VERSION ""

NS_ :

BS_:

BU_:

BO_ 2566834833 DM01_for_Multi_SA91: 42 Vector__XXX
 SG_ FECA_10_SPNConversionMethod : 335|1@1+ (1,0) [0|1] "" Vector__XXX
 SG_ FECA_10_SPN3 : 325|3@1+ (1,0) [0|7] "" Vector__XXX
 SG_ FECA_10_SPN1_2 : 304|16@1+ (1,0) [0|65535] "" Vector__XXX
 SG_ FECA_10_OccurenceCount : 328|7@1+ (1,0) [0|127] "" Vector__XXX
 SG_ FECA_10_FMI : 320|5@1+ (1,0) [0|31] "" Vector__XXX
 SG_ FECA_09_SPNConversionMethod : 303|1@1+ (1,0) [0|1] "" Vector__XXX
 SG_ FECA_09_SPN3 : 293|3@1+ (1,0) [0|7] "" Vector__XXX
 SG_ FECA_09_SPN1_2 : 272|16@1+ (1,0) [0|65535] "" Vector__XXX
 SG_ FECA_09_OccurenceCount : 296|7@1+ (1,0) [0|127] "" Vector__XXX
 SG_ FECA_09_FMI : 288|5@1+ (1,0) [0|31] "" Vector__XXX
 SG_ FECA_08_SPNConversionMethod : 271|1@1+ (1,0) [0|1] "" Vector__XXX
 SG_ FECA_08_SPN3 : 261|3@1+ (1,0) [0|7] "" Vector__XXX
 SG_ FECA_08_SPN1_2 : 240|16@1+ (1,0) [0|65535] "" Vector__XXX
 SG_ FECA_08_OccurenceCount : 264|7@1+ (1,0) [0|127] "" Vector__XXX
 SG_ FECA_08_FMI : 256|5@1+ (1,0) [0|31] "" Vector__XXX
 SG_ FECA_07_SPNConversionMethod : 239|1@1+ (1,0) [0|1] "" Vector__XXX
 SG_ FECA_07_SPN3 : 229|3@1+ (1,0) [0|7] "" Vector__XXX
 SG_ FECA_07_SPN1_2 : 208|16@1+ (1,0) [0|65535] "" Vector__XXX
 SG_ FECA_07_OccurenceCount : 232|7@1+ (1,0) [0|127] "" Vector__XXX
 SG_ FECA_07_FMI : 224|5@1+ (1,0) [0|31] "" Vector__XXX
 SG_ FECA_06_SPNConversionMethod : 207|1@1+ (1,0) [0|1] "" Vector__XXX
 SG_ FECA_06_SPN3 : 197|3@1+ (1,0) [0|7] "" Vector__XXX
 SG_ FECA_06_SPN1_2 : 176|16@1+ (1,0) [0|65535] "" Vector__XXX
 SG_ FECA_06_OccurenceCount : 200|7@1+ (1,0) [0|127] "" Vector__XXX
 SG_ FECA_06_FMI : 192|5@1+ (1,0) [0|31] "" Vector__XXX
 SG_ FECA_05_SPNConversionMethod : 175|1@1+ (1,0) [0|1] "" Vector__XXX
 SG_ FECA_05_SPN3 : 165|3@1+ (1,0) [0|7] "" Vector__XXX
 SG_ FECA_05_SPN1_2 : 144|16@1+ (1,0) [0|65535] "" Vector__XXX
 SG_ FECA_05_OccurenceCount : 168|7@1+ (1,0) [0|127] "" Vector__XXX
 SG_ FECA_05_FMI : 160|5@1+ (1,0) [0|31] "" Vector__XXX
 SG_ FECA_04_SPNConversionMethod : 143|1@1+ (1,0) [0|1] "" Vector__XXX
 SG_ FECA_04_SPN3 : 133|3@1+ (1,0) [0|7] "" Vector__XXX
 SG_ FECA_04_SPN1_2 : 112|16@1+ (1,0) [0|65535] "" Vector__XXX
 SG_ FECA_04_OccurenceCount : 136|7@1+ (1,0) [0|127] "" Vector__XXX
 SG_ FECA_04_FMI : 128|5@1+ (1,0) [0|31] "" Vector__XXX
 SG_ FECA_03_SPNConversionMethod : 111|1@1+ (1,0) [0|1] "" Vector__XXX
 SG_ FECA_03_SPN3 : 101|3@1+ (1,0) [0|7] "" Vector__XXX
 SG_ FECA_03_SPN1_2 : 80|16@1+ (1,0) [0|65535] "" Vector__XXX
 SG_ FECA_03_OccurenceCount : 104|7@1+ (1,0) [0|127] "" Vector__XXX
 SG_ FECA_03_FMI : 96|5@1+ (1,0) [0|31] "" Vector__XXX
 SG_ FECA_02_SPNConversionMethod : 79|1@1+ (1,0) [0|1] "" Vector__XXX
 SG_ FECA_02_SPN3 : 69|3@1+ (1,0) [0|7] "" Vector__XXX
 SG_ FECA_02_SPN1_2 : 48|16@1+ (1,0) [0|65535] "" Vector__XXX
 SG_ FECA_02_OccurenceCount : 72|7@1+ (1,0) [0|127] "" Vector__XXX
 SG_ FECA_02_FMI : 64|5@1+ (1,0) [0|31] "" Vector__XXX
 SG_ FECA_01_SPNConversionMethod : 47|1@1+ (1,0) [0|1] "" Vector__XXX
 SG_ FECA_01_SPN3 : 37|3@1+ (1,0) [0|7] "" Vector__XXX
 SG_ FECA_01_SPN1_2 : 16|16@1+ (1,0) [0|65535] "" Vector__XXX
 SG_ FECA_01_RedStopLampStatus : 4|2@1+ (1,0) [0|3] "" Vector__XXX
 SG_ FECA_01_ProtectLampStatus : 0|2@1+ (1,0) [0|3] "" Vector__XXX
 SG_ FECA_01_OccurenceCount : 40|7@1+ (1,0) [0|127] "" Vector__XXX
 SG_ FECA_01_MalFucIndicatorStatus : 6|2@1+ (1,0) [0|3] "" Vector__XXX
 SG_ FECA_01_FMI : 32|5@1+ (1,0) [0|31] "" Vector__XXX
 SG_ FECA_01_FlashRedStopLamp : 12|2@1+ (1,0) [0|3] "" Vector__XXX
 SG_ FECA_01_FlashProtectLamp : 8|2@1+ (1,0) [0|3] "" Vector__XXX
 SG_ FECA_01_FlashAmberLamp : 10|2@1+ (1,0) [0|3] "" Vector__XXX
 SG_ FECA_01_Flash_MalFuncIndiLamp : 14|2@1+ (1,0) [0|3] "" Vector__XXX
 SG_ FECA_01_AmberWarmingLampStatus : 2|2@1+ (1,0) [0|3] "" Vector__XXX

BO_ 2564816896 ECU_CM1: 8 Vector__XXX
 SG_ E000_AtRegenForceSW : 42|2@1+ (1,0) [0|3] "" Vector__XXX
 SG_ E000_AtRegenInhibitSW : 40|2@1+ (1,0) [0|3] "" Vector__XXX

BO_ 2633939200 ECU_TFI: 48 Vector__XXX
 SG_ FEB9_TripVehiIdleFuelUsed : 96|32@1+ (0.5,0) [0|2105540607.5] "L" Vector__XXX

BO_ 2633936896 ECU_TTI2: 16 Vector__XXX
 SG_ FEB0_TripidleTime : 96|32@1+ (0.05,0) [0|210554060.75] "hr" Vector__XXX
 SG_ FEB0_TripEngRunningTime : 64|32@1+ (0.05,0) [0|210554060.75] "hr" Vector__XXX

BO_ 2633927680 ECU_AAI: 8 Vector__XXX
 SG_ FE8C_AuxPress1 : 16|8@1+ (16,0) [0|4000] "kPa" Vector__XXX
 SG_ FE8C_AuxTemp2 : 8|8@1+ (1,-40) [-40|210] "C" Vector__XXX
 SG_ FE8C_AuxTemp1 : 0|8@1+ (1,-40) [-40|210] "%" Vector__XXX

BO_ 2566754816 ECU_EOI: 8 Vector__XXX
 SG_ FD92_EngOperState : 0|4@1+ (1,0) [0|15] "" Vector__XXX

BO_ 2565874577 ECU_ATS1SCRDSI1_SA91: 8 Vector__XXX
 SG_ F023_AT1SCRSysState : 16|4@1+ (1,0) [0|15] "" Vector__XXX

BO_ 2566699921 ECU_A1ECU_SA91: 8 Vector__XXX
 SG_ FCBB_AT1DEFCM1PowerSupply1 : 2|2@1+ (1,0) [0|3] "" Vector__XXX
 SG_ FCBB_AT1DEFCM1RelayCTRL : 0|2@1+ (1,0) [0|3] "" Vector__XXX

BO_ 2566708881 ECU_AT1AC3_SA91: 8 Vector__XXX
 SG_ FCDE_AT1SeAirAbPress : 0|16@1+ (0.1,0) [0|6553.5] "kPa" Vector__XXX

BO_ 2566810112 ECU_EFS: 7 Vector__XXX
 SG_ FE6A_EGFuelFilter_Diff_Pressure : 16|8@1+ (1,0) [0|255] "" Vector__XXX
 SG_ FE6A_FuelPumpPriStatus : 51|2@1+ (1,0) [0|3] "" Vector__XXX

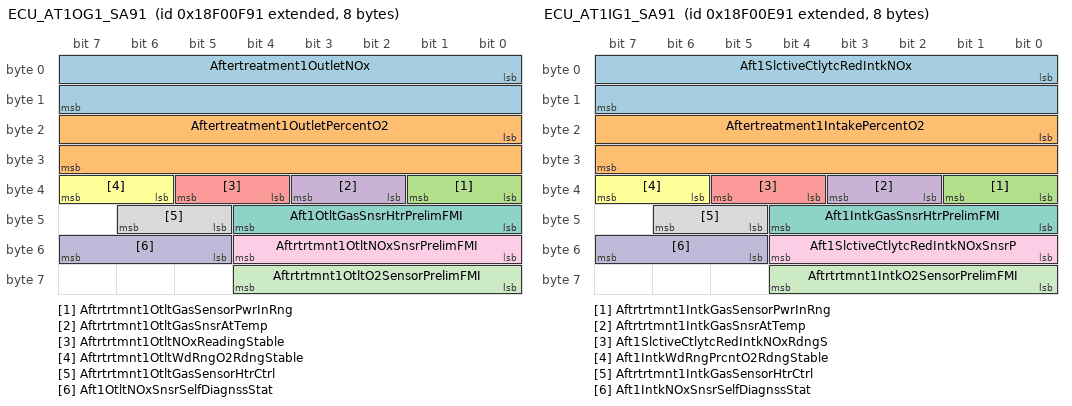
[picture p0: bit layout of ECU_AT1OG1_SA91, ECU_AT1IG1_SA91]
BO_ 2565869457 ECU_AT1OG1_SA91: 8 Vector__XXX
 SG_ Aftertreatment1OutletNOx : 0|16@1+ (0.05,-200) [-200|3012.75] "ppm" Vector__XXX
 SG_ Aftertreatment1OutletPercentO2 : 16|16@1+ (0.000514,-12) [-12|21.02707] "%" Vector__XXX
 SG_ Aftrtrtmnt1OtltGasSensorPwrInRng : 32|2@1+ (1,0) [0|3] "" Vector__XXX
 SG_ Aftrtrtmnt1OtltGasSnsrAtTemp : 34|2@1+ (1,0) [0|3] "" Vector__XXX
 SG_ Aftrtrtmnt1OtltNOxReadingStable : 36|2@1+ (1,0) [0|3] "" Vector__XXX
 SG_ Aftrtrtmnt1OtltWdRngO2RdngStable : 38|2@1+ (1,0) [0|3] "" Vector__XXX
 SG_ Aft1OtltGasSnsrHtrPrelimFMI : 40|5@1+ (1,0) [0|31] "" Vector__XXX
 SG_ Aftrtrtmnt1OtltGasSensorHtrCtrl : 45|2@1+ (1,0) [0|3] "" Vector__XXX
 SG_ Aftrtrtmnt1OtltNOxSnsrPrelimFMI : 48|5@1+ (1,0) [0|31] "" Vector__XXX
 SG_ Aft1OtltNOxSnsrSelfDiagnssStat : 53|3@1+ (1,0) [0|7] "" Vector__XXX
 SG_ Aftrtrtmnt1OtltO2SensorPrelimFMI : 56|5@1+ (1,0) [0|31] "" Vector__XXX

BO_ 2565869201 ECU_AT1IG1_SA91: 8 Vector__XXX
 SG_ Aft1SlctiveCtlytcRedIntkNOx : 0|16@1+ (0.05,-200) [-200|3012.75] "ppm" Vector__XXX
 SG_ Aftertreatment1IntakePercentO2 : 16|16@1+ (0.000514,-12) [-12|21.02707] "%" Vector__XXX
 SG_ Aftrtrtmnt1IntkGasSensorPwrInRng : 32|2@1+ (1,0) [0|3] "" Vector__XXX
 SG_ Aftrtrtmnt1IntkGasSnsrAtTemp : 34|2@1+ (1,0) [0|3] "" Vector__XXX
 SG_ Aft1SlctiveCtlytcRedIntkNOxRdngS : 36|2@1+ (1,0) [0|3] "" Vector__XXX
 SG_ Aft1IntkWdRngPrcntO2RdngStable : 38|2@1+ (1,0) [0|3] "" Vector__XXX
 SG_ Aft1IntkGasSnsrHtrPrelimFMI : 40|5@1+ (1,0) [0|31] "" Vector__XXX
 SG_ Aftrtrtmnt1IntkGasSensorHtrCtrl : 45|2@1+ (1,0) [0|3] "" Vector__XXX
 SG_ Aft1SlctiveCtlytcRedIntkNOxSnsrP : 48|5@1+ (1,0) [0|31] "" Vector__XXX
 SG_ Aft1IntkNOxSnsrSelfDiagnssStat : 53|3@1+ (1,0) [0|7] "" Vector__XXX
 SG_ Aftrtrtmnt1IntkO2SensorPrelimFMI : 56|5@1+ (1,0) [0|31] "" Vector__XXX

BO_ 2566766848 ECU_EFL_P3: 8 Vector__XXX
 SG_ FDC1_EngExGasRecir1IntakePress : 16|8@1+ (1,0) [0|255] "kPa" Vector__XXX

BO_ 2566713088 ECU_EFLP11: 8 Vector__XXX
 SG_ FCEF_EngEXGasReCir1IntakeAbPress : 0|16@1+ (0.1,0) [0|6425.5] "" Vector__XXX

BO_ 2566757632 ECU_SensorElecPower1: 8 Vector__XXX
 SG_ FD9D_SensorSupplyVol2 : 16|16@1+ (0.05,0) [0|3212.75] "V" Vector__XXX
 SG_ FD9D_SensorSupplyVol1 : 0|16@1+ (0.05,0) [0|3212.75] "V" Vector__XXX

BO_ 2566757777 ECU_SensorElecPower1_SA91: 8 Vector__XXX
 SG_ FD9D_SensorSupplyVol2 : 16|16@1+ (0.05,0) [0|3212.75] "V" Vector__XXX
 SG_ FD9D_SensorSupplyVol1 : 0|16@1+ (0.05,0) [0|3212.75] "V" Vector__XXX

BO_ 2566743441 ECU_ATS1FC2_SA91: 8 Vector__XXX
 SG_ FD65_AT1FuelFlowPress2ActCTRL : 24|16@1+ (0.0025,0) [0|160.6375] "%" Vector__XXX
 SG_ FD65_AT1FuelFlowDiverValveCTRL : 18|2@1+ (1,0) [0|3] "" Vector__XXX
 SG_ FD65_AT1FuelPumpRelayCTRL : 16|2@1+ (1,0) [0|3] "" Vector__XXX
 SG_ FD65_AT1FuelPress2 : 0|16@1+ (0.1,0) [0|6425.5] "kPa" Vector__XXX

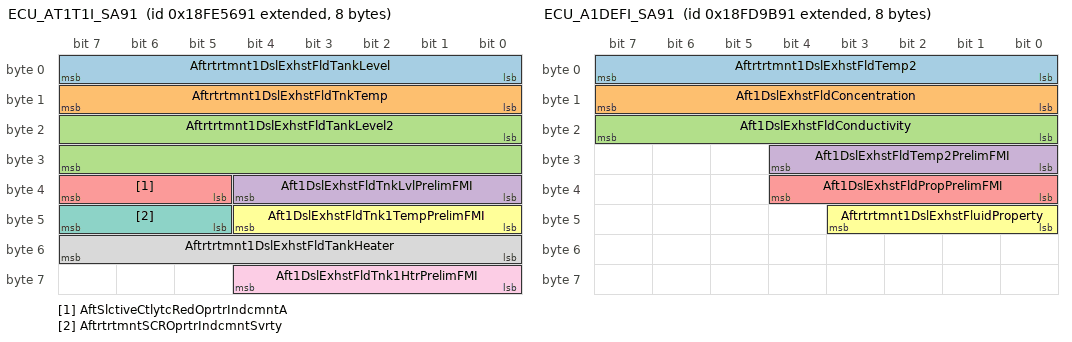
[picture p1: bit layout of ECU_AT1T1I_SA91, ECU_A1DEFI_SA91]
BO_ 2566805137 ECU_AT1T1I_SA91: 8 Vector__XXX
 SG_ Aftrtrtmnt1DslExhstFldTankLevel : 0|8@1+ (0.4,0) [0|100] "%" Vector__XXX
 SG_ Aftrtrtmnt1DslExhstFldTnkTemp : 8|8@1+ (1,-40) [-40|210] "deg C" Vector__XXX
 SG_ Aftrtrtmnt1DslExhstFldTankLevel2 : 16|16@1+ (0.1,0) [0|6425.5] "mm" Vector__XXX
 SG_ Aft1DslExhstFldTnkLvlPrelimFMI : 32|5@1+ (1,0) [0|31] "" Vector__XXX
 SG_ AftSlctiveCtlytcRedOprtrIndcmntA : 37|3@1+ (1,0) [0|7] "" Vector__XXX
 SG_ Aft1DslExhstFldTnk1TempPrelimFMI : 40|5@1+ (1,0) [0|31] "" Vector__XXX
 SG_ AftrtrtmntSCROprtrIndcmntSvrty : 45|3@1+ (1,0) [0|7] "" Vector__XXX
 SG_ Aftrtrtmnt1DslExhstFldTankHeater : 48|8@1+ (0.4,0) [0|100] "%" Vector__XXX
 SG_ Aft1DslExhstFldTnk1HtrPrelimFMI : 56|5@1+ (1,0) [0|31] "" Vector__XXX

BO_ 2566757265 ECU_A1DEFI_SA91: 8 Vector__XXX
 SG_ Aftrtrtmnt1DslExhstFldTemp2 : 0|8@1+ (1,-40) [-40|210] "deg C" Vector__XXX
 SG_ Aft1DslExhstFldConcentration : 8|8@1+ (0.25,0) [0|62.5] "%" Vector__XXX
 SG_ Aft1DslExhstFldConductivity : 16|8@1+ (5,0) [0|1250] "uS/mm" Vector__XXX
 SG_ Aft1DslExhstFldTemp2PrelimFMI : 24|5@1+ (1,0) [0|31] "" Vector__XXX
 SG_ Aft1DslExhstFldPropPrelimFMI : 32|5@1+ (1,0) [0|31] "" Vector__XXX
 SG_ Aftrtrtmnt1DslExhstFluidProperty : 40|4@1+ (1,0) [0|15] "" Vector__XXX

BO_ 2566733457 ECU_ATS1SCRExGasTemp_SA91: 8 Vector__XXX
 SG_ FD3E_ATS1SCRcataOurtakeGasTemp : 24|16@1+ (0.03125,-273) [-273|1734.96875] "C" Vector__XXX
 SG_ FD3E_ATS1SCRcataIntakeGasTemp : 0|16@1+ (0.03125,-273) [-273|1734.96875] "C" Vector__XXX

BO_ 2566770688 ECU_InExhaustCond2: 8 Vector__XXX
 SG_ FDD0_EngIntakeMani1AbPress : 40|8@1+ (2,0) [0|500] "kPa" Vector__XXX

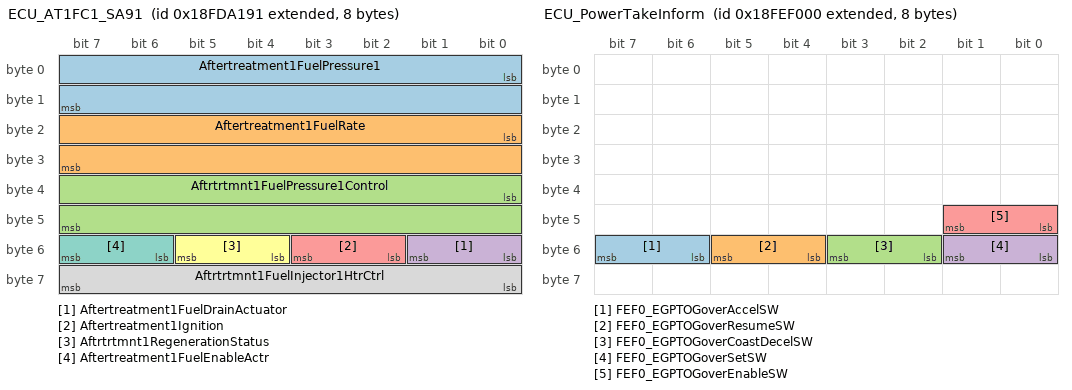
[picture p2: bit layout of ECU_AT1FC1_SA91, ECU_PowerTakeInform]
BO_ 2566758801 ECU_AT1FC1_SA91: 8 Vector__XXX
 SG_ Aftertreatment1FuelPressure1 : 0|16@1+ (0.1,0) [0|6425.5] "kPa" Vector__XXX
 SG_ Aftertreatment1FuelRate : 16|16@1+ (0.05,0) [0|3212.75] "l/h" Vector__XXX
 SG_ Aftrtrtmnt1FuelPressure1Control : 32|16@1+ (0.0025,0) [0|160.6375] "%" Vector__XXX
 SG_ Aftertreatment1FuelDrainActuator : 48|2@1+ (1,0) [0|3] "" Vector__XXX
 SG_ Aftertreatment1Ignition : 50|2@1+ (1,0) [0|3] "" Vector__XXX
 SG_ Aftrtrtmnt1RegenerationStatus : 52|2@1+ (1,0) [0|3] "" Vector__XXX
 SG_ Aftertreatment1FuelEnableActr : 54|2@1+ (1,0) [0|3] "" Vector__XXX
 SG_ Aftrtrtmnt1FuelInjector1HtrCtrl : 56|8@1+ (0.4,0) [0|100] "%" Vector__XXX

BO_ 2566763409 ECU_AT1OG2_SA91: 8 Vector__XXX
 SG_ Aftrtrtmnt1ExhaustTemperature3 : 0|16@1+ (0.03125,-273) [-273|1734.96875] "deg C" Vector__XXX
 SG_ Aftrtrtmnt1DslPFOtltTemperature : 16|16@1+ (0.03125,-273) [-273|1734.96875] "deg C" Vector__XXX
 SG_ Aftrtrtmnt1ExhstTemp3PrelimFMI : 32|5@1+ (1,0) [0|31] "" Vector__XXX
 SG_ Aft1DslPFOtltExhstTempPrelimFMI : 40|5@1+ (1,0) [0|31] "" Vector__XXX

BO_ 2566825472 ECU_IntakeManiInform1: 8 Vector__XXX
 SG_ FEA6_EGturbo1BoostPress : 0|16@1+ (0.125,0) [0|8031.875] "kPa" Vector__XXX

BO_ 2566844416 ECU_PowerTakeInform: 8 Vector__XXX
 SG_ FEF0_EGPTOGoverAccelSW : 54|2@1+ (1,0) [0|3] "" Vector__XXX
 SG_ FEF0_EGPTOGoverResumeSW : 52|2@1+ (1,0) [0|3] "" Vector__XXX
 SG_ FEF0_EGPTOGoverCoastDecelSW : 50|2@1+ (1,0) [0|3] "" Vector__XXX
 SG_ FEF0_EGPTOGoverSetSW : 48|2@1+ (1,0) [0|3] "" Vector__XXX
 SG_ FEF0_EGPTOGoverEnableSW : 40|2@1+ (1,0) [0|3] "" Vector__XXX

BO_ 2566768640 ECU_OperPriInterApeedCTRLState: 8 Vector__XXX
 SG_ FDC8_BaroPress : 0|4@1+ (1,0) [0|15] "state" Vector__XXX

BO_ 2566809856 ECU_ET3: 8 Vector__XXX
 SG_ FE69_EngCAC1OutTemp : 48|16@1+ (0.03125,-273) [-273|1734.96875] "C" Vector__XXX

BO_ 2566708992 ECU_EFLP12EFL_P12: 8 Vector__XXX
 SG_ FCDF_EGFilFuelDeliAbPress : 16|8@1+ (4,0) [0|1000] "kPa" Vector__XXX
 SG_ FCDF_EGFilFuelDeliPress : 8|8@1+ (4,0) [0|1000] "kPa" Vector__XXX

BO_ 2566824960 ECU_ET2: 8 Vector__XXX
 SG_ FEA4_EGexhaust1Temp : 48|16@1+ (0.03125,-273) [-273|1734.96875] "C" Vector__XXX
 SG_ FEA4_EGexhaustGR1DP : 32|16@1+ (0.0078125,-250) [-250|251.99] "kPa" Vector__XXX

BO_ 2566763665 ECU_AT1IG2_SA91: 8 Vector__XXX
 SG_ Aftrtrtmnt1ExhaustTemperature1 : 0|16@1+ (0.03125,-273) [-273|1734.96875] "deg C" Vector__XXX
 SG_ Aftrtrtmnt1DslPFIntkTemperature : 16|16@1+ (0.03125,-273) [-273|1734.96875] "deg C" Vector__XXX
 SG_ Aftrtrtmnt1ExhstTemp1PrelimFMI : 32|5@1+ (1,0) [0|31] "" Vector__XXX
 SG_ Aft1DslPFIntkTempPrelimFMI : 40|5@1+ (1,0) [0|31] "" Vector__XXX

BO_ 2566758289 ECU_ATS1AC1_SA91: 8 Vector__XXX
 SG_ FD9F_ATS1AirPressAP : 48|8@1+ (0.4,0) [0|100] "%" Vector__XXX
 SG_ FD9F_ATS1AirPressCTRL : 32|16@1+ (0.0025,0) [0|160.6375] "%" Vector__XXX

BO_ 2566753425 ECU_ATS1GasPara_SA91: 8 Vector__XXX
 SG_ FD8C_DPFIntakePress1 : 0|16@1+ (0.1,0) [0|6425.5] "kpa" Vector__XXX

BO_ 2566745489 ECU_ATS1AC2_SA91: 8 Vector__XXX
 SG_ FD6D_ATS12edAirPress : 48|16@1+ (0.1,0) [0|6425.5] "kPa" Vector__XXX
 SG_ FD6D_ATS12edAirMassFlow : 32|16@1+ (0.2,0) [0|12851] "kg" Vector__XXX

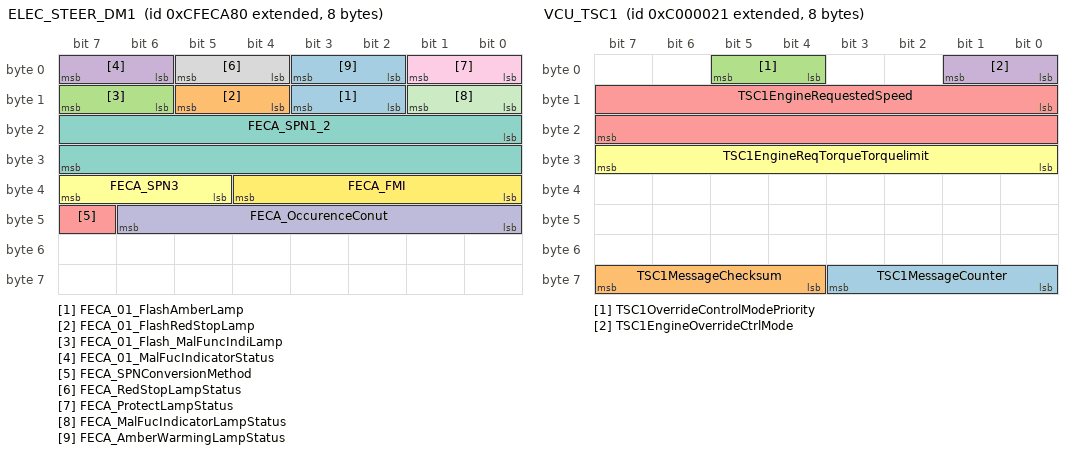
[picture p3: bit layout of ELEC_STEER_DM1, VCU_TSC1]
BO_ 2365508224 ELEC_STEER_DM1: 8 Vector__XXX
 SG_ FECA_01_FlashAmberLamp : 10|2@1+ (1,0) [0|3] "" Vector__XXX
 SG_ FECA_01_FlashRedStopLamp : 12|2@1+ (1,0) [0|3] "" Vector__XXX
 SG_ FECA_01_Flash_MalFuncIndiLamp : 14|2@1+ (1,0) [0|3] "" Vector__XXX
 SG_ FECA_01_MalFucIndicatorStatus : 6|2@1+ (1,0) [0|3] "" Vector__XXX
 SG_ FECA_SPNConversionMethod : 47|1@1+ (1,0) [0|1] "" Vector__XXX
 SG_ FECA_SPN3 : 37|3@1+ (1,0) [0|7] "" Vector__XXX
 SG_ FECA_SPN1_2 : 16|16@1+ (1,0) [0|65535] "" Vector__XXX
 SG_ FECA_RedStopLampStatus : 4|2@1+ (1,0) [0|3] "" Vector__XXX
 SG_ FECA_ProtectLampStatus : 0|2@1+ (1,0) [0|3] "" Vector__XXX
 SG_ FECA_OccurenceConut : 40|7@1+ (1,0) [0|127] "" Vector__XXX
 SG_ FECA_MalFucIndicatorLampStatus : 8|2@1+ (1,0) [0|3] "" Vector__XXX
 SG_ FECA_FMI : 32|5@1+ (1,0) [0|31] "" Vector__XXX
 SG_ FECA_AmberWarmingLampStatus : 2|2@1+ (1,0) [0|3] "" Vector__XXX

BO_ 2348810273 VCU_TSC1: 8 Vector__XXX
 SG_ TSC1MessageCounter : 56|4@1+ (1,0) [0|15] "" Vector__XXX
 SG_ TSC1MessageChecksum : 60|4@1+ (1,0) [0|15] "" Vector__XXX
 SG_ TSC1OverrideControlModePriority : 4|2@1+ (1,0) [0|3] "" Vector__XXX
 SG_ TSC1EngineOverrideCtrlMode : 0|2@1+ (1,0) [0|3] "" Vector__XXX
 SG_ TSC1EngineRequestedSpeed : 8|16@1+ (0.125,0) [0|8031.875] "rpm" Vector__XXX
 SG_ TSC1EngineReqTorqueTorquelimit : 24|8@1+ (1,-125) [-125|125] "%" Vector__XXX

BO_ 2365543464 GP_KeypadA_OperateSignal: 8 Vector__XXX
 SG_ FF54_ThrottleLockUp : 37|1@1+ (1,0) [0|1] "" Vector__XXX
 SG_ FF54_TractionControlMode : 36|1@1+ (1,0) [0|1] "" Vector__XXX
 SG_ FF54_VariableSpeedDown : 35|1@1+ (1,0) [0|1] "" Vector__XXX
 SG_ FF54_VariableSpeedUp : 34|1@1+ (1,0) [0|1] "" Vector__XXX
 SG_ FF54_TrsmModeSelect : 29|1@1+ (1,0) [0|1] "" Vector__XXX
 SG_ FF54_TorqueConverterLockUp : 31|1@1+ (1,0) [0|1] "" Vector__XXX
 SG_ FF54_ClutchCutOff : 30|1@1+ (1,0) [0|1] "" Vector__XXX
 SG_ FF54_RearWorkingLamp : 2|1@1+ (1,0) [0|1] "" Vector__XXX
 SG_ FF54_RearWiperAndWasher : 6|1@1+ (1,0) [0|1] "" Vector__XXX
 SG_ FF54_ModeSelect : 17|1@1+ (1,0) [0|1] "" Vector__XXX
 SG_ FF54_MirrorHeat : 7|1@1+ (1,0) [0|1] "" Vector__XXX
 SG_ FF54_MenuHelp : 16|1@1+ (1,0) [0|1] "" Vector__XXX
 SG_ FF54_MaxSpeedUp : 33|1@1+ (1,0) [0|1] "" Vector__XXX
 SG_ FF54_MaxSpeedDown : 32|1@1+ (1,0) [0|1] "" Vector__XXX
 SG_ FF54_LoadIsolation : 18|1@1+ (1,0) [0|1] "" Vector__XXX
 SG_ FF54_HeadLamp : 0|1@1+ (1,0) [0|1] "" Vector__XXX
 SG_ FF54_FrontWorkingLamp : 1|1@1+ (1,0) [0|1] "" Vector__XXX
 SG_ FF54_EmergencySteering : 21|1@1+ (1,0) [0|1] "" Vector__XXX
 SG_ FF54_DifferentialLockEngaged : 22|1@1+ (1,0) [0|1] "" Vector__XXX
 SG_ FF54_BucketDetent : 20|1@1+ (1,0) [0|1] "" Vector__XXX
 SG_ FF54_BoomDetent : 19|1@1+ (1,0) [0|1] "" Vector__XXX
 SG_ FF54_BeaconLamp : 3|1@1+ (1,0) [0|1] "" Vector__XXX

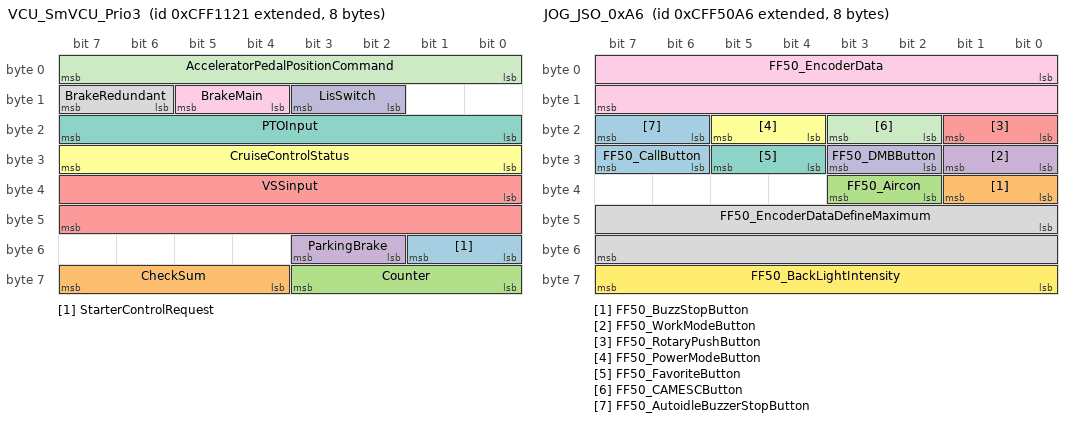
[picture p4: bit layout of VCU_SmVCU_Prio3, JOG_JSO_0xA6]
BO_ 2365526305 VCU_SmVCU_Prio3: 8 Vector__XXX
 SG_ StarterControlRequest : 48|2@1+ (1,0) [0|3] "State" Vector__XXX
 SG_ CheckSum : 60|4@1+ (1,0) [0|15] "State" Vector__XXX
 SG_ Counter : 56|4@1+ (1,0) [0|15] "State" Vector__XXX
 SG_ ParkingBrake : 50|2@1+ (1,0) [0|3] "State" Vector__XXX
 SG_ VSSinput : 32|16@1+ (1,0) [0|65535] "State" Vector__XXX
 SG_ CruiseControlStatus : 24|8@1+ (1,0) [0|255] "State" Vector__XXX
 SG_ PTOInput : 16|8@1+ (1,0) [0|255] "State" Vector__XXX
 SG_ BrakeRedundant : 14|2@1+ (1,0) [0|3] "State" Vector__XXX
 SG_ BrakeMain : 12|2@1+ (1,0) [0|3] "State" Vector__XXX
 SG_ LisSwitch : 10|2@1+ (1,0) [0|3] "State" Vector__XXX
 SG_ AcceleratorPedalPositionCommand : 0|8@1+ (0.4,0) [0|102] "%" Vector__XXX

BO_ 2365542566 JOG_JSO_0xA6: 8 Vector__XXX
 SG_ FF50_CallButton : 30|2@1+ (1,0) [0|3] "" Vector__XXX
 SG_ FF50_BuzzStopButton : 32|2@1+ (1,0) [0|3] "" Vector__XXX
 SG_ FF50_Aircon : 34|2@1+ (1,0) [0|3] "" Vector__XXX
 SG_ FF50_WorkModeButton : 24|2@1+ (1,0) [0|3] "" Vector__XXX
 SG_ FF50_RotaryPushButton : 16|2@1+ (1,0) [0|3] "" Vector__XXX
 SG_ FF50_PowerModeButton : 20|2@1+ (1,0) [0|3] "" Vector__XXX
 SG_ FF50_FavoriteButton : 28|2@1+ (1,0) [0|3] "" Vector__XXX
 SG_ FF50_EncoderDataDefineMaximum : 40|16@1+ (1,0) [0|65535] "" Vector__XXX
 SG_ FF50_EncoderData : 0|16@1+ (1,0) [0|65535] "" Vector__XXX
 SG_ FF50_DMBButton : 26|2@1+ (1,0) [0|3] "" Vector__XXX
 SG_ FF50_CAMESCButton : 18|2@1+ (1,0) [0|3] "" Vector__XXX
 SG_ FF50_BackLightIntensity : 56|8@1+ (1,0) [0|255] "" Vector__XXX
 SG_ FF50_AutoidleBuzzerStopButton : 22|2@1+ (1,0) [0|3] "" Vector__XXX

BO_ 2566895393 VCU_ADC: 8 Vector__XXX
 SG_ FFB7_DesorptionGrantedStatus : 0|2@1+ (1,0) [0|3] "" Vector__XXX

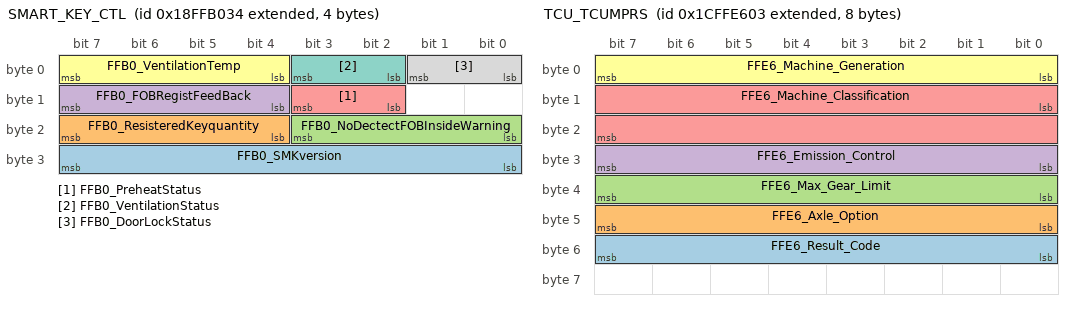
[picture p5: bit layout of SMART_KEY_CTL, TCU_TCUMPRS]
BO_ 2566893620 SMART_KEY_CTL: 4 Vector__XXX
 SG_ FFB0_SMKversion : 24|8@1+ (1,0) [0|255] "" Vector__XXX
 SG_ FFB0_ResisteredKeyquantity : 20|4@1+ (1,0) [0|15] "" Vector__XXX
 SG_ FFB0_NoDectectFOBInsideWarning : 16|4@1+ (1,0) [0|15] "" Vector__XXX
 SG_ FFB0_FOBRegistFeedBack : 12|4@1+ (1,0) [0|15] "" Vector__XXX
 SG_ FFB0_PreheatStatus : 10|2@1+ (1,0) [0|3] "" Vector__XXX
 SG_ FFB0_VentilationTemp : 4|4@1+ (1,0) [0|15] "" Vector__XXX
 SG_ FFB0_VentilationStatus : 2|2@1+ (1,0) [0|3] "" Vector__XXX
 SG_ FFB0_DoorLockStatus : 0|2@1+ (1,0) [0|3] "" Vector__XXX

BO_ 2565472296 GP_RQST_SA28_DA00: 3 Vector__XXX
 SG_ ParameterGroupNumber : 0|24@1+ (1,0) [0|16777215] "" Vector__XXX

BO_ 2634016259 TCU_TCUMPRS: 8 Vector__XXX
 SG_ FFE6_Result_Code : 48|8@1+ (1,0) [0|255] "" Vector__XXX
 SG_ FFE6_Axle_Option : 40|8@1+ (1,0) [0|255] "" Vector__XXX
 SG_ FFE6_Max_Gear_Limit : 32|8@1+ (1,0) [0|255] "" Vector__XXX
 SG_ FFE6_Emission_Control : 24|8@1+ (1,0) [0|255] "" Vector__XXX
 SG_ FFE6_Machine_Classification : 8|16@1+ (0.1,0) [0|6502.3] "" Vector__XXX
 SG_ FFE6_Machine_Generation : 0|8@1+ (1,0) [0|255] "" Vector__XXX

BO_ 2566907169 VCU_SWVER: 8 Vector__XXX
 SG_ FFE5_VCU_SW_Version_Year : 48|8@1+ (1,0) [0|255] "" Vector__XXX
 SG_ FFE5_VCU_SW_Version_Day : 40|8@1+ (1,0) [0|255] "" Vector__XXX
 SG_ FFE5_VCU_SW_Version_Month : 32|8@1+ (1,0) [0|255] "" Vector__XXX
 SG_ FFE5_VCU_SW_Version : 0|32@1+ (1,0) [0|4294967295] "" Vector__XXX

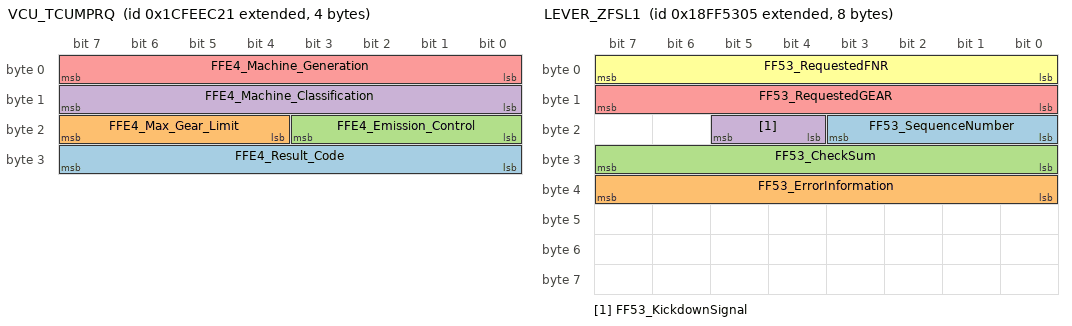
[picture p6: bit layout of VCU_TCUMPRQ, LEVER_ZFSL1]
BO_ 2633952289 VCU_TCUMPRQ: 4 Vector__XXX
 SG_ FFE4_Result_Code : 24|8@1+ (1,0) [0|255] "" Vector__XXX
 SG_ FFE4_Max_Gear_Limit : 20|4@1+ (1,0) [0|15] "" Vector__XXX
 SG_ FFE4_Emission_Control : 16|4@1+ (1,0) [0|15] "" Vector__XXX
 SG_ FFE4_Machine_Classification : 8|8@1+ (10,0) [0|2550] "" Vector__XXX
 SG_ FFE4_Machine_Generation : 0|8@1+ (1,0) [0|255] "" Vector__XXX

BO_ 2566869765 LEVER_ZFSL1: 8 Vector__XXX
 SG_ FF53_SequenceNumber : 16|4@1+ (1,0) [0|15] "" Vector__XXX
 SG_ FF53_ErrorInformation : 32|8@1+ (1,0) [0|255] "" Vector__XXX
 SG_ FF53_CheckSum : 24|8@1+ (1,0) [0|255] "" Vector__XXX
 SG_ FF53_KickdownSignal : 20|2@1+ (1,0) [0|3] "" Vector__XXX
 SG_ FF53_RequestedGEAR : 8|8@1+ (1,0) [0|255] "" Vector__XXX
 SG_ FF53_RequestedFNR : 0|8@1+ (1,0) [0|255] "" Vector__XXX

BO_ 2365542696 GP_KeypadA_BrightnessAndOpMode: 8 Vector__XXX
 SG_ FF51_IIlluminationBrightness : 0|8@1+ (1,0) [0|255] "" Vector__XXX

BO_ 2365543201 VCU_KeypadA_Indicate1: 8 Vector__XXX
 SG_ FF53_ReverseFanRight : 60|2@1+ (1,0) [0|3] "" Vector__XXX
 SG_ FF53_ReverseFanLeft : 62|2@1+ (1,0) [0|3] "" Vector__XXX
 SG_ FF53_CabinLamp_Right : 54|2@1+ (1,0) [0|3] "" Vector__XXX
 SG_ FF53_CabinLamp_Left : 58|2@1+ (1,0) [0|3] "" Vector__XXX
 SG_ FF53_CabinLamp_Center : 56|2@1+ (1,0) [0|3] "" Vector__XXX
 SG_ FF53_RearWorkingLampRight : 12|2@1+ (1,0) [0|3] "" Vector__XXX
 SG_ FF53_RearWorkingLampLeft : 16|2@1+ (1,0) [0|3] "" Vector__XXX
 SG_ FF53_RearWorkingLampCenter : 14|2@1+ (1,0) [0|3] "" Vector__XXX
 SG_ FF53_RearWiperWasherRight : 24|2@1+ (1,0) [0|3] "" Vector__XXX
 SG_ FF53_RearWiperWasherLeft : 28|2@1+ (1,0) [0|3] "" Vector__XXX
 SG_ FF53_RearWiperWasherCenter : 26|2@1+ (1,0) [0|3] "" Vector__XXX
 SG_ FF53_MirrorHeatRight : 30|2@1+ (1,0) [0|3] "" Vector__XXX
 SG_ FF53_MirrorHeatLeft : 34|2@1+ (1,0) [0|3] "" Vector__XXX
 SG_ FF53_MirrorHeatCenter : 32|2@1+ (1,0) [0|3] "" Vector__XXX
 SG_ FF53_LoadIsolationRight : 36|2@1+ (1,0) [0|3] "" Vector__XXX
 SG_ FF53_LoadIsolationLeft : 40|2@1+ (1,0) [0|3] "" Vector__XXX
 SG_ FF53_LoadIsolationCenter : 38|2@1+ (1,0) [0|3] "" Vector__XXX
 SG_ FF53_InformationRight : 48|2@1+ (1,0) [0|3] "" Vector__XXX
 SG_ FF53_InformationLeft : 52|2@1+ (1,0) [0|3] "" Vector__XXX
 SG_ FF53_InformationCenter : 50|2@1+ (1,0) [0|3] "" Vector__XXX
 SG_ FF53_HeadLampRight : 0|2@1+ (1,0) [0|3] "" Vector__XXX
 SG_ FF53_HeadLampLeft : 4|2@1+ (1,0) [0|3] "" Vector__XXX
 SG_ FF53_HeadLampCenter : 2|2@1+ (1,0) [0|3] "" Vector__XXX
 SG_ FF53_FrontWorkingLampRight : 6|2@1+ (1,0) [0|3] "" Vector__XXX
 SG_ FF53_FrontWorkingLampLeft : 10|2@1+ (1,0) [0|3] "" Vector__XXX
 SG_ FF53_FrontWorkingLampCenter : 8|2@1+ (1,0) [0|3] "" Vector__XXX
 SG_ FF53_EmergencySteeringRight : 42|2@1+ (1,0) [0|3] "" Vector__XXX
 SG_ FF53_EmergencySteeringLeft : 46|2@1+ (1,0) [0|3] "" Vector__XXX
 SG_ FF53_EmergencySteeringCenter : 44|2@1+ (1,0) [0|3] "" Vector__XXX
 SG_ FF53_BeaconLampRight : 18|2@1+ (1,0) [0|3] "" Vector__XXX
 SG_ FF53_BeaconLampLeft : 22|2@1+ (1,0) [0|3] "" Vector__XXX
 SG_ FF53_BeaconLampCenter : 20|2@1+ (1,0) [0|3] "" Vector__XXX

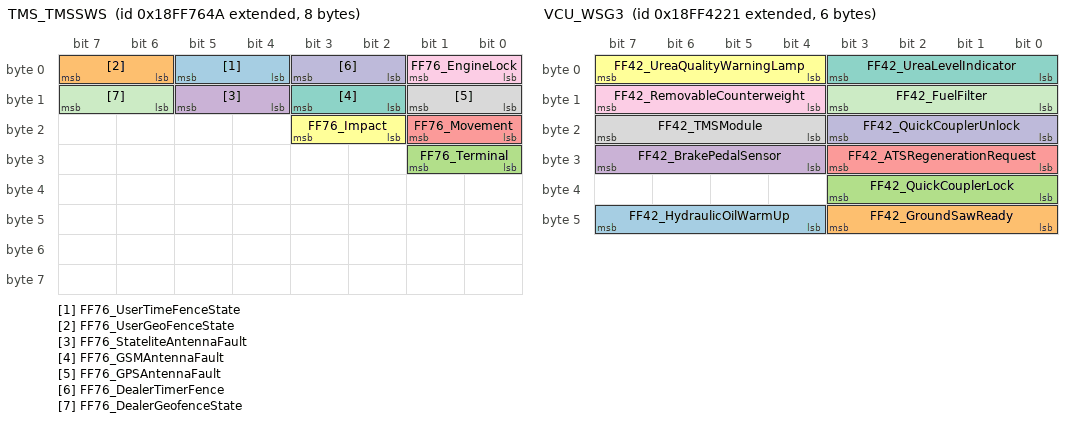
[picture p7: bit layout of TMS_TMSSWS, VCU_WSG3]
BO_ 2566878794 TMS_TMSSWS: 8 Vector__XXX
 SG_ FF76_UserTimeFenceState : 4|2@1+ (1,0) [0|3] "" Vector__XXX
 SG_ FF76_UserGeoFenceState : 6|2@1+ (1,0) [0|3] "" Vector__XXX
 SG_ FF76_Terminal : 24|2@1+ (1,0) [0|3] "" Vector__XXX
 SG_ FF76_StateliteAntennaFault : 12|2@1+ (1,0) [0|3] "" Vector__XXX
 SG_ FF76_Movement : 16|2@1+ (1,0) [0|3] "" Vector__XXX
 SG_ FF76_Impact : 18|2@1+ (1,0) [0|3] "" Vector__XXX
 SG_ FF76_GSMAntennaFault : 10|2@1+ (1,0) [0|3] "" Vector__XXX
 SG_ FF76_GPSAntennaFault : 8|2@1+ (1,0) [0|3] "" Vector__XXX
 SG_ FF76_EngineLock : 0|2@1+ (1,0) [0|3] "" Vector__XXX
 SG_ FF76_DealerTimerFence : 2|2@1+ (1,0) [0|3] "" Vector__XXX
 SG_ FF76_DealerGeofenceState : 14|2@1+ (1,0) [0|3] "" Vector__XXX

BO_ 2566905121 VCU_ASDI: 178 Vector__XXX
 SG_ FFDD_RotatingCurrentStep : 220|4@1+ (1,0) [0|15] "" Vector__XXX
 SG_ FFDD_TwoWayCurrentStep : 216|4@1+ (1,0) [0|15] "" Vector__XXX
 SG_ FFDD_TwoWayMinFlowATT4 : 1248|16@1+ (1,0) [0|65535] "" Vector__XXX
 SG_ FFDD_TwoWayMinFlowATT3 : 1232|16@1+ (1,0) [0|65535] "" Vector__XXX
 SG_ FFDD_TwoWayMinFlowATT2 : 1216|16@1+ (1,0) [0|65535] "" Vector__XXX
 SG_ FFDD_TwoWayMinFlowATT1 : 1200|16@1+ (1,0) [0|65535] "" Vector__XXX
 SG_ FFDD_TwoWayMinFlowATT0 : 1184|16@1+ (1,0) [0|65535] "" Vector__XXX
 SG_ FFDD_MinSpeed : 16|16@1+ (1,0) [0|65535] "" Vector__XXX
 SG_ FFDD_MinPressTwo : 80|16@1+ (1,0) [0|65535] "" Vector__XXX
 SG_ FFDD_MinPressOne : 48|16@1+ (1,0) [0|65535] "" Vector__XXX
 SG_ FFDD_MinFlow : 112|16@1+ (1,0) [0|65535] "" Vector__XXX
 SG_ FFDD_MaxSpeed : 32|16@1+ (1,0) [0|65535] "" Vector__XXX
 SG_ FFDD_MaxPressTwo : 96|16@1+ (1,0) [0|65535] "" Vector__XXX
 SG_ FFDD_MaxPressOne : 64|16@1+ (1,0) [0|65535] "" Vector__XXX
 SG_ FFDD_MaxFlow : 128|16@1+ (1,0) [0|65535] "" Vector__XXX
 SG_ FFDD_TwoWayUseFlow4 : 1408|16@1+ (1,0) [0|65535] "" Vector__XXX
 SG_ FFDD_TwoWayUseFlow3 : 1392|16@1+ (1,0) [0|65535] "" Vector__XXX
 SG_ FFDD_TwoWayUseFlow2 : 1376|16@1+ (1,0) [0|65535] "" Vector__XXX
 SG_ FFDD_TwoWayUseFlow1 : 1360|16@1+ (1,0) [0|65535] "" Vector__XXX
 SG_ FFDD_TwoWayUseFlow0 : 1344|16@1+ (1,0) [0|65535] "" Vector__XXX
 SG_ FFDD_TwoWaySetFlow4 : 1328|16@1+ (1,0) [0|65535] "" Vector__XXX
 SG_ FFDD_TwoWaySetFlow3 : 1312|16@1+ (1,0) [0|65535] "" Vector__XXX
 SG_ FFDD_TwoWaySetFlow2 : 1296|16@1+ (1,0) [0|65535] "" Vector__XXX
 SG_ FFDD_TwoWaySetFlow1 : 1280|16@1+ (1,0) [0|65535] "" Vector__XXX
 SG_ FFDD_TwoWaySetFlow0 : 1264|16@1+ (1,0) [0|65535] "" Vector__XXX
 SG_ FFDD_TwoWayRpm4 : 928|16@1+ (1,0) [0|65535] "" Vector__XXX
 SG_ FFDD_TwoWayRpm3 : 912|16@1+ (1,0) [0|65535] "" Vector__XXX
 SG_ FFDD_TwoWayRpm2 : 896|16@1+ (1,0) [0|65535] "" Vector__XXX
 SG_ FFDD_TwoWayRpm1 : 880|16@1+ (1,0) [0|65535] "" Vector__XXX
 SG_ FFDD_TwoWayRpm0 : 864|16@1+ (1,0) [0|65535] "" Vector__XXX
 SG_ FFDD_TwoWayPress4 : 1008|16@1+ (1,0) [0|65535] "" Vector__XXX
 SG_ FFDD_TwoWayPress3 : 992|16@1+ (1,0) [0|65535] "" Vector__XXX
 SG_ FFDD_TwoWayPress2 : 976|16@1+ (1,0) [0|65535] "" Vector__XXX
 SG_ FFDD_TwoWayPress1 : 960|16@1+ (1,0) [0|65535] "" Vector__XXX
 SG_ FFDD_TwoWayPress0 : 944|16@1+ (1,0) [0|65535] "" Vector__XXX
 SG_ FFDD_TwoWayMaxFlowPump4 : 1088|16@1+ (1,0) [0|65535] "" Vector__XXX
 SG_ FFDD_TwoWayMaxFlowPump3 : 1072|16@1+ (1,0) [0|65535] "" Vector__XXX
 SG_ FFDD_TwoWayMaxFlowPump2 : 1056|16@1+ (1,0) [0|65535] "" Vector__XXX
 SG_ FFDD_TwoWayMaxFlowPump1 : 1040|16@1+ (1,0) [0|65535] "" Vector__XXX
 SG_ FFDD_TwoWayMaxFlowPump0 : 1024|16@1+ (1,0) [0|65535] "" Vector__XXX
 SG_ FFDD_TwoWayMaxFlowATT4 : 1168|16@1+ (1,0) [0|65535] "" Vector__XXX
 SG_ FFDD_TwoWayMaxFlowATT3 : 1152|16@1+ (1,0) [0|65535] "" Vector__XXX
 SG_ FFDD_TwoWayMaxFlowATT2 : 1136|16@1+ (1,0) [0|65535] "" Vector__XXX
 SG_ FFDD_TwoWayMaxFlowATT1 : 1120|16@1+ (1,0) [0|65535] "" Vector__XXX
 SG_ FFDD_TwoWayMaxFlowATT0 : 1104|16@1+ (1,0) [0|65535] "" Vector__XXX
 SG_ FFDD_Twoway4_SelectedATTType : 848|1@1+ (1,0) [0|1] "" Vector__XXX
 SG_ FFDD_Twoway4_SelectedATTNumber : 849|3@1+ (1,0) [0|7] "" Vector__XXX
 SG_ FFDD_Twoway4_ThumbWheelType : 853|2@1+ (1,0) [0|3] "" Vector__XXX
 SG_ FFDD_Twoway4_2PumpOption : 852|1@1+ (1,0) [0|1] "" Vector__XXX
 SG_ FFDD_Twoway3_SelectedATTType : 832|1@1+ (1,0) [0|1] "" Vector__XXX
 SG_ FFDD_Twoway3_SelectedATTNumber : 833|3@1+ (1,0) [0|7] "" Vector__XXX
 SG_ FFDD_Twoway3_ThumbWheelType : 837|2@1+ (1,0) [0|3] "" Vector__XXX
 SG_ FFDD_Twoway3_2PumpOption : 836|1@1+ (1,0) [0|1] "" Vector__XXX
 SG_ FFDD_Twoway2_SelectedATTType : 816|1@1+ (1,0) [0|1] "" Vector__XXX
 SG_ FFDD_Twoway2_SelectedATTNumber : 817|3@1+ (1,0) [0|7] "" Vector__XXX
 SG_ FFDD_Twoway2_ThumbWheelType : 821|2@1+ (1,0) [0|3] "" Vector__XXX
 SG_ FFDD_Twoway2_2PumpOption : 820|1@1+ (1,0) [0|1] "" Vector__XXX
 SG_ FFDD_Twoway1_SelectedATTType : 800|1@1+ (1,0) [0|1] "" Vector__XXX
 SG_ FFDD_Twoway1_SelectedATTNumber : 801|3@1+ (1,0) [0|7] "" Vector__XXX
 SG_ FFDD_Twoway1_ThumbWheelType : 805|2@1+ (1,0) [0|3] "" Vector__XXX
 SG_ FFDD_Twoway1_2PumpOption : 804|1@1+ (1,0) [0|1] "" Vector__XXX
 SG_ FFDD_Twoway0_SelectedATTType : 784|1@1+ (1,0) [0|1] "" Vector__XXX
 SG_ FFDD_Twoway0_SelectedATTNumber : 785|3@1+ (1,0) [0|7] "" Vector__XXX
 SG_ FFDD_Twoway0_ThumbWheelType : 789|2@1+ (1,0) [0|3] "" Vector__XXX
 SG_ FFDD_Twoway0_2PumpOption : 788|1@1+ (1,0) [0|1] "" Vector__XXX
 SG_ FFDD_SelectedAttachmentTwoway : 3|3@1+ (1,0) [0|7] "" Vector__XXX
 SG_ FFDD_SelectedAttachmentOneway : 0|3@1+ (1,0) [0|7] "" Vector__XXX
 SG_ FFDD_OneWayUseFlow4 : 768|16@1+ (1,0) [0|65535] "" Vector__XXX
 SG_ FFDD_OneWayUseFlow3 : 752|16@1+ (1,0) [0|65535] "" Vector__XXX
 SG_ FFDD_OneWayUseFlow2 : 736|16@1+ (1,0) [0|65535] "" Vector__XXX
 SG_ FFDD_OneWayUseFlow1 : 720|16@1+ (1,0) [0|65535] "" Vector__XXX
 SG_ FFDD_OneWayUseFlow0 : 704|16@1+ (1,0) [0|65535] "" Vector__XXX
 SG_ FFDD_OneWaySetFlow4 : 688|16@1+ (1,0) [0|65535] "" Vector__XXX
 SG_ FFDD_OneWaySetFlow3 : 672|16@1+ (1,0) [0|65535] "" Vector__XXX
 SG_ FFDD_OneWaySetFlow2 : 656|16@1+ (1,0) [0|65535] "" Vector__XXX
 SG_ FFDD_OneWaySetFlow1 : 640|16@1+ (1,0) [0|65535] "" Vector__XXX
 SG_ FFDD_OneWaySetFlow0 : 624|16@1+ (1,0) [0|65535] "" Vector__XXX
 SG_ FFDD_OneWayRpm4 : 288|16@1+ (1,0) [0|65535] "" Vector__XXX
 SG_ FFDD_OneWayRpm3 : 272|16@1+ (1,0) [0|65535] "" Vector__XXX
 SG_ FFDD_OneWayRpm2 : 256|16@1+ (1,0) [0|65535] "" Vector__XXX
 SG_ FFDD_OneWayRpm1 : 240|16@1+ (1,0) [0|65535] "" Vector__XXX
 SG_ FFDD_OneWayRpm0 : 224|16@1+ (1,0) [0|65535] "" Vector__XXX
 SG_ FFDD_OneWayPress4 : 368|16@1+ (1,0) [0|65535] "" Vector__XXX
 SG_ FFDD_OneWayPress3 : 352|16@1+ (1,0) [0|65535] "" Vector__XXX
 SG_ FFDD_OneWayPress2 : 336|16@1+ (1,0) [0|65535] "" Vector__XXX
 SG_ FFDD_OneWayPress1 : 320|16@1+ (1,0) [0|65535] "" Vector__XXX
 SG_ FFDD_OneWayPress0 : 304|16@1+ (1,0) [0|65535] "" Vector__XXX
 SG_ FFDD_OneWayMinFlowATT4 : 608|16@1+ (1,0) [0|65535] "" Vector__XXX
 SG_ FFDD_OneWayMinFlowATT3 : 592|16@1+ (1,0) [0|65535] "" Vector__XXX
 SG_ FFDD_OneWayMinFlowATT2 : 576|16@1+ (1,0) [0|65535] "" Vector__XXX
 SG_ FFDD_OneWayMinFlowATT1 : 560|16@1+ (1,0) [0|65535] "" Vector__XXX
 SG_ FFDD_OneWayMinFlowATT0 : 544|16@1+ (1,0) [0|65535] "" Vector__XXX
 SG_ FFDD_OneWayMaxFlowPump4 : 448|16@1+ (1,0) [0|65535] "" Vector__XXX
 SG_ FFDD_OneWayMaxFlowPump3 : 432|16@1+ (1,0) [0|65535] "" Vector__XXX
 SG_ FFDD_OneWayMaxFlowPump2 : 416|16@1+ (1,0) [0|65535] "" Vector__XXX
 SG_ FFDD_OneWayMaxFlowPump1 : 400|16@1+ (1,0) [0|65535] "" Vector__XXX
 SG_ FFDD_OneWayMaxFlowPump0 : 384|16@1+ (1,0) [0|65535] "" Vector__XXX
 SG_ FFDD_OneWayMaxFlowATT4 : 528|16@1+ (1,0) [0|65535] "" Vector__XXX
 SG_ FFDD_OneWayMaxFlowATT3 : 512|16@1+ (1,0) [0|65535] "" Vector__XXX
 SG_ FFDD_OneWayMaxFlowATT2 : 496|16@1+ (1,0) [0|65535] "" Vector__XXX
 SG_ FFDD_OneWayMaxFlowATT1 : 480|16@1+ (1,0) [0|65535] "" Vector__XXX
 SG_ FFDD_OneWayMaxFlowATT0 : 464|16@1+ (1,0) [0|65535] "" Vector__XXX
 SG_ FFDD_Oneway4_SelectedATTType : 208|1@1+ (1,0) [0|1] "" Vector__XXX
 SG_ FFDD_Oneway4_SelectedATTNumber : 209|3@1+ (1,0) [0|7] "" Vector__XXX
 SG_ FFDD_Oneway4_BreakerButtonType : 213|2@1+ (1,0) [0|3] "" Vector__XXX
 SG_ FFDD_Oneway4_2PumpOption : 212|1@1+ (1,0) [0|1] "" Vector__XXX
 SG_ FFDD_Oneway3_SelectedATTType : 192|1@1+ (1,0) [0|1] "" Vector__XXX
 SG_ FFDD_Oneway3_SelectedATTNumber : 193|3@1+ (1,0) [0|7] "" Vector__XXX
 SG_ FFDD_Oneway3_BreakerButtonType : 197|2@1+ (1,0) [0|3] "" Vector__XXX
 SG_ FFDD_Oneway3_2PumpOption : 196|1@1+ (1,0) [0|1] "" Vector__XXX
 SG_ FFDD_Oneway2_SelectedATTType : 176|1@1+ (1,0) [0|1] "" Vector__XXX
 SG_ FFDD_Oneway2_SelectedATTNumber : 177|3@1+ (1,0) [0|7] "" Vector__XXX
 SG_ FFDD_Oneway2_BreakerButtonType : 181|2@1+ (1,0) [0|3] "" Vector__XXX
 SG_ FFDD_Oneway2_2PumpOption : 180|1@1+ (1,0) [0|1] "" Vector__XXX
 SG_ FFDD_Oneway1_SelectedATTType : 160|1@1+ (1,0) [0|1] "" Vector__XXX
 SG_ FFDD_Oneway1_SelectedATTNumber : 161|3@1+ (1,0) [0|7] "" Vector__XXX
 SG_ FFDD_Oneway1_BreakerButtonType : 165|2@1+ (1,0) [0|3] "" Vector__XXX
 SG_ FFDD_Oneway1_2PumpOption : 164|1@1+ (1,0) [0|1] "" Vector__XXX
 SG_ FFDD_Oneway0_SelectedATTType : 144|1@1+ (1,0) [0|1] "" Vector__XXX
 SG_ FFDD_Oneway0_SelectedATTNumber : 145|3@1+ (1,0) [0|7] "" Vector__XXX
 SG_ FFDD_Oneway0_BreakerButtonType : 149|2@1+ (1,0) [0|3] "" Vector__XXX
 SG_ FFDD_Oneway0_2PumpOption : 148|1@1+ (1,0) [0|1] "" Vector__XXX

BO_ 2566902305 VCU_FOUHI: 150 Vector__XXX
 SG_ FFD2_PumpDriveOilHour : 768|32@1+ (1,0) [0|4294967295] "" Vector__XXX
 SG_ FFD2_PumpDriveAirCartridgeHour : 800|32@1+ (1,0) [0|4294967295] "" Vector__XXX
 SG_ FFD2_HSTFilter : 736|32@1+ (1,0) [0|4294967295] "" Vector__XXX
 SG_ FFD2_AxleOilFilter : 704|32@1+ (1,0) [0|4294967295] "" Vector__XXX
 SG_ FFD2_ATSsparkPlug : 672|32@1+ (1,0) [0|4294967295] "" Vector__XXX
 SG_ FFD2_EGCrankcaseBreather : 640|32@1+ (1,0) [0|4294967295] "" Vector__XXX
 SG_ FFD2_AirConFilter_Inner : 608|32@1+ (1,0) [0|4294967295] "" Vector__XXX
 SG_ FFD2_AirConFilter_Outer : 576|32@1+ (1,0) [0|4294967295] "" Vector__XXX
 SG_ FFD2_EGOilCentriCleanerFilter : 544|32@1+ (1,0) [0|4294967295] "" Vector__XXX
 SG_ FFD2_DEFBreatherFilter : 512|32@1+ (1,0) [0|4294967295] "" Vector__XXX
 SG_ FFD2_DEFfilter : 480|32@1+ (1,0) [0|4294967295] "" Vector__XXX
 SG_ FFD2_OilBathedPrecleaner : 448|32@1+ (1,0) [0|4294967295] "" Vector__XXX
 SG_ FFD2_DPFFilter : 256|32@1+ (1,0) [0|4294967295] "" Vector__XXX
 SG_ FFD2_TransmissionOilFilter : 352|32@1+ (1,0) [0|4294967295] "" Vector__XXX
 SG_ FFD2_TransmissionOil : 320|32@1+ (1,0) [0|4294967295] "" Vector__XXX
 SG_ FFD2_ReturnFilter : 96|32@1+ (1,0) [0|4294967295] "" Vector__XXX
 SG_ FFD2_PilotFilter : 128|32@1+ (1,0) [0|4294967295] "" Vector__XXX
 SG_ FFD2_HydOil : 192|32@1+ (1,0) [0|4294967295] "" Vector__XXX
 SG_ FFD2_FuelFilter : 0|32@1+ (1,0) [0|4294967295] "" Vector__XXX
 SG_ FFD2_EngineOilFilter : 64|32@1+ (1,0) [0|4294967295] "" Vector__XXX
 SG_ FFD2_EngineOil : 160|32@1+ (1,0) [0|4294967295] "" Vector__XXX
 SG_ FFD2_DEF : 416|32@1+ (1,0) [0|4294967295] "" Vector__XXX
 SG_ FFD2_CoolantWater : 224|32@1+ (1,0) [0|4294967295] "" Vector__XXX
 SG_ FFD2_BreatherOilSeparatorFilter : 288|32@1+ (1,0) [0|4294967295] "" Vector__XXX
 SG_ FFD2_AxleOil : 384|32@1+ (1,0) [0|4294967295] "" Vector__XXX
 SG_ FFD2_AirCleaner : 32|32@1+ (1,0) [0|4294967295] "" Vector__XXX

BO_ 2566901793 VCU_HSDI: 8 Vector__XXX
 SG_ FFD0_RandomValue : 0|16@1+ (1,0) [0|65535] "" Vector__XXX

BO_ 2566865953 VCU_SIG2: 8 Vector__XXX
 SG_ FF44_Regen_Stop : 55|1@1+ (1,0) [0|1] "" Vector__XXX
 SG_ FF44_Regen_Success : 54|1@1+ (1,0) [0|1] "" Vector__XXX
 SG_ FF44_Warning_HST_TracLevel : 63|1@1+ (1,0) [0|1] "" Vector__XXX
 SG_ FF44_FloatingHolding : 62|1@1+ (1,0) [0|1] "" Vector__XXX
 SG_ FF44_ADB : 60|2@1+ (1,0) [0|3] "" Vector__XXX
 SG_ FF44_Cruise : 59|1@1+ (1,0) [0|1] "" Vector__XXX
 SG_ FF44_PopUp_4WheelDriveMode : 57|2@1+ (1,0) [0|3] "" Vector__XXX
 SG_ FF44_Rear_Defrost_Symbol : 33|1@1+ (1,0) [0|1] "" Vector__XXX
 SG_ FF44_Kickdown_Symbol : 30|1@1+ (1,0) [0|1] "" Vector__XXX
 SG_ FF44_Emergency_Mode : 32|1@1+ (1,0) [0|1] "" Vector__XXX
 SG_ FF44_Weighing_Weight_Count : 53|1@1+ (1,0) [0|1] "" Vector__XXX
 SG_ FF44_Weighing_Warm_UP_Request : 45|1@1+ (1,0) [0|1] "" Vector__XXX
 SG_ FF44_Weighing_underspeedwarrning : 34|1@1+ (1,0) [0|1] "" Vector__XXX
 SG_ FF44_Weighing_Too_heavy_Warning : 38|1@1+ (1,0) [0|1] "" Vector__XXX
 SG_ FF44_Weighing_Start_Position : 36|1@1+ (1,0) [0|1] "" Vector__XXX
 SG_ FF44_Weighing_SpeedbounceWarning : 35|1@1+ (1,0) [0|1] "" Vector__XXX
 SG_ FF44_Weighing_Signal_Zero_Cal : 46|1@1+ (1,0) [0|1] "" Vector__XXX
 SG_ FF44_Weighing_Poor_Lift_Warning : 37|1@1+ (1,0) [0|1] "" Vector__XXX
 SG_ FF44_Weighing_MapReady_Signal : 44|1@1+ (1,0) [0|1] "" Vector__XXX
 SG_ FF44_Weighing_MapCreation_Pro : 48|5@1+ (1,0) [0|31] "" Vector__XXX
 SG_ FF44_Weighing_Angle_Sensor : 47|1@1+ (1,0) [0|1] "" Vector__XXX
 SG_ FF44_Warning_DESMachineShutDown : 56|1@1+ (1,0) [0|1] "" Vector__XXX
 SG_ FF44_ColdStartStatus : 40|4@1+ (1,0) [0|15] "min" Vector__XXX
 SG_ FF44_OperatingPowerMode : 26|4@1+ (1,0) [0|15] "min" Vector__XXX
 SG_ FF44_TractionMode : 24|2@1+ (1,0) [0|3] "min" Vector__XXX
 SG_ FF44_CCOStatus : 23|1@1+ (1,0) [0|1] "min" Vector__XXX
 SG_ FF44_TorqueConvertoerLockUp : 22|1@1+ (1,0) [0|1] "min" Vector__XXX
 SG_ FF44_TravelModeSymbol : 20|2@1+ (1,0) [0|3] "min" Vector__XXX
 SG_ FF44_CreepStatus : 19|1@1+ (1,0) [0|1] "min" Vector__XXX
 SG_ FF44_ThrottleLockStatus : 18|1@1+ (1,0) [0|1] "min" Vector__XXX
 SG_ FF44_DHLStatus : 17|1@1+ (1,0) [0|1] "min" Vector__XXX
 SG_ FF44_LISSwtStatus : 16|1@1+ (1,0) [0|1] "min" Vector__XXX
 SG_ FF44_WIFDeratingTime : 0|8@1+ (1,0) [0|255] "min" Vector__XXX
 SG_ FF44_CoolantDeratingTime : 8|8@1+ (1,0) [0|255] "min" Vector__XXX

BO_ 2566865441 VCU_WSG3: 6 Vector__XXX
 SG_ FF42_HydraulicOilWarmUp : 44|4@1+ (1,0) [0|15] "" Vector__XXX
 SG_ FF42_GroundSawReady : 40|4@1+ (1,0) [0|15] "" Vector__XXX
 SG_ FF42_QuickCouplerLock : 32|4@1+ (1,0) [0|15] "" Vector__XXX
 SG_ FF42_BrakePedalSensor : 28|4@1+ (1,0) [0|15] "" Vector__XXX
 SG_ FF42_ATSRegenerationRequest : 24|4@1+ (1,0) [0|15] "" Vector__XXX
 SG_ FF42_UreaQualityWarningLamp : 4|4@1+ (1,0) [0|15] "" Vector__XXX
 SG_ FF42_UreaLevelIndicator : 0|4@1+ (1,0) [0|15] "" Vector__XXX
 SG_ FF42_TMSModule : 20|4@1+ (1,0) [0|15] "" Vector__XXX
 SG_ FF42_RemovableCounterweight : 12|4@1+ (1,0) [0|15] "" Vector__XXX
 SG_ FF42_QuickCouplerUnlock : 16|4@1+ (1,0) [0|15] "" Vector__XXX
 SG_ FF42_FuelFilter : 8|4@1+ (1,0) [0|15] "" Vector__XXX

BO_ 2566865185 VCU_WSG2: 7 Vector__XXX
 SG_ FF41_FuelEmptyAdditionalFuelTank : 48|1@1+ (1,0) [0|1] "" Vector__XXX
 SG_ FF41_EpowerStop : 46|2@1+ (1,0) [0|3] "" Vector__XXX
 SG_ FF41_EGCoolDown_EpowerCheck : 44|2@1+ (1,0) [0|3] "" Vector__XXX
 SG_ FF41_CoolantLevel_Reserved : 42|2@1+ (1,0) [0|3] "" Vector__XXX
 SG_ FF41_LowDEFPressure : 40|2@1+ (1,0) [0|3] "" Vector__XXX
 SG_ FF41_WIF_PrefilterWater : 32|2@1+ (1,0) [0|3] "" Vector__XXX
 SG_ FF41_WIF_PrefilterFault : 34|2@1+ (1,0) [0|3] "" Vector__XXX
 SG_ FF41_WIF_MainFilterWater : 36|2@1+ (1,0) [0|3] "" Vector__XXX
 SG_ FF41_WIF_MainFilterFault : 38|2@1+ (1,0) [0|3] "" Vector__XXX
 SG_ FF41_DPFRegenStatusLampCmd : 18|2@1+ (1,0) [0|3] "" Vector__XXX
 SG_ FF41_ExhSysHighTempAmb_Isuzu : 24|2@1+ (1,0) [0|3] "" Vector__XXX
 SG_ FF41_DPFRegenInhibitedStatus : 20|2@1+ (1,0) [0|3] "" Vector__XXX
 SG_ FF41_FuelEmpty : 30|2@1+ (1,0) [0|3] "" Vector__XXX
 SG_ FF41_ExhSysHighTemAmb_Bosch : 26|2@1+ (1,0) [0|3] "" Vector__XXX
 SG_ FF41_EngineWarning : 8|2@1+ (1,0) [0|3] "" Vector__XXX
 SG_ FF41_EngineStop : 10|2@1+ (1,0) [0|3] "" Vector__XXX
 SG_ FF41_EngineOilPressure : 0|2@1+ (1,0) [0|3] "" Vector__XXX
 SG_ FF41_EngineCheckService : 16|2@1+ (1,0) [0|3] "" Vector__XXX
 SG_ FF41_EngineCheck2Time : 14|2@1+ (1,0) [0|3] "" Vector__XXX
 SG_ FF41_EngineCheck1Time : 12|2@1+ (1,0) [0|3] "" Vector__XXX
 SG_ FF41_CoolantTempOverheat : 2|2@1+ (1,0) [0|3] "" Vector__XXX
 SG_ FF41_CoolantLevelWarning : 4|2@1+ (1,0) [0|3] "" Vector__XXX
 SG_ FF41_AutoSCRCondition_Perkins : 28|2@1+ (1,0) [0|3] "" Vector__XXX
 SG_ FF41_ExhSysHighTempGreen : 22|2@1+ (1,0) [0|3] "" Vector__XXX
 SG_ FF41_AirCleaner : 6|2@1+ (1,0) [0|3] "" Vector__XXX

BO_ 2566865697 VCU_SIG1: 8 Vector__XXX
 SG_ FF43_BoomFloat_Bi_Direc : 55|1@1+ (1,0) [0|1] "" Vector__XXX
 SG_ FF43_BuzzerControlCommand : 62|2@1+ (1,0) [0|3] "" Vector__XXX
 SG_ FF43_3rdAndElecSteerActivation : 54|1@1+ (1,0) [0|1] "" Vector__XXX
 SG_ FF43_CurrentGearStatus : 59|3@1+ (1,0) [0|7] "" Vector__XXX
 SG_ FF43_SelectedGearStatus : 56|3@1+ (1,0) [0|7] "" Vector__XXX
 SG_ FF43_OptnFNRActvn : 53|1@1+ (1,0) [0|1] "" Vector__XXX
 SG_ FF43_MirrorHeater : 7|1@1+ (1,0) [0|1] "" Vector__XXX
 SG_ FF43_ElecSteeringSelect : 52|1@1+ (1,0) [0|1] "" Vector__XXX
 SG_ FF43_WorkLamp : 0|1@1+ (1,0) [0|1] "" Vector__XXX
 SG_ FF43_WorkModeSymbol : 10|2@1+ (1,0) [0|3] "" Vector__XXX
 SG_ FF43_WarningCount_Machine : 44|2@1+ (1,0) [0|3] "" Vector__XXX
 SG_ FF43_WarningCount_AVM : 46|2@1+ (1,0) [0|3] "" Vector__XXX
 SG_ FF43_TwoWayOptionSetStatus : 12|2@1+ (1,0) [0|3] "" Vector__XXX
 SG_ FF43_TravelModeSymbol_Wheel : 16|2@1+ (1,0) [0|3] "" Vector__XXX
 SG_ FF43_TravelModeSymbol_Crawler : 8|2@1+ (1,0) [0|3] "" Vector__XXX
 SG_ FF43_Travel : 20|1@1+ (1,0) [0|1] "" Vector__XXX
 SG_ FF43_SwingPriorityState : 4|1@1+ (1,0) [0|1] "" Vector__XXX
 SG_ FF43_ReverseFanState : 5|1@1+ (1,0) [0|1] "" Vector__XXX
 SG_ FF43_RAMLock : 22|1@1+ (1,0) [0|1] "" Vector__XXX
 SG_ FF43_PreheatLamp : 48|2@1+ (1,0) [0|3] "" Vector__XXX
 SG_ FF43_PowerMax : 1|1@1+ (1,0) [0|1] "" Vector__XXX
 SG_ FF43_Popup_PreventOverHeat : 30|2@1+ (1,0) [0|3] "" Vector__XXX
 SG_ FF43_Popup_ThumbWheelLeverError : 37|1@1+ (1,0) [0|1] "" Vector__XXX
 SG_ FF43_Popup_RPMSetLimit : 34|1@1+ (1,0) [0|1] "" Vector__XXX
 SG_ FF43_Popup_RegenerationParkins : 35|1@1+ (1,0) [0|1] "" Vector__XXX
 SG_ FF43_Popup_EngineLock_Pilot : 33|1@1+ (1,0) [0|1] "" Vector__XXX
 SG_ FF43_Popup_EngineLock_FNRorP : 32|1@1+ (1,0) [0|1] "" Vector__XXX
 SG_ FF43_AutoIdleActiveStatus : 36|1@1+ (1,0) [0|1] "" Vector__XXX
 SG_ FF43_ParkingBrake : 21|1@1+ (1,0) [0|1] "" Vector__XXX
 SG_ FF43_ISOorBHL : 14|2@1+ (1,0) [0|3] "" Vector__XXX
 SG_ FF43_HighLand : 28|2@1+ (1,0) [0|3] "" Vector__XXX
 SG_ FF43_HighBeam : 23|1@1+ (1,0) [0|1] "" Vector__XXX
 SG_ FF43_FuelHeater : 26|1@1+ (1,0) [0|1] "" Vector__XXX
 SG_ FF43_FNR : 18|2@1+ (1,0) [0|3] "" Vector__XXX
 SG_ FF43_ExBuzzerCommand : 42|1@1+ (1,0) [0|1] "" Vector__XXX
 SG_ FF43_CEOperatingReadyStatus : 50|2@1+ (1,0) [0|3] "" Vector__XXX
 SG_ FF43_CentralWarningLEDCommand : 43|1@1+ (1,0) [0|1] "" Vector__XXX
 SG_ FF43_BreakerStatus : 38|2@1+ (1,0) [0|3] "" Vector__XXX
 SG_ FF43_BoomSwingActiveStatus : 3|1@1+ (1,0) [0|1] "" Vector__XXX
 SG_ FF43_BoomFloat : 2|1@1+ (1,0) [0|1] "" Vector__XXX
 SG_ FF43_AuxModeState : 6|1@1+ (1,0) [0|1] "" Vector__XXX
 SG_ FF43_AutoWarmUp_Green : 25|1@1+ (1,0) [0|1] "" Vector__XXX
 SG_ FF43_AutoWarmUp_Amber : 24|1@1+ (1,0) [0|1] "" Vector__XXX
 SG_ FF43_AutoShutDownSymbol : 27|1@1+ (1,0) [0|1] "" Vector__XXX
 SG_ FF43_AutoShutDownEnableStatus : 41|1@1+ (1,0) [0|1] "" Vector__XXX
 SG_ FF43_AutoShutDownState : 40|1@1+ (1,0) [0|1] "" Vector__XXX

BO_ 2566864929 VCU_WSG1: 8 Vector__XXX
 SG_ FF40_InverterOvertemp : 62|2@1+ (1,0) [0|3] "" Vector__XXX
 SG_ FF40_MotorOvertemp : 60|2@1+ (1,0) [0|3] "" Vector__XXX
 SG_ FF40_BatteryOvertemp : 58|2@1+ (1,0) [0|3] "" Vector__XXX
 SG_ FF40_BMSwarning : 56|2@1+ (1,0) [0|3] "" Vector__XXX
 SG_ FF40_BatteryHeater : 54|2@1+ (1,0) [0|3] "" Vector__XXX
 SG_ FF40_TravelPedalFailureWarning : 52|2@1+ (1,0) [0|3] "" Vector__XXX
 SG_ FF40_RearWheelAlignmentWarning : 50|2@1+ (1,0) [0|3] "" Vector__XXX
 SG_ FF40_ParkingBrakePressureWarning : 48|2@1- (1,0) [-2|1] "" Vector__XXX
 SG_ FF40_EngineOverrun : 36|2@1+ (1,0) [0|3] "" Vector__XXX
 SG_ FF40_TransmissionOilFilterWarn : 46|2@1+ (1,0) [0|3] "" Vector__XXX
 SG_ FF40_FanMotorPressureLow : 44|2@1+ (1,0) [0|3] "" Vector__XXX
 SG_ FF40_OverSpeedWarning : 42|2@1+ (1,0) [0|3] "" Vector__XXX
 SG_ FF40_BrakePedalNotCalibration : 40|2@1+ (1,0) [0|3] "" Vector__XXX
 SG_ FF40_ElecSteeringWarning : 38|2@1+ (1,0) [0|3] "" Vector__XXX
 SG_ FF40_EmergencySteering : 34|2@1+ (1,0) [0|3] "" Vector__XXX
 SG_ FF40_SeatBelt : 32|2@1+ (1,0) [0|3] "" Vector__XXX
 SG_ FF40_TransmissionOilOverheat : 30|2@1+ (1,0) [0|3] "" Vector__XXX
 SG_ FF40_TransmissionWarning : 28|2@1+ (1,0) [0|3] "" Vector__XXX
 SG_ FF40_VBOError_JoystickSensor : 24|2@1+ (1,0) [0|3] "" Vector__XXX
 SG_ FF40_VBOError_EPPRVVOutput : 26|2@1+ (1,0) [0|3] "" Vector__XXX
 SG_ FF40_VBOError_AngleSensor : 22|2@1+ (1,0) [0|3] "" Vector__XXX
 SG_ FF40_UltraSonicSensorWarning : 18|2@1+ (1,0) [0|3] "" Vector__XXX
 SG_ FF40_Steering : 14|2@1+ (1,0) [0|3] "" Vector__XXX
 SG_ FF40_ReturnFilter : 4|2@1+ (1,0) [0|3] "" Vector__XXX
 SG_ FF40_PilotFilter : 6|2@1+ (1,0) [0|3] "" Vector__XXX
 SG_ FF40_OWDWarning : 8|2@1+ (1,0) [0|3] "" Vector__XXX
 SG_ FF40_iCEPTSensorWarning : 16|2@1+ (1,0) [0|3] "" Vector__XXX
 SG_ FF40_HydOilOverheat : 2|2@1+ (1,0) [0|3] "" Vector__XXX
 SG_ FF40_BrakeOilPressLow : 12|2@1+ (1,0) [0|3] "" Vector__XXX
 SG_ FF40_BatteryEqualizer : 20|2@1+ (1,0) [0|3] "" Vector__XXX
 SG_ FF40_BatteryCharge : 0|2@1+ (1,0) [0|3] "" Vector__XXX
 SG_ FF40_AGSWarning : 10|2@1+ (1,0) [0|3] "" Vector__XXX

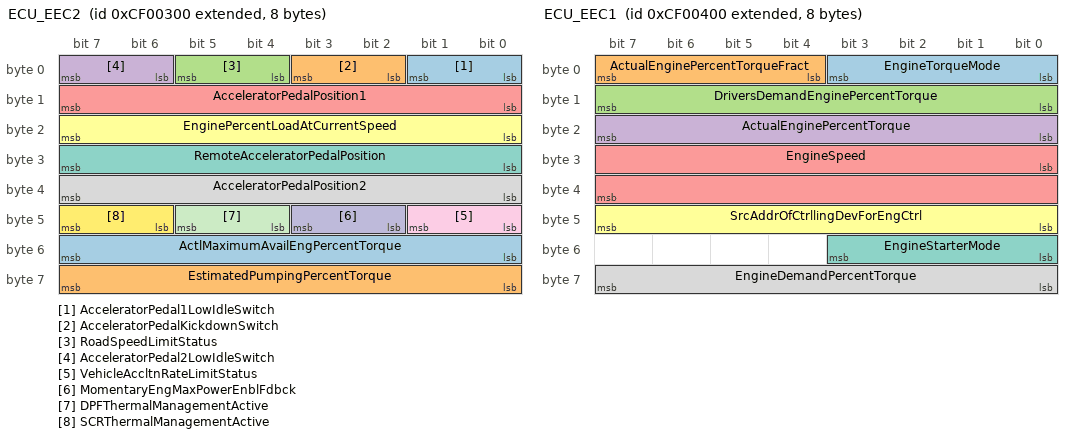
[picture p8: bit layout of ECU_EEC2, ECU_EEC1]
BO_ 2364539648 ECU_EEC2: 8 Vector__XXX
 SG_ AcceleratorPedal1LowIdleSwitch : 0|2@1+ (1,0) [0|3] "" Vector__XXX
 SG_ AcceleratorPedalKickdownSwitch : 2|2@1+ (1,0) [0|3] "" Vector__XXX
 SG_ RoadSpeedLimitStatus : 4|2@1+ (1,0) [0|3] "" Vector__XXX
 SG_ AcceleratorPedal2LowIdleSwitch : 6|2@1+ (1,0) [0|3] "" Vector__XXX
 SG_ AcceleratorPedalPosition1 : 8|8@1+ (0.4,0) [0|100] "%" Vector__XXX
 SG_ EnginePercentLoadAtCurrentSpeed : 16|8@1+ (1,0) [0|250] "%" Vector__XXX
 SG_ RemoteAcceleratorPedalPosition : 24|8@1+ (0.4,0) [0|100] "%" Vector__XXX
 SG_ AcceleratorPedalPosition2 : 32|8@1+ (0.4,0) [0|100] "%" Vector__XXX
 SG_ VehicleAccltnRateLimitStatus : 40|2@1+ (1,0) [0|3] "" Vector__XXX
 SG_ MomentaryEngMaxPowerEnblFdbck : 42|2@1+ (1,0) [0|3] "" Vector__XXX
 SG_ DPFThermalManagementActive : 44|2@1+ (1,0) [0|3] "" Vector__XXX
 SG_ SCRThermalManagementActive : 46|2@1+ (1,0) [0|3] "" Vector__XXX
 SG_ ActlMaximumAvailEngPercentTorque : 48|8@1+ (0.4,0) [0|100] "%" Vector__XXX
 SG_ EstimatedPumpingPercentTorque : 56|8@1+ (1,-125) [-125|125] "%" Vector__XXX

BO_ 2364539904 ECU_EEC1: 8 Vector__XXX
 SG_ EngineTorqueMode : 0|4@1+ (1,0) [0|15] "" Vector__XXX
 SG_ ActualEnginePercentTorqueFract : 4|4@1+ (0.125,0) [0|0.875] "%" Vector__XXX
 SG_ DriversDemandEnginePercentTorque : 8|8@1+ (1,-125) [-125|125] "%" Vector__XXX
 SG_ ActualEnginePercentTorque : 16|8@1+ (1,-125) [-125|125] "%" Vector__XXX
 SG_ EngineSpeed : 24|16@1+ (0.125,0) [0|8031.875] "rpm" Vector__XXX
 SG_ SrcAddrOfCtrllingDevForEngCtrl : 40|8@1+ (1,0) [0|255] "" Vector__XXX
 SG_ EngineStarterMode : 48|4@1+ (1,0) [0|15] "" Vector__XXX
 SG_ EngineDemandPercentTorque : 56|8@1+ (1,-125) [-125|125] "%" Vector__XXX

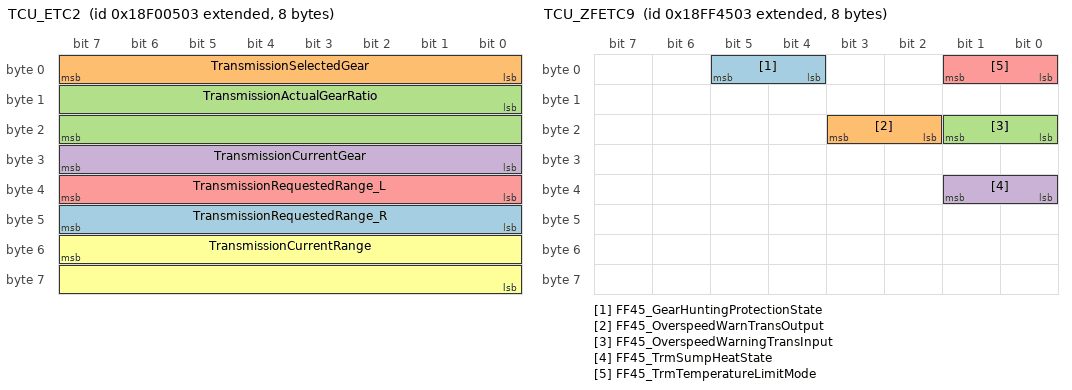
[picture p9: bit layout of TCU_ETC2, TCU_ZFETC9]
BO_ 2565866755 TCU_ETC2: 8 Vector__XXX
 SG_ TransmissionRequestedRange_R : 40|8@1+ (1,0) [0|255] "Per" Vector__XXX
 SG_ TransmissionSelectedGear : 0|8@1+ (1,-125) [-125|125] "" Vector__XXX
 SG_ TransmissionActualGearRatio : 8|16@1+ (0.001,0) [0|64.255] "" Vector__XXX
 SG_ TransmissionCurrentGear : 24|8@1+ (1,-125) [-125|125] "" Vector__XXX
 SG_ TransmissionRequestedRange_L : 39|8@0+ (1,0) [0|255] "Per" Vector__XXX
 SG_ TransmissionCurrentRange : 55|16@0+ (1,0) [0|65535] "ASCII" Vector__XXX

BO_ 2566801923 TCU_ETC7: 8 Vector__XXX
 SG_ TrnsmCurrentRngDisplayBlankStat : 0|2@1+ (1,0) [0|3] "" Vector__XXX
 SG_ TransmissionServiceIndicator : 2|2@1+ (1,0) [0|3] "" Vector__XXX
 SG_ TrnsmRqedRngDisplayBlankStat : 4|2@1+ (1,0) [0|3] "" Vector__XXX
 SG_ TrnsmRqedRngDisplayFlashStat : 6|2@1+ (1,0) [0|3] "" Vector__XXX
 SG_ TransmissionReadyForBrakeRelease : 8|2@1+ (1,0) [0|3] "" Vector__XXX
 SG_ ActiveShiftConsoleIndicator : 10|2@1+ (1,0) [0|3] "" Vector__XXX
 SG_ TransmissionEngineCrankEnable : 12|2@1+ (1,0) [0|3] "" Vector__XXX
 SG_ TransmissionShiftInhibitIndictr : 14|2@1+ (1,0) [0|3] "" Vector__XXX
 SG_ TransmissionMode4Indicator : 16|2@1+ (1,0) [0|3] "" Vector__XXX
 SG_ TransmissionMode3Indicator : 18|2@1+ (1,0) [0|3] "" Vector__XXX
 SG_ TransmissionMode2Indicator : 20|2@1+ (1,0) [0|3] "" Vector__XXX
 SG_ TransmissionMode1Indicator : 22|2@1+ (1,0) [0|3] "" Vector__XXX
 SG_ TransmissionRequestedGearFdbck : 24|8@1+ (1,-125) [-125|125] "" Vector__XXX
 SG_ TransmissionMode5Indicator : 32|2@1+ (1,0) [0|3] "" Vector__XXX
 SG_ TransmissionMode6Indicator : 34|2@1+ (1,0) [0|3] "" Vector__XXX
 SG_ TransmissionMode7Indicator : 36|2@1+ (1,0) [0|3] "" Vector__XXX
 SG_ TransmissionMode8Indicator : 38|2@1+ (1,0) [0|3] "" Vector__XXX
 SG_ TrnsmReverseGearShftInhbtStat : 40|2@1+ (1,0) [0|3] "" Vector__XXX
 SG_ TransmissionWarningIndicator : 42|2@1+ (1,0) [0|3] "" Vector__XXX
 SG_ TransmissionMode9Indicator : 44|2@1+ (1,0) [0|3] "" Vector__XXX
 SG_ TransmissionMode10Indicator : 46|2@1+ (1,0) [0|3] "" Vector__XXX
 SG_ TrnsmAirSupplyPressIndictr : 48|3@1+ (1,0) [0|7] "" Vector__XXX

BO_ 2566902817 VCU_XASI: 134 Vector__XXX
 SG_ FFD4_CabinElevLeverVolt : 672|16@1+ (1,0) [0|65535] "mV" Vector__XXX
 SG_ FFD4_GroundSAWDownPressSensor : 624|16@1+ (0.00390625,0) [0|50] "bar" Vector__XXX
 SG_ FFD4_GoundSAWUpPressSensor : 608|16@1+ (0.00390625,0) [0|50] "bar" Vector__XXX
 SG_ FFD4_FuelLevelAdditionalFuelTank : 560|16@1+ (1,0) [0|65535] "" Vector__XXX
 SG_ FFD4_ACPSensorPressure : 544|16@1+ (1,0) [0|65535] "" Vector__XXX
 SG_ FFD4_RCWStopValvePress : 64|16@1+ (0.0625,0) [0|500] "bar" Vector__XXX
 SG_ FFD4_FuelPress : 80|16@1+ (0.0039063,0) [0|50] "bar" Vector__XXX
 SG_ FFD4_LSpress : 496|16@1+ (0.0625,0) [0|500] "bar" Vector__XXX
 SG_ FFD4_RAMLockpressure : 1056|16@1+ (1,0) [0|500] "bar" Vector__XXX
 SG_ FFD4_TrailerDownPilotPressure : 1040|16@1+ (1,0) [0|50] "bar" Vector__XXX
 SG_ FFD4_ArmRodPressure : 1008|16@1+ (1,0) [0|500] "bar" Vector__XXX
 SG_ FFD4_ArmHeadPressure : 992|16@1+ (1,0) [0|500] "bar" Vector__XXX
 SG_ FFD4_BoomRodPressure : 976|16@1+ (1,0) [0|500] "bar" Vector__XXX
 SG_ FFD4_BoomHeadPressure : 960|16@1+ (1,0) [0|500] "bar" Vector__XXX
 SG_ FFD4_BucketHeadPressure : 1024|16@1+ (1,0) [0|500] "bar" Vector__XXX
 SG_ FFD4_3rd_Pump_Angle : 120|16@1+ (1,0) [0|65535] "mV" Vector__XXX
 SG_ FFD4_3rd_Pump_Press : 48|16@1+ (0.0625,0) [0|500] "bar" Vector__XXX
 SG_ FFD4_P3_Negacon_Press : 480|16@1+ (0.0625,0) [0|500] "bar" Vector__XXX
 SG_ FFD4_Rear_Pump_Angle : 112|16@1+ (1,0) [0|65535] "mV" Vector__XXX
 SG_ FFD4_Front_Pump_Angle : 96|16@1+ (1,0) [0|65535] "mV" Vector__XXX
 SG_ FFD4_TPS_Voltage : 912|16@1+ (1,0) [0|65535] "mV" Vector__XXX
 SG_ FFD4_Arm_Lock_Press : 400|16@1+ (0.00390625,0) [0|50] "bar" Vector__XXX
 SG_ FFD4_Bucket_Crowd_Conf_Press : 384|16@1+ (0.00390625,0) [0|50] "bar" Vector__XXX
 SG_ FFD4_Arm_Crowd_Conf_Press : 368|16@1+ (0.00390625,0) [0|50] "bar" Vector__XXX
 SG_ FFD4_Boom_Up_Conf_Press : 352|16@1+ (0.00390625,0) [0|50] "bar" Vector__XXX
 SG_ FFD4_Rear_Negacon_Press : 464|16@1+ (0.0625,0) [0|500] "bar" Vector__XXX
 SG_ FFD4_Front_Negacon_Press : 448|16@1+ (0.0625,0) [0|500] "bar" Vector__XXX
 SG_ FFD4_Pitch_Angle : 896|16@1+ (0.0625,0) [0|90] "deg" Vector__XXX
 SG_ FFD4_Roll_Angle : 880|16@1+ (0.0625,0) [0|90] "deg" Vector__XXX
 SG_ FFD4_Coolant_Temp_Mech : 640|16@1+ (1,-40) [-40|210] "deg" Vector__XXX
 SG_ FFD4_TMS_Voltage : 864|16@1+ (1,0) [0|65535] "mV" Vector__XXX
 SG_ FFD4_Vehicle_Speed : 848|16@1+ (1,0) [0|65535] "km/h" Vector__XXX
 SG_ FFD4_Option3_Pressure : 336|16@1+ (0.00390625,0) [0|50] "bar" Vector__XXX
 SG_ FFD4_Option2_Pressure : 320|16@1+ (0.00390625,0) [0|50] "bar" Vector__XXX
 SG_ FFD4_Option1_Pressure : 304|16@1+ (0.00390625,0) [0|50] "bar" Vector__XXX
 SG_ FFD4_Swing_Pressure : 288|16@1+ (0.00390625,0) [0|50] "bar" Vector__XXX
 SG_ FFD4_Travel_Press_LH : 272|16@1+ (0.00390625,0) [0|50] "bar" Vector__XXX
 SG_ FFD4_Travel_Press_RH : 256|16@1+ (0.00390625,0) [0|50] "bar" Vector__XXX
 SG_ FFD4_Bucket_Dump_Press : 240|16@1+ (0.00390625,0) [0|50] "bar" Vector__XXX
 SG_ FFD4_Bucket_Crowd_Press : 224|16@1+ (0.00390625,0) [0|50] "bar" Vector__XXX
 SG_ FFD4_Arm_Out_Pressure : 208|16@1+ (0.00390625,0) [0|50] "bar" Vector__XXX
 SG_ FFD4_Arm_In_Press : 192|16@1+ (0.00390625,0) [0|50] "bar" Vector__XXX
 SG_ FFD4_Boom_Down_Press : 176|16@1+ (0.00390625,0) [0|50] "bar" Vector__XXX
 SG_ FFD4_Boom_Up_Press : 160|16@1+ (0.00390625,0) [0|50] "bar" Vector__XXX
 SG_ FFD4_Hydraulic_Oil_Temp : 656|16@1+ (1,-40) [-40|210] "deg" Vector__XXX
 SG_ FFD4_Fuel_Level : 576|16@1+ (1,0) [0|65535] "%" Vector__XXX
 SG_ FFD4_Flow_Ctrl_Lever_RH_Volt : 800|16@1+ (1,0) [0|65535] "mV" Vector__XXX
 SG_ FFD4_Flow_Ctrl_Lever_LH_Volt : 784|16@1+ (1,0) [0|65535] "mV" Vector__XXX
 SG_ FFD4_WIF_Sensor_Volt : 592|16@1+ (1,0) [0|65535] "mV" Vector__XXX
 SG_ FFD4_Engine_Dial_Volt : 512|16@1+ (1,0) [0|65535] "mV" Vector__XXX
 SG_ FFD4_Accel_Pedal_Volt : 528|16@1+ (1,0) [0|65535] "mV" Vector__XXX
 SG_ FFD4_Battery_Voltage : 736|16@1+ (0.1,0) [0|6553.5] "V" Vector__XXX
 SG_ FFD4_Alternator_Voltage : 720|16@1+ (0.1,0) [0|6553.5] "V" Vector__XXX
 SG_ FFD4_Pt_Pressure : 432|16@1+ (0.0625,0) [0|50] "bar" Vector__XXX
 SG_ FFD4_Pa_Pressure : 416|16@1+ (0.0625,0) [0|50] "bar" Vector__XXX
 SG_ FFD4_Boom_Cylinder_Press : 32|16@1+ (0.0625,0) [0|500] "bar" Vector__XXX
 SG_ FFD4_Rear_Pump_Press : 16|16@1+ (0.0625,0) [0|500] "bar" Vector__XXX
 SG_ FFD4_Front_Pump_Press : 0|16@1+ (0.0625,0) [0|500] "bar" Vector__XXX

BO_ 2566904609 VCU_LDAI: 14 Vector__XXX
 SG_ FFDB_AuxPressureControlSV : 22|2@1+ (1,0) [0|3] "" Vector__XXX
 SG_ FFDB_EscortWorkingLamp : 8|2@1+ (1,0) [0|3] "" Vector__XXX
 SG_ FFDB_AuxShutoffSV : 98|2@1+ (1,0) [0|3] "" Vector__XXX
 SG_ FFDB_Aux8_Relay : 110|2@1+ (1,0) [0|3] "" Vector__XXX
 SG_ FFDB_Aux7_Relay : 108|2@1+ (1,0) [0|3] "" Vector__XXX
 SG_ FFDB_Aux6_Relay : 106|2@1+ (1,0) [0|3] "" Vector__XXX
 SG_ FFDB_Aux5_Relay : 104|2@1+ (1,0) [0|3] "" Vector__XXX
 SG_ FFDB_Aux4_Relay : 102|2@1+ (1,0) [0|3] "" Vector__XXX
 SG_ FFDB_Aux3_Relay : 100|2@1+ (1,0) [0|3] "" Vector__XXX
 SG_ FFDB_PilotcutoffSV : 96|2@1+ (1,0) [0|3] "" Vector__XXX
 SG_ FFDB_FrontWiper_Relay : 94|2@1+ (1,0) [0|3] "" Vector__XXX
 SG_ FFDB_HSTCutoffRHSV : 30|2@1+ (1,0) [0|3] "" Vector__XXX
 SG_ FFDB_HSTCutoffLHSV : 28|2@1+ (1,0) [0|3] "" Vector__XXX
 SG_ FFDB_HydraulicCutoffSV : 18|2@1+ (1,0) [0|3] "" Vector__XXX
 SG_ FFDB_StarterRelay : 16|2@1+ (1,0) [0|3] "" Vector__XXX
 SG_ FFDB_SideWasherRelay : 92|2@1+ (1,0) [0|3] "" Vector__XXX
 SG_ FFDB_SideWiperRelay : 86|2@1+ (1,0) [0|3] "" Vector__XXX
 SG_ FFDB_QuickCouplerRelay : 14|2@1+ (1,0) [0|3] "" Vector__XXX
 SG_ FFDB_HSTCutoffSV : 20|2@1+ (1,0) [0|3] "" Vector__XXX
 SG_ FFDB_EngineStopRelay : 12|2@1+ (1,0) [0|3] "" Vector__XXX
 SG_ FFDB_TrunSigRH_Relay : 70|2@1+ (1,0) [0|3] "" Vector__XXX
 SG_ FFDB_TrunSigLH_Relay : 68|2@1+ (1,0) [0|3] "" Vector__XXX
 SG_ FFDB_RearWindowHeating_Relay : 62|2@1+ (1,0) [0|3] "" Vector__XXX
 SG_ FFDB_Horn_Relay : 66|2@1+ (1,0) [0|3] "" Vector__XXX
 SG_ FFDB_AutoShutOff_Relay : 60|2@1+ (1,0) [0|3] "" Vector__XXX
 SG_ FFDB_Acc_Relay : 64|2@1+ (1,0) [0|3] "" Vector__XXX
 SG_ FFDB_UreaSuperChargingWarnSig : 90|2@1+ (1,0) [0|3] "" Vector__XXX
 SG_ FFDB_LowBeam_Relay : 78|2@1+ (1,0) [0|3] "" Vector__XXX
 SG_ FFDB_IlluminationLamp_Relay : 74|2@1+ (1,0) [0|3] "" Vector__XXX
 SG_ FFDB_HiBeam_Relay : 76|2@1+ (1,0) [0|3] "" Vector__XXX
 SG_ FFDB_FrontWiperLowSpeed_Relay : 82|2@1+ (1,0) [0|3] "" Vector__XXX
 SG_ FFDB_FrontWiperHighSpeed_Relay : 80|2@1+ (1,0) [0|3] "" Vector__XXX
 SG_ FFDB_FrontWasher_Relay : 84|2@1+ (1,0) [0|3] "" Vector__XXX
 SG_ FFDB_EngineRunningOutSiganl : 88|2@1+ (1,0) [0|3] "" Vector__XXX
 SG_ FFDB_RotatingBeacon_Relay : 72|2@1+ (1,0) [0|3] "" Vector__XXX
 SG_ FFDB_ParkingBrakeRelease_Sol : 10|2@1+ (1,0) [0|3] "" Vector__XXX
 SG_ FFDB_Backup_Relay : 58|2@1+ (1,0) [0|3] "" Vector__XXX
 SG_ FFDB_Mirror_Heater_Relay : 56|2@1+ (1,0) [0|3] "" Vector__XXX
 SG_ FFDB_FuelHeater_Relay : 54|2@1+ (1,0) [0|3] "" Vector__XXX
 SG_ FFDB_GlowPlug_Fuel_Relay : 52|2@1+ (1,0) [0|3] "" Vector__XXX
 SG_ FFDB_GlowPlug_relay : 50|2@1+ (1,0) [0|3] "" Vector__XXX
 SG_ FFDB_EMER_SteeringTest_Relay : 48|2@1+ (1,0) [0|3] "" Vector__XXX
 SG_ FFDB_RearWasher_Relay : 46|2@1+ (1,0) [0|3] "" Vector__XXX
 SG_ FFDB_RearWiper_Relay : 44|2@1+ (1,0) [0|3] "" Vector__XXX
 SG_ FFDB_RearWorkingLamp_Relay_Cabin : 42|2@1+ (1,0) [0|3] "" Vector__XXX
 SG_ FFDB_RearworkingLamp_Relay_Radi : 40|2@1+ (1,0) [0|3] "" Vector__XXX
 SG_ FFDB_FrontWorkingLamp_Relay : 38|2@1+ (1,0) [0|3] "" Vector__XXX
 SG_ FFDB_ElecSteerSafety_Relay : 36|2@1+ (1,0) [0|3] "" Vector__XXX
 SG_ FFDB_PilotBuzzerRelay : 34|2@1+ (1,0) [0|3] "" Vector__XXX
 SG_ FFDB_LisActive_Sol : 32|2@1+ (1,0) [0|3] "" Vector__XXX
 SG_ FFDB_BucketMagnet : 26|2@1+ (1,0) [0|3] "" Vector__XXX
 SG_ FFDB_BoomMagnet : 24|2@1+ (1,0) [0|3] "" Vector__XXX
 SG_ FFDB_AxleOilCoolerSol : 6|2@1+ (1,0) [0|3] "" Vector__XXX
 SG_ FFDB_UnloadingSol : 4|2@1+ (1,0) [0|3] "" Vector__XXX
 SG_ FFDB_BrakeChargeSol : 2|2@1+ (1,0) [0|3] "" Vector__XXX
 SG_ FFDB_ReverseFanSol : 0|2@1+ (1,0) [0|3] "" Vector__XXX

BO_ 2566904353 VCU_LDSI: 20 Vector__XXX
 SG_ FFDA_OPS_SW : 110|2@1+ (1,0) [0|3] "" Vector__XXX
 SG_ FFDA_HgiFlowK : 108|2@1+ (1,0) [0|3] "" Vector__XXX
 SG_ FFDA_HgiFlowN : 106|2@1+ (1,0) [0|3] "" Vector__XXX
 SG_ FFDA_DustIndicator : 104|2@1+ (1,0) [0|3] "" Vector__XXX
 SG_ FFDA_FrontDoorSW : 102|2@1+ (1,0) [0|3] "" Vector__XXX
 SG_ FFDA_ArmRestSW_LH : 100|2@1+ (1,0) [0|3] "" Vector__XXX
 SG_ FFDA_ArmRestSW_RH : 98|2@1+ (1,0) [0|3] "" Vector__XXX
 SG_ FFDA_3rdSpoolLeverSwitch : 96|2@1+ (1,0) [0|3] "" Vector__XXX
 SG_ FFDA_BucketLeverSwutch : 94|2@1+ (1,0) [0|3] "" Vector__XXX
 SG_ FFDA_QuickCouplerLockSwitch : 82|2@1+ (1,0) [0|3] "" Vector__XXX
 SG_ FFDA_DownShiftSwitch : 80|2@1+ (1,0) [0|3] "" Vector__XXX
 SG_ FFDA_TractionControlSwitch : 88|2@1+ (1,0) [0|3] "" Vector__XXX
 SG_ FFDA_ReturnFilterSwitch : 84|2@1+ (1,0) [0|3] "" Vector__XXX
 SG_ FFDA_HydraulicLockoutSwitch : 90|2@1+ (1,0) [0|3] "" Vector__XXX
 SG_ FFDA_EngineOilPressureSwitch : 92|2@1+ (1,0) [0|3] "" Vector__XXX
 SG_ FFDA_AirCleanerSwitch : 86|2@1+ (1,0) [0|3] "" Vector__XXX
 SG_ FFDA_Preheat : 78|2@1+ (1,0) [0|3] "" Vector__XXX
 SG_ FFDA_Joystick1_YaxisDetentPosi : 76|2@1+ (1,0) [0|3] "" Vector__XXX
 SG_ FFDA_Joystick1_XaxisDetentPosi : 74|2@1+ (1,0) [0|3] "" Vector__XXX
 SG_ FFDA_HSTOilFilterWarning : 70|2@1+ (1,0) [0|3] "" Vector__XXX
 SG_ FFDA_GearboxOverTemp : 68|2@1+ (1,0) [0|3] "" Vector__XXX
 SG_ FFDA_AppKickDownSwt : 72|2@1+ (1,0) [0|3] "" Vector__XXX
 SG_ FFDA_AGSSW : 66|2@1+ (1,0) [0|3] "" Vector__XXX
 SG_ FFDA_QuickCouperSw : 64|2@1+ (1,0) [0|3] "" Vector__XXX
 SG_ FFDA_ParkingSW : 62|2@1+ (1,0) [0|3] "" Vector__XXX
 SG_ FFDA_SeatBeltSW : 60|2@1+ (1,0) [0|3] "" Vector__XXX
 SG_ FFDA_ReDefrstSW : 58|2@1+ (1,0) [0|3] "" Vector__XXX
 SG_ FFDA_HornSW : 56|2@1+ (1,0) [0|3] "" Vector__XXX
 SG_ FFDA_2ndFNRActiveSW : 54|2@1+ (1,0) [0|3] "" Vector__XXX
 SG_ FFDA_RearWiperStopSignal : 52|2@1+ (1,0) [0|3] "" Vector__XXX
 SG_ FFDA_FrontWiiperStopSignal : 50|2@1+ (1,0) [0|3] "" Vector__XXX
 SG_ FFDA_DPFForcedRegenSW : 48|2@1+ (1,0) [0|3] "" Vector__XXX
 SG_ FFDA_EmergencySteerPressureSW : 46|2@1+ (1,0) [0|3] "" Vector__XXX
 SG_ FFDA_MainSteerPressureSW : 44|2@1+ (1,0) [0|3] "" Vector__XXX
 SG_ FFDA_KickDownSW : 42|2@1+ (1,0) [0|3] "" Vector__XXX
 SG_ FFDA_AccelPedalIVS : 40|2@1+ (1,0) [0|3] "" Vector__XXX
 SG_ FFDA_ParkingBrakePressureSW : 38|2@1+ (1,0) [0|3] "" Vector__XXX
 SG_ FFDA_CoolantLevel : 36|2@1+ (1,0) [0|3] "" Vector__XXX
 SG_ FFDA_WeighingCountSW : 34|2@1+ (1,0) [0|3] "" Vector__XXX
 SG_ FFDA_EMERGENCYstopSW : 32|2@1+ (1,0) [0|3] "" Vector__XXX
 SG_ FFDA_DHLmanualSW : 30|2@1+ (1,0) [0|3] "" Vector__XXX
 SG_ FFDA_3stFNR_R : 28|2@1+ (1,0) [0|3] "" Vector__XXX
 SG_ FFDA_3stFNR_N : 26|2@1+ (1,0) [0|3] "" Vector__XXX
 SG_ FFDA_3stFNR_F : 24|2@1+ (1,0) [0|3] "" Vector__XXX
 SG_ FFDA_2stFNR_R : 22|2@1+ (1,0) [0|3] "" Vector__XXX
 SG_ FFDA_2stFNR_N : 20|2@1+ (1,0) [0|3] "" Vector__XXX
 SG_ FFDA_2stFNR_F : 18|2@1+ (1,0) [0|3] "" Vector__XXX
 SG_ FFDA_1stFNR_R : 16|2@1+ (1,0) [0|3] "" Vector__XXX
 SG_ FFDA_1stFNR_N : 14|2@1+ (1,0) [0|3] "" Vector__XXX
 SG_ FFDA_1stFNR_F : 12|2@1+ (1,0) [0|3] "" Vector__XXX
 SG_ FFDA_BrSW_Starter : 10|2@1+ (1,0) [0|3] "" Vector__XXX
 SG_ FFDA_ACCSW_Starter : 8|2@1+ (1,0) [0|3] "" Vector__XXX
 SG_ FFDA_CSW_Starter : 6|2@1+ (1,0) [0|3] "" Vector__XXX
 SG_ FFDA_PilotCutoffSW : 4|2@1+ (1,0) [0|3] "" Vector__XXX
 SG_ FFDA_ArmRestCutoffSW : 2|2@1+ (1,0) [0|3] "" Vector__XXX
 SG_ FFDA_ElecSteerselect : 0|2@1+ (1,0) [0|3] "" Vector__XXX

BO_ 2566903073 VCU_XAAI: 88 Vector__XXX
 SG_ FFD5_Cabin_Down_EPPR : 688|16@1+ (1,0) [0|2000] "mA" Vector__XXX
 SG_ FFD5_Cabin_Raise_EPPR : 672|16@1+ (1,0) [0|2000] "mA" Vector__XXX
 SG_ FFD5_BoomSwing_CCW_EPPR : 640|16@1+ (1,0) [0|2000] "mA" Vector__XXX
 SG_ FFD5_BoomSwing_CW_EPPR : 624|16@1+ (1,0) [0|2000] "mA" Vector__XXX
 SG_ FFD5_TravelPump_EPPR : 608|16@1+ (1,0) [0|2000] "mA" Vector__XXX
 SG_ FFD5_DozerDown_EPPR : 576|16@1+ (1,0) [0|2000] "mA" Vector__XXX
 SG_ FFD5_DozerUp_EPPR : 560|16@1+ (1,0) [0|2000] "mA" Vector__XXX
 SG_ FFD5_Arti_BoomDown_EPPR : 544|16@1+ (1,0) [0|2000] "mA" Vector__XXX
 SG_ FFD5_Arti_BoomUp_EPPR : 528|16@1+ (1,0) [0|2000] "mA" Vector__XXX
 SG_ FFD5_SwingLeft_EPPR : 512|16@1+ (1,0) [0|2000] "mA" Vector__XXX
 SG_ FFD5_SwingRight_EPPR : 496|16@1+ (1,0) [0|2000] "mA" Vector__XXX
 SG_ FFD5_TravelLift_Rever_EPPR : 480|16@1+ (1,0) [0|2000] "mA" Vector__XXX
 SG_ FFD5_TravelLeft_Forw_EPPR : 464|16@1+ (1,0) [0|2000] "mA" Vector__XXX
 SG_ FFD5_TravelRight_Rever_EPPR : 448|16@1+ (1,0) [0|2000] "mA" Vector__XXX
 SG_ FFD5_TravelRight_Ford_EPPR : 432|16@1+ (1,0) [0|2000] "mA" Vector__XXX
 SG_ FFD5_BucketDump_EPPR : 416|16@1+ (1,0) [0|2000] "mA" Vector__XXX
 SG_ FFD5_BucketCrowd_EPPR : 400|16@1+ (1,0) [0|2000] "mA" Vector__XXX
 SG_ FFD5_Arm2Dump_EPPR : 384|16@1+ (1,0) [0|2000] "mA" Vector__XXX
 SG_ FFD5_Arm2Crowd_EPPR : 368|16@1+ (1,0) [0|2000] "mA" Vector__XXX
 SG_ FFD5_Arm1Dump_EPPR : 352|16@1+ (1,0) [0|2000] "mA" Vector__XXX
 SG_ FFD5_Arm1Crowd_EPPR : 336|16@1+ (1,0) [0|2000] "mA" Vector__XXX
 SG_ FFD5_Boom2Up_EPPR : 320|16@1+ (1,0) [0|2000] "mA" Vector__XXX
 SG_ FFD5_Boom1Down_EPPR : 304|16@1+ (1,0) [0|2000] "mA" Vector__XXX
 SG_ FFD5_Boom1Up_EPPR : 288|16@1+ (1,0) [0|2000] "mA" Vector__XXX
 SG_ FFD5_3rd_Pump_EPPR : 592|16@1+ (1,0) [0|2000] "mA" Vector__XXX
 SG_ FFD5_351_Arm_Lock_EPPR : 272|16@1+ (1,0) [0|2000] "mA" Vector__XXX
 SG_ FFD5_331_Bucket_Crowd_Conf_EPPR : 256|16@1+ (1,0) [0|2000] "mA" Vector__XXX
 SG_ FFD5_311_Arm_Crowd_Conf_EPPR : 240|16@1+ (1,0) [0|2000] "mA" Vector__XXX
 SG_ FFD5_291_Boom_Up_Conf_EPPR : 224|16@1+ (1,0) [0|2000] "mA" Vector__XXX
 SG_ FFD5_271_ByPassCutoff_B_EPPR : 208|16@1+ (1,0) [0|2000] "mA" Vector__XXX
 SG_ FFD5_251_ByPassCutoff_A_EPPR : 192|16@1+ (1,0) [0|2000] "mA" Vector__XXX
 SG_ FFD5_231_2PumpConfluence_PV : 176|16@1+ (1,0) [0|2000] "mA" Vector__XXX
 SG_ FFD5_211_Travel_Straight_PV : 160|16@1+ (1,0) [0|2000] "mA" Vector__XXX
 SG_ FFD5_191_Press_Control_PV_2 : 144|16@1+ (1,0) [0|2000] "mA" Vector__XXX
 SG_ FFD5_171_Press_Control_PV_1 : 128|16@1+ (1,0) [0|2000] "mA" Vector__XXX
 SG_ FFD5_151_Rotating_PV_CCW : 112|16@1+ (1,0) [0|2000] "mA" Vector__XXX
 SG_ FFD5_131_Rotating_PV_CW : 96|16@1+ (1,0) [0|2000] "mA" Vector__XXX
 SG_ FFD5_111_2Way_PV_Close : 80|16@1+ (1,0) [0|2000] "mA" Vector__XXX
 SG_ FFD5_091_2Way_PV_Open : 64|16@1+ (1,0) [0|2000] "mA" Vector__XXX
 SG_ FFD5_071_Flow_Control_PV : 48|16@1+ (1,0) [0|2000] "mA" Vector__XXX
 SG_ FFD5_051_Coolant_Fan_Ctrl_PV : 32|16@1+ (1,0) [0|2000] "mA" Vector__XXX
 SG_ FFD5_031_Pump_Control_PV_Elec : 16|16@1+ (1,0) [0|2000] "mA" Vector__XXX
 SG_ FFD5_011_Pump_Control_PV_1 : 0|16@1+ (1,0) [0|2000] "mA" Vector__XXX

BO_ 2566903585 VCU_XDAI: 22 Vector__XXX
 SG_ FFD7_TRAVEL_RHPilotcutSV : 158|2@1+ (1,0) [0|3] "" Vector__XXX
 SG_ FFD7_GroundSAWModeChangeRelay : 156|2@1+ (1,0) [0|3] "" Vector__XXX
 SG_ FFD7_Reserved : 160|16@1+ (1,0) [0|65535] "" Vector__XXX
 SG_ FFD7_TrackExpationSol : 146|2@1+ (1,0) [0|3] "" Vector__XXX
 SG_ FFD7_QuickChargingIndicator : 138|2@1+ (1,0) [0|3] "" Vector__XXX
 SG_ FFD7_QuickCharging_Relay : 136|2@1+ (1,0) [0|3] "" Vector__XXX
 SG_ FFD7_PumpDeraingSol : 128|2@1+ (1,0) [0|3] "" Vector__XXX
 SG_ FFD7_PilotBuzzer : 140|2@1+ (1,0) [0|3] "" Vector__XXX
 SG_ FFD7_NormalChargingIndicator : 134|2@1+ (1,0) [0|3] "" Vector__XXX
 SG_ FFD7_LowVoltageMain_Relay : 132|2@1+ (1,0) [0|3] "" Vector__XXX
 SG_ FFD7_HVCharingSignal : 150|2@1+ (1,0) [0|3] "" Vector__XXX
 SG_ FFD7_HighVoltagePrecharge_Relay : 142|2@1+ (1,0) [0|3] "" Vector__XXX
 SG_ FFD7_HighVoltageMain_Relay : 144|2@1+ (1,0) [0|3] "" Vector__XXX
 SG_ FFD7_FANPWMSignal : 148|2@1+ (1,0) [0|3] "" Vector__XXX
 SG_ FFD7_BoomSwingSelect_Relay : 130|2@1+ (1,0) [0|3] "" Vector__XXX
 SG_ FFD7_WorkingLamp_Relay : 116|2@1+ (1,0) [0|3] "" Vector__XXX
 SG_ FFD7_ReverseLamp_Relay : 124|2@1+ (1,0) [0|3] "" Vector__XXX
 SG_ FFD7_ParkingBrake_Relay : 126|2@1+ (1,0) [0|3] "" Vector__XXX
 SG_ FFD7_MirrorHeater : 106|2@1+ (1,0) [0|3] "" Vector__XXX
 SG_ FFD7_ClearanceLamp : 104|2@1+ (1,0) [0|3] "" Vector__XXX
 SG_ FFD7_CHMSL : 112|2@1+ (1,0) [0|3] "" Vector__XXX
 SG_ FFD7_CabinLamp_Relay : 120|2@1+ (1,0) [0|3] "" Vector__XXX
 SG_ FFD7_BoomSuspensionRodSol : 110|2@1+ (1,0) [0|3] "" Vector__XXX
 SG_ FFD7_BoomSuspensionHeadSol : 108|2@1+ (1,0) [0|3] "" Vector__XXX
 SG_ FFD7_AVMWarningSignal : 118|2@1+ (1,0) [0|3] "" Vector__XXX
 SG_ FFD7_AirCompressor_Relay : 122|2@1+ (1,0) [0|3] "" Vector__XXX
 SG_ FFD7_ACcompressorStopSignal : 114|2@1+ (1,0) [0|3] "" Vector__XXX
 SG_ FFD7_RightTurnSignalLamp : 96|2@1+ (1,0) [0|3] "" Vector__XXX
 SG_ FFD7_LowHeadLamp : 100|2@1+ (1,0) [0|3] "" Vector__XXX
 SG_ FFD7_Light_Relay : 90|2@1+ (1,0) [0|3] "" Vector__XXX
 SG_ FFD7_LeftTurnSignalLamp : 94|2@1+ (1,0) [0|3] "" Vector__XXX
 SG_ FFD7_Lamp_Relay : 88|2@1+ (1,0) [0|3] "" Vector__XXX
 SG_ FFD7_HighHeadLamp : 102|2@1+ (1,0) [0|3] "" Vector__XXX
 SG_ FFD7_FineSwing : 98|2@1+ (1,0) [0|3] "" Vector__XXX
 SG_ FFD7_Beacon_Relay : 92|2@1+ (1,0) [0|3] "" Vector__XXX
 SG_ FFD7_WiperWasher_Relay : 78|2@1+ (1,0) [0|3] "" Vector__XXX
 SG_ FFD7_Wiper_Relay : 76|2@1+ (1,0) [0|3] "" Vector__XXX
 SG_ FFD7_TravelPumpHSpeed2Solvalve : 82|2@1+ (1,0) [0|3] "" Vector__XXX
 SG_ FFD7_TravelPumpHSpeed1Solvalve : 80|2@1+ (1,0) [0|3] "" Vector__XXX
 SG_ FFD7_RamLockSolValve : 86|2@1+ (1,0) [0|3] "" Vector__XXX
 SG_ FFD7_LowTravelSolValve : 84|2@1+ (1,0) [0|3] "" Vector__XXX
 SG_ FFD7_103_AutoShutoff_Relay : 74|2@1+ (1,0) [0|3] "" Vector__XXX
 SG_ FFD7_101_Airheater_Relay : 72|2@1+ (1,0) [0|3] "" Vector__XXX
 SG_ FFD7_097_Glow_Plug_Relay_2 : 70|2@1+ (1,0) [0|3] "" Vector__XXX
 SG_ FFD7_095_Glow_Plug_Relay_1 : 68|2@1+ (1,0) [0|3] "" Vector__XXX
 SG_ FFD7_093_High_Speed_Relay : 66|2@1+ (1,0) [0|3] "" Vector__XXX
 SG_ FFD7_091_Low_Speed_Relay : 64|2@1+ (1,0) [0|3] "" Vector__XXX
 SG_ FFD7_087_Inching_Relay : 62|2@1+ (1,0) [0|3] "" Vector__XXX
 SG_ FFD7_085_Spare_Relay : 60|2@1+ (1,0) [0|3] "" Vector__XXX
 SG_ FFD7_083_Back_Buzzer_Relay : 58|2@1+ (1,0) [0|3] "" Vector__XXX
 SG_ FFD7_081_Starter_Relay : 56|2@1+ (1,0) [0|3] "" Vector__XXX
 SG_ FFD7_077_Reserved : 54|2@1+ (1,0) [0|3] "" Vector__XXX
 SG_ FFD7_075_Resreved : 52|2@1+ (1,0) [0|3] "" Vector__XXX
 SG_ FFD7_073_MCV_EPPR_cutoff_SV : 50|2@1+ (1,0) [0|3] "" Vector__XXX
 SG_ FFD7_071_Bs_Spool_SV : 48|2@1+ (1,0) [0|3] "" Vector__XXX
 SG_ FFD7_067_QuickCoupler_SV : 46|2@1+ (1,0) [0|3] "" Vector__XXX
 SG_ FFD7_065_FreeBoom_Dw_SV : 44|2@1+ (1,0) [0|3] "" Vector__XXX
 SG_ FFD7_063_FreeBoom_Up_SV : 42|2@1+ (1,0) [0|3] "" Vector__XXX
 SG_ FFD7_061_TravelStraight_SV : 40|2@1+ (1,0) [0|3] "" Vector__XXX
 SG_ FFD7_057_Rotating_CCW_SV : 38|2@1+ (1,0) [0|3] "" Vector__XXX
 SG_ FFD7_055_Rotating_CW_SV : 36|2@1+ (1,0) [0|3] "" Vector__XXX
 SG_ FFD7_053_Travel_2Pump_Conflue_SV : 34|2@1+ (1,0) [0|3] "" Vector__XXX
 SG_ FFD7_051_Opt_Pedal_Safety_SV : 32|2@1+ (1,0) [0|3] "" Vector__XXX
 SG_ FFD7_047_Forceful_Regen_SV : 30|2@1+ (1,0) [0|3] "" Vector__XXX
 SG_ FFD7_045_Two_Way_Operating_SV : 28|2@1+ (1,0) [0|3] "" Vector__XXX
 SG_ FFD7_043_Unloading_SV : 26|2@1+ (1,0) [0|3] "" Vector__XXX
 SG_ FFD7_041_2Way_RH_CLOSE_SV : 24|2@1+ (1,0) [0|3] "" Vector__XXX
 SG_ FFD7_037_2Way_RH_OPEN_SV : 22|2@1+ (1,0) [0|3] "" Vector__XXX
 SG_ FFD7_035_Swing_Brake_Release_SV : 20|2@1+ (1,0) [0|3] "" Vector__XXX
 SG_ FFD7_033_Bypass_Cut_Off_SV : 18|2@1+ (1,0) [0|3] "" Vector__XXX
 SG_ FFD7_031_Reverse_SV : 16|2@1+ (1,0) [0|3] "" Vector__XXX
 SG_ FFD7_027_Forward_SV : 14|2@1+ (1,0) [0|3] "" Vector__XXX
 SG_ FFD7_025_Cruise_SV : 12|2@1+ (1,0) [0|3] "" Vector__XXX
 SG_ FFD7_023_Two_Pump_Select_SV : 10|2@1+ (1,0) [0|3] "" Vector__XXX
 SG_ FFD7_021_Reverse_Fan_SV : 8|2@1+ (1,0) [0|3] "" Vector__XXX
 SG_ FFD7_017_Breaker_Select_SV : 6|2@1+ (1,0) [0|3] "" Vector__XXX
 SG_ FFD7_015_High_Speed_SV : 4|2@1+ (1,0) [0|3] "" Vector__XXX
 SG_ FFD7_013_Relief_Press_Up_SV : 2|2@1+ (1,0) [0|3] "" Vector__XXX
 SG_ FFD7_011_Breaker_Oper_SV : 0|2@1- (1,0) [-2|1] "" Vector__XXX

BO_ 2566904097 VCU_LAAI: 76 Vector__XXX
 SG_ FFD9_PVRipper_Up : 320|16@1+ (1,0) [0|2000] "mA" Vector__XXX
 SG_ FFD9_PVRipper_Down : 336|16@1+ (1,0) [0|2000] "mA" Vector__XXX
 SG_ FFD9_PVBlade_TiltRaise : 256|16@1+ (1,0) [0|2000] "mA" Vector__XXX
 SG_ FFD9_PVBlade_TiltDown : 272|16@1+ (1,0) [0|2000] "mA" Vector__XXX
 SG_ FFD9_PVBlade_TiltAngleRight : 288|16@1+ (1,0) [0|2000] "mA" Vector__XXX
 SG_ FFD9_PVBlade_TiltAngleLeft : 304|16@1+ (1,0) [0|2000] "mA" Vector__XXX
 SG_ FFD9_CondensorFanControl : 352|16@1+ (0.01,-321.27) [-321.27|334.08] "" Vector__XXX
 SG_ FFD9_CACFanControl : 368|16@1+ (0.01,-321.27) [-321.27|334.08] "" Vector__XXX
 SG_ FFD9_PVBlade_TiltRight : 224|16@1+ (1,0) [0|2000] "mA" Vector__XXX
 SG_ FFD9_PVBlade_TiltLeft : 240|16@1+ (1,0) [0|2000] "mA" Vector__XXX
 SG_ FFD9_4thSpoolEPPR_B : 128|16@1+ (1,0) [0|2000] "mA" Vector__XXX
 SG_ FFD9_4thSpoolEPPR_A : 112|16@1+ (1,0) [0|2000] "mA" Vector__XXX
 SG_ FFD9_Option2EPPR : 96|16@1+ (1,0) [0|2000] "mA" Vector__XXX
 SG_ FFD9_Option1EPPR : 80|16@1+ (1,0) [0|2000] "mA" Vector__XXX
 SG_ FFD9_BucketDumpEPPR : 64|16@1+ (1,0) [0|2000] "mA" Vector__XXX
 SG_ FFD9_BucketCrowdEPPR : 48|16@1+ (1,0) [0|2000] "mA" Vector__XXX
 SG_ FFD9_BoomFloatEPPR : 32|16@1+ (1,0) [0|2000] "mA" Vector__XXX
 SG_ FFD9_BoomRaiseEPPR : 16|16@1+ (1,0) [0|2000] "mA" Vector__XXX
 SG_ FFD9_FanControlEPPR : 0|16@1+ (1,0) [0|2000] "mA" Vector__XXX

BO_ 2566903841 VCU_LASI: 136 Vector__XXX
 SG_ FFD8_LS_PS : 224|16@1+ (0.0625,0) [0|500] "bar" Vector__XXX
 SG_ FFD8_TwoSpeedPS : 208|16@1+ (0.0625,0) [0|500] "bar" Vector__XXX
 SG_ FFD8_TiltBackPS : 128|16@1+ (0.0625,0) [0|500] "bar" Vector__XXX
 SG_ FFD8_EngineControlDial : 112|16@1+ (1,0) [0|65535] "V" Vector__XXX
 SG_ FFD8_ACPsensorPressure : 544|16@1+ (1,0) [0|65535] "" Vector__XXX
 SG_ FFD8_ParkingBrakePress : 96|16@1+ (0.0625,0) [0|500] "bar" Vector__XXX
 SG_ FFD8_Joystick1Grip_YaxisPosi : 736|10@1+ (1,0) [0|1023] "" Vector__XXX
 SG_ FFD8_Joystick1_YaxisPosi : 720|10@1+ (1,0) [0|1023] "" Vector__XXX
 SG_ FFD8_Joystick1_XaxisPosi : 704|10@1+ (1,0) [0|1023] "" Vector__XXX
 SG_ FFD8_CoolantTemp : 400|16@1+ (1,-40) [-40|210] "C" Vector__XXX
 SG_ FFD8_TMS_Voltage : 768|16@1+ (1,0) [0|65535] "" Vector__XXX
 SG_ FFD8_WL_EMCVLeverOption_B : 688|16@1+ (1,0) [0|65535] "" Vector__XXX
 SG_ FFD8_WL_EMCVLeverOption_A : 672|16@1+ (1,0) [0|65535] "" Vector__XXX
 SG_ FFD8_WL_EMCVLeverBucket_B : 656|16@1+ (1,0) [0|65535] "" Vector__XXX
 SG_ FFD8_WL_EMCVLeverBucket_A : 640|16@1+ (1,0) [0|65535] "" Vector__XXX
 SG_ FFD8_WL_EMCVLeverBoom_B : 624|16@1+ (1,0) [0|65535] "" Vector__XXX
 SG_ FFD8_WL_EMCVLeverBoom_A : 608|16@1+ (1,0) [0|65535] "" Vector__XXX
 SG_ FFD8_WL_ElecSteerValve : 592|16@1+ (1,0) [0|65535] "%" Vector__XXX
 SG_ FFD8_WL_ElecSteerLever_B : 576|16@1+ (1,0) [0|65535] "" Vector__XXX
 SG_ FFD8_WL_ElecSteerLever_A : 560|16@1+ (1,0) [0|65535] "" Vector__XXX
 SG_ FFD8_BatteryVoltage : 512|16@1+ (1,0) [0|40000] "" Vector__XXX
 SG_ FFD8_AlternatorVoltage : 496|16@1+ (1,0) [0|40000] "" Vector__XXX
 SG_ FFD8_WL_AxleOilTemp : 432|16@1+ (1,-40) [-40|210] "deg" Vector__XXX
 SG_ FFD8_HydraulicTemp : 416|16@1+ (1,-40) [-40|210] "deg" Vector__XXX
 SG_ FFD8_WIFSensorVoltage : 368|16@1+ (1,0) [0|65535] "" Vector__XXX
 SG_ FFD8_FuelLevel : 352|16@1+ (1,0) [0|65535] "" Vector__XXX
 SG_ FFD8_WL_BrakePedal_B : 304|16@1+ (1,0) [0|65535] "" Vector__XXX
 SG_ FFD8_WL_BrakePedal_A : 288|16@1+ (1,0) [0|65535] "" Vector__XXX
 SG_ FFD8_AccelPedalVoltage_Wheel : 272|16@1+ (1,0) [0|65535] "" Vector__XXX
 SG_ FFD8_WL_AngleSensorBucket_B : 192|16@1+ (1,0) [0|65535] "" Vector__XXX
 SG_ FFD8_WL_AngleSensorBucket_A : 176|16@1+ (1,0) [0|65535] "" Vector__XXX
 SG_ FFD8_WL_AngleSensorBoom_B : 160|16@1+ (1,0) [0|65535] "" Vector__XXX
 SG_ FFD8_WL_AngleSensorBoom_A : 144|16@1+ (1,0) [0|65535] "" Vector__XXX
 SG_ FFD8_WL_FanMotorPressure : 80|16@1+ (0.0625,0) [0|500] "bar" Vector__XXX
 SG_ FFD8_WL_BrakeOilPressure : 64|16@1+ (0.0625,0) [0|500] "bar" Vector__XXX
 SG_ FFD8_WL_SteerPressure : 48|16@1+ (0.0625,0) [0|500] "bar" Vector__XXX
 SG_ FFD8_WL_BoomRodPressure : 32|16@1+ (0.0625,0) [0|500] "bar" Vector__XXX
 SG_ FFD8_WL_BoomHeadPressure : 16|16@1+ (0.0625,0) [0|500] "bar" Vector__XXX
 SG_ FFD8_WL_MainPressure : 0|16@1+ (0.0625,0) [0|500] "bar" Vector__XXX

BO_ 2566903329 VCU_XDSI: 29 Vector__XXX
 SG_ FFD6_CabinLowerPositionSW : 194|2@1+ (1,0) [0|3] "" Vector__XXX
 SG_ FFD6_CabinElev_Active_SW : 192|2@1+ (1,0) [0|3] "" Vector__XXX
 SG_ FFD6_GroundSAQInitialSwitch : 188|2@1+ (1,0) [0|3] "" Vector__XXX
 SG_ FFD6_Reserved : 190|36@1+ (1,0) [0|68719476735] "" Vector__XXX
 SG_ FFD6_HydraulicWakeUpSwitch : 184|2@1+ (1,0) [0|3] "" Vector__XXX
 SG_ FFD6_HighVoltageChargingSwitch : 180|2@1+ (1,0) [0|3] "" Vector__XXX
 SG_ FFD6_FanErrorSignal : 186|2@1+ (1,0) [0|3] "" Vector__XXX
 SG_ FFD6_EmergencyStopSwitch : 182|2@1+ (1,0) [0|3] "" Vector__XXX
 SG_ FFD6_SwingAlignSwitch : 162|2@1+ (1,0) [0|3] "" Vector__XXX
 SG_ FFD6_RamLockReverse_SW : 176|2@1+ (1,0) [0|3] "" Vector__XXX
 SG_ FFD6_ParkingBrakePressure_SW : 178|2@1+ (1,0) [0|3] "" Vector__XXX
 SG_ FFD6_MultiFucntion_SW : 160|2@1+ (1,0) [0|3] "" Vector__XXX
 SG_ FFD6_MirrorHeater_SW : 164|2@1+ (1,0) [0|3] "" Vector__XXX
 SG_ FFD6_KeySwitchBR : 170|2@1+ (1,0) [0|3] "" Vector__XXX
 SG_ FFD6_DozerOutrigger_SW : 166|2@1+ (1,0) [0|3] "" Vector__XXX
 SG_ FFD6_AirCompressorPressure_SW : 174|2@1+ (1,0) [0|3] "" Vector__XXX
 SG_ FFD6_2waySwitchingSelect_SW : 168|2@1+ (1,0) [0|3] "" Vector__XXX
 SG_ FFD6_2DMGJoystickTrigger_SW : 172|2@1+ (1,0) [0|3] "" Vector__XXX
 SG_ FFD6_RearAxleRHHallSensor_SW : 152|2@1+ (1,0) [0|3] "" Vector__XXX
 SG_ FFD6_RearAxleLHHallSensor_SW : 150|2@1+ (1,0) [0|3] "" Vector__XXX
 SG_ FFD6_FrontAxleHallSensor_SW : 148|2@1+ (1,0) [0|3] "" Vector__XXX
 SG_ FFD6_AutoDigging_SW : 158|2@1+ (1,0) [0|3] "" Vector__XXX
 SG_ FFD6_TravelPumpHighSpeed_SW : 156|2@1+ (1,0) [0|3] "" Vector__XXX
 SG_ FFD6_Doors_SW : 154|2@1+ (1,0) [0|3] "" Vector__XXX
 SG_ FFD6_Wiper_Washer_SW : 126|2@1+ (1,0) [0|3] "" Vector__XXX
 SG_ FFD6_Wiper_Conti_SW : 124|2@1+ (1,0) [0|3] "" Vector__XXX
 SG_ FFD6_Wiper_2_SW : 122|2@1+ (1,0) [0|3] "" Vector__XXX
 SG_ FFD6_Wiper_1_SW : 120|2@1+ (1,0) [0|3] "" Vector__XXX
 SG_ FFD6_Right_QuickCoupler_SW : 146|2@1+ (1,0) [0|3] "" Vector__XXX
 SG_ FFD6_Left_QuickCoupler_SW : 144|2@1+ (1,0) [0|3] "" Vector__XXX
 SG_ FFD6_Power_Mode_SW : 142|2@1+ (1,0) [0|3] "" Vector__XXX
 SG_ FFD6_Work_Mode_SW : 140|2@1+ (1,0) [0|3] "" Vector__XXX
 SG_ FFD6_Auxiliary_Mode_Select_SW : 138|2@1+ (1,0) [0|3] "" Vector__XXX
 SG_ FFD6_SwingBrake_Release_SW : 136|2@1+ (1,0) [0|3] "" Vector__XXX
 SG_ FFD6_Breaker_Float_SW : 134|2@1+ (1,0) [0|3] "" Vector__XXX
 SG_ FFD6_Swing_Priority_SW : 132|2@1+ (1,0) [0|3] "" Vector__XXX
 SG_ FFD6_Rotating_CW_SW : 130|2@1+ (1,0) [0|3] "" Vector__XXX
 SG_ FFD6_Rotating_CCW_SW : 128|2@1+ (1,0) [0|3] "" Vector__XXX
 SG_ FFD6_TMS_Status : 118|2@1+ (1,0) [0|3] "" Vector__XXX
 SG_ FFD6_RCW_Near_SW : 106|2@1+ (1,0) [0|3] "" Vector__XXX
 SG_ FFD6_RCW_Action_SW : 104|2@1+ (1,0) [0|3] "" Vector__XXX
 SG_ FFD6_ArtiBoom_SW : 116|2@1+ (1,0) [0|3] "" Vector__XXX
 SG_ FFD6_CoolantLevelSW : 114|2@1+ (1,0) [0|3] "" Vector__XXX
 SG_ FFD6_RotatingOperatingSW : 112|2@1+ (1,0) [0|3] "" Vector__XXX
 SG_ FFD6_2WayCloseOperatingSW : 110|2@1+ (1,0) [0|3] "" Vector__XXX
 SG_ FFD6_2WayOpenOperatingSW : 108|2@1+ (1,0) [0|3] "" Vector__XXX
 SG_ FFD6_Emergency_EngStop_SW : 102|2@1+ (1,0) [0|3] "" Vector__XXX
 SG_ FFD6_Opt_Pedal_Press_SW_1Way : 100|2@1+ (1,0) [0|3] "" Vector__XXX
 SG_ FFD6_SPC_SW : 98|2@1+ (1,0) [0|3] "" Vector__XXX
 SG_ FFD6_Inhibit_SW : 96|2@1+ (1,0) [0|3] "" Vector__XXX
 SG_ FFD6_Travel_Alarm_Select_SW : 94|2@1+ (1,0) [0|3] "" Vector__XXX
 SG_ FFD6_Swing_Alarm_Select_SW : 92|2@1+ (1,0) [0|3] "" Vector__XXX
 SG_ FFD6_Emergency_Steering_SW : 90|2@1+ (1,0) [0|3] "" Vector__XXX
 SG_ FFD6_High_Beam_SW : 88|2@1+ (1,0) [0|3] "" Vector__XXX
 SG_ FFD6_Stop_Lamp : 86|2@1+ (1,0) [0|3] "" Vector__XXX
 SG_ FFD6_Accel_Pedal_Valid_SW : 84|2@1+ (1,0) [0|3] "" Vector__XXX
 SG_ FFD6_Brake_Pressure_SW : 82|2@1+ (1,0) [0|3] "" Vector__XXX
 SG_ FFD6_Cruise_SW : 80|2@1+ (1,0) [0|3] "" Vector__XXX
 SG_ FFD6_Engine_Oil_Press_SW : 78|2@1+ (1,0) [0|3] "" Vector__XXX
 SG_ FFD6_Pressure_Switch_Px : 76|2@1+ (1,0) [0|3] "" Vector__XXX
 SG_ FFD6_Pressure_Switch_Py : 74|2@1+ (1,0) [0|3] "" Vector__XXX
 SG_ FFD6_Start_Up_SW : 72|2@1+ (1,0) [0|3] "" Vector__XXX
 SG_ FFD6_Preheat_Mech : 70|2@1+ (1,0) [0|3] "" Vector__XXX
 SG_ FFD6_Preheat_Elec : 68|2@1+ (1,0) [0|3] "" Vector__XXX
 SG_ FFD6_Water_In_Fuel : 66|2@1+ (1,0) [0|3] "" Vector__XXX
 SG_ FFD6_Swing_Pressure_SW : 64|2@1+ (1,0) [0|3] "" Vector__XXX
 SG_ FFD6_Joystick_Pattern_BHL : 62|2@1+ (1,0) [0|3] "" Vector__XXX
 SG_ FFD6_Joystick_Pattern_ISO : 60|2@1+ (1,0) [0|3] "" Vector__XXX
 SG_ FFD6_Reverse_Fan_SW : 58|2@1+ (1,0) [0|3] "" Vector__XXX
 SG_ FFD6_Pedal_Press_SW_2Way : 56|2@1+ (1,0) [0|3] "" Vector__XXX
 SG_ FFD6_Brake_Oil_Press_SW : 54|2@1+ (1,0) [0|3] "" Vector__XXX
 SG_ FFD6_OWD_Select_SW : 52|2@1+ (1,0) [0|3] "" Vector__XXX
 SG_ FFD6_Return_Filter : 50|2@1+ (1,0) [0|3] "" Vector__XXX
 SG_ FFD6_Pilot_Filter : 48|2@1+ (1,0) [0|3] "" Vector__XXX
 SG_ FFD6_Air_Cleaner_Indicator : 46|2@1+ (1,0) [0|3] "" Vector__XXX
 SG_ FFD6_Pilot_Cut_Off_SW : 44|2@1- (1,0) [-2|1] "" Vector__XXX
 SG_ FFD6_Intelli_Float_Boom_SW : 42|2@1+ (1,0) [0|3] "" Vector__XXX
 SG_ FFD6_One_Touch_Decel_SW : 40|2@1+ (1,0) [0|3] "" Vector__XXX
 SG_ FFD6_Ram_Lock_SW : 38|2@1+ (1,0) [0|3] "" Vector__XXX
 SG_ FFD6_Parking_SW : 36|2@1+ (1,0) [0|3] "" Vector__XXX
 SG_ FFD6_Aircon_SW : 34|2@1+ (1,0) [0|3] "" Vector__XXX
 SG_ FFD6_Joystick_FNR_Select_SW : 32|2@1+ (1,0) [0|3] "" Vector__XXX
 SG_ FFD6_Reverse_SW : 30|2@1+ (1,0) [0|3] "" Vector__XXX
 SG_ FFD6_Neutral_SW : 28|2@1+ (1,0) [0|3] "" Vector__XXX
 SG_ FFD6_Forward_SW : 26|2@1+ (1,0) [0|3] "" Vector__XXX
 SG_ FFD6_High_Speed_Select_SW : 24|2@1+ (1,0) [0|3] "" Vector__XXX
 SG_ FFD6_Low_Speed_Select_SW : 22|2@1+ (1,0) [0|3] "" Vector__XXX
 SG_ FFD6_Inching_Select_SW : 20|2@1+ (1,0) [0|3] "" Vector__XXX
 SG_ FFD6_Quick_Clamp : 18|2@1+ (1,0) [0|3] "" Vector__XXX
 SG_ FFD6_Two_Way_Select_SW : 16|2@1+ (1,0) [0|3] "" Vector__XXX
 SG_ FFD6_Breaker_Select_SW : 14|2@1+ (1,0) [0|3] "" Vector__XXX
 SG_ FFD6_Working_Lamp_SW : 12|2@1+ (1,0) [0|3] "" Vector__XXX
 SG_ FFD6_Hi_Speed_SW_A : 10|2@1+ (1,0) [0|3] "" Vector__XXX
 SG_ FFD6_Hi_Speed_SW_M : 8|2@1+ (1,0) [0|3] "" Vector__XXX
 SG_ FFD6_Travel_Select_SW : 6|2@1+ (1,0) [0|3] "" Vector__XXX
 SG_ FFD6_Breaker_Operator_SW : 4|2@1+ (1,0) [0|3] "" Vector__XXX
 SG_ FFD6_Power_Max_SW : 2|2@1+ (1,0) [0|3] "" Vector__XXX
 SG_ FFD6_Alternator : 0|2@1+ (1,0) [0|3] "" Vector__XXX

BO_ 2566870275 TCU_ZFCST: 8 Vector__XXX
 SG_ FF55_APP : 32|8@1+ (0.4,0) [0|100] "%" Vector__XXX
 SG_ FF55_Extend_ColdstartPhase : 24|8@1- (1,0) [-128|127] "" Vector__XXX
 SG_ FF55_BreakCondition : 8|8@1+ (1,0) [0|255] "" Vector__XXX
 SG_ FF55_GeneralStatus : 0|8@1+ (1,0) [0|255] "" Vector__XXX

BO_ 2566866179 TCU_ZFETC9: 8 Vector__XXX
 SG_ FF45_GearHuntingProtectionState : 4|2@1- (1,0) [-2|1] "" Vector__XXX
 SG_ FF45_OverspeedWarnTransOutput : 18|2@1+ (1,0) [0|3] "" Vector__XXX
 SG_ FF45_OverspeedWarningTransInput : 16|2@1+ (1,0) [0|3] "" Vector__XXX
 SG_ FF45_TrmSumpHeatState : 32|2@1+ (1,0) [0|3] "" Vector__XXX
 SG_ FF45_TrmTemperatureLimitMode : 0|2@1+ (1,0) [0|3] "" Vector__XXX

BO_ 2566864899 TCU_ZFHC: 8 Vector__XXX
 SG_ FF40_CalibrationHeatup : 54|2@1+ (1,0) [0|3] "" Vector__XXX
 SG_ FF40_StartCondition : 56|8@1+ (1,0) [0|255] "" Vector__XXX
 SG_ FF40_BreakCondition : 8|8@1+ (1,0) [0|255] "" Vector__XXX
 SG_ FF40_GeneralStatus : 0|8@1+ (1,0) [0|255] "" Vector__XXX

BO_ 2566870787 TCU_ZFETC10: 8 Vector__XXX
 SG_ ZFETC10MinESR : 0|8@1+ (1,0) [0|255] "" Vector__XXX
 SG_ ZFETC10MaxESR : 8|8@1+ (1,0) [0|255] "" Vector__XXX

BO_ 2365543969 VCU_KeyPad_LED_E25: 8 Vector__XXX
 SG_ FF56_HydLockCenterIndicator : 60|2@1+ (1,0) [0|3] "" Vector__XXX
 SG_ FF56_AutoIdle_Left_Indi : 58|2@1+ (1,0) [0|3] "" Vector__XXX
 SG_ FF56_AutoIdle_Center_Indi : 56|2@1+ (1,0) [0|3] "" Vector__XXX
 SG_ FF56_AutoIdle_Right_Indi : 54|2@1+ (1,0) [0|3] "" Vector__XXX
 SG_ FF56_Power_Mode_Right_Indi : 12|2@1+ (1,0) [0|3] "" Vector__XXX
 SG_ FF56_Power_Mode_Left_Indi : 16|2@1+ (1,0) [0|3] "" Vector__XXX
 SG_ FF56_Power_Mode_Center_Indi : 14|2@1+ (1,0) [0|3] "" Vector__XXX
 SG_ FF56_WorkModeRight : 18|2@1- (1,0) [-2|1] "" Vector__XXX
 SG_ FF56_WorkModeLeft : 22|2@1- (1,0) [-2|1] "" Vector__XXX
 SG_ FF56_WorkModeCenter : 20|2@1- (1,0) [-2|1] "" Vector__XXX
 SG_ FF56_TrailerHitchBrakeRight : 36|2@1- (1,0) [-2|1] "" Vector__XXX
 SG_ FF56_TrailerHitchBrakeLeft : 40|2@1- (1,0) [-2|1] "" Vector__XXX
 SG_ FF56_TrailerHitchBrakeCenter : 38|2@1- (1,0) [-2|1] "" Vector__XXX
 SG_ FF56_JoystickSteeringRight : 48|2@1- (1,0) [-2|1] "" Vector__XXX
 SG_ FF56_JoystickSteeringLeft : 52|2@1- (1,0) [-2|1] "" Vector__XXX
 SG_ FF56_JoystickSteeringCenter : 50|2@1- (1,0) [-2|1] "" Vector__XXX
 SG_ FF56_FineSwingRight : 42|2@1- (1,0) [-2|1] "" Vector__XXX
 SG_ FF56_FineSwingLeft : 46|2@1- (1,0) [-2|1] "" Vector__XXX
 SG_ FF56_FineSwingCenter : 44|2@1- (1,0) [-2|1] "" Vector__XXX
 SG_ FF56_BoomSwingModeRight : 24|2@1- (1,0) [-2|1] "" Vector__XXX
 SG_ FF56_BoomSwingModeLeft : 28|2@1- (1,0) [-2|1] "" Vector__XXX
 SG_ FF56_BoomSwingModeCenter : 26|2@1- (1,0) [-2|1] "" Vector__XXX
 SG_ FF56_AutoHoldBrakeRight : 30|2@1- (1,0) [-2|1] "" Vector__XXX
 SG_ ZFENG_ESLC : 32|4@1+ (1,0) [0|15] "" Vector__XXX
 SG_ ZFENGMinESR : 0|8@1+ (10,0) [0|2550] "" Vector__XXX

BO_ 2566865155 TCU_ZFETC8: 8 Vector__XXX
 SG_ ZFETC8_TEMF : 40|4@1+ (1,0) [0|15] "" Vector__XXX

BO_ 2566844705 VCU_CCVS1: 8 Vector__XXX
 SG_ FEF1_ParkingBrakeSwitch : 2|2@1+ (1,0) [0|3] "" Vector__XXX
 SG_ FEF1_BrakeSwitch : 28|2@1+ (1,0) [0|3] "" Vector__XXX

BO_ 2565867011 TCU_EAC1: 8 Vector__XXX
 SG_ F006_DiffLockStateCentral : 16|2@1+ (1,0) [0|3] "" Vector__XXX

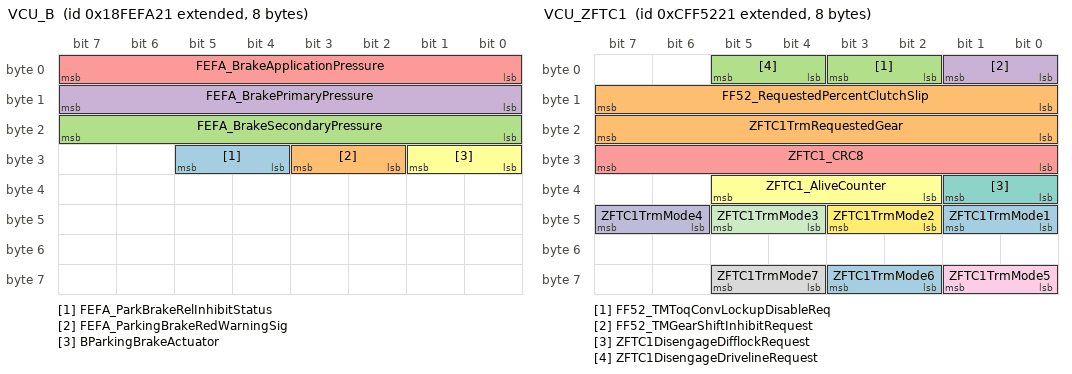
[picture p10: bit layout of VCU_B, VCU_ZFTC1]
BO_ 2566847009 VCU_B: 8 Vector__XXX
 SG_ FEFA_ParkBrakeRelInhibitStatus : 28|2@1+ (1,0) [0|3] "" Vector__XXX
 SG_ FEFA_ParkingBrakeRedWarningSig : 26|2@1+ (1,0) [0|3] "" Vector__XXX
 SG_ FEFA_BrakeSecondaryPressure : 16|8@1+ (1,0) [0|255] "" Vector__XXX
 SG_ FEFA_BrakePrimaryPressure : 8|8@1+ (1,0) [0|255] "" Vector__XXX
 SG_ FEFA_BrakeApplicationPressure : 0|8@1+ (1,0) [0|255] "" Vector__XXX
 SG_ BParkingBrakeActuator : 24|2@1+ (1,0) [0|3] "" Vector__XXX

BO_ 2566846467 TCU_TRF1: 8 Vector__XXX
 SG_ TRF1TrmOilTemperature : 32|16@1+ (0.03125,-273) [-273|1735] "degC" Vector__XXX

BO_ 2566755587 TCU_TRF2: 8 Vector__XXX
 SG_ TRF2TrqConOilOutletTemp : 8|16@1+ (0.03125,-273) [-273|1735] "deg" Vector__XXX
 SG_ TRF2TrmOilFilterRestrictSwitch : 0|2@1+ (1,0) [0|3] "" Vector__XXX

BO_ 2365542945 VCU_ZFTC1: 8 Vector__XXX
 SG_ ZFTC1TrmMode6 : 58|2@1+ (1,0) [0|3] "" Vector__XXX
 SG_ FF52_RequestedPercentClutchSlip : 8|8@1+ (0.4,0) [0|100] "%" Vector__XXX
 SG_ FF52_TMToqConvLockupDisableReq : 2|2@1+ (1,0) [0|3] "" Vector__XXX
 SG_ FF52_TMGearShiftInhibitRequest : 0|2@1+ (1,0) [0|3] "" Vector__XXX
 SG_ ZFTC1_CRC8 : 24|8@1+ (1,0) [0|255] "" Vector__XXX
 SG_ ZFTC1_AliveCounter : 34|4@1+ (1,0) [0|15] "" Vector__XXX
 SG_ ZFTC1DisengageDifflockRequest : 32|2@1+ (1,0) [0|3] "" Vector__XXX
 SG_ ZFTC1TrmMode7 : 60|2@1+ (1,0) [0|3] "" Vector__XXX
 SG_ ZFTC1TrmMode5 : 56|2@1+ (1,0) [0|3] "" Vector__XXX
 SG_ ZFTC1TrmMode4 : 46|2@1+ (1,0) [0|3] "" Vector__XXX
 SG_ ZFTC1TrmMode3 : 44|2@1+ (1,0) [0|3] "" Vector__XXX
 SG_ ZFTC1TrmMode2 : 42|2@1+ (1,0) [0|3] "" Vector__XXX
 SG_ ZFTC1TrmMode1 : 40|2@1+ (1,0) [0|3] "" Vector__XXX
 SG_ ZFTC1TrmRequestedGear : 16|8@1+ (1,-125) [-125|130] "" Vector__XXX
 SG_ ZFTC1DisengageDrivelineRequest : 4|2@1+ (1,0) [0|3] "" Vector__XXX

BO_ 2566841088 ECU_EC1: 39 Vector__XXX
 SG_ FEE3_EngRqSpCtrlRgUpperLimit : 200|8@1+ (10,0) [0|2550] "rpm" Vector__XXX
 SG_ FEE3_EngRqSpCtrlRgLowerLimit : 192|8@1+ (10,0) [0|2550] "rpm" Vector__XXX
 SG_ EC1EGDefaultTorqueLimit : 256|16@1+ (1,0) [0|64255] "Nm" Vector__XXX
 SG_ EC1Engine_Max_Overr_Speed_Point7 : 168|16@1+ (0.125,0) [0|8031.88] "rpm" Vector__XXX
 SG_ EC1Engine_PercTorque_Idle_Point1 : 16|8@1+ (1,-125) [-125|125] "%" Vector__XXX
 SG_ EC1Engine_PercTorque_Point2 : 40|8@1+ (1,-125) [-125|125] "%" Vector__XXX
 SG_ EC1Engine_PercTorque_Point3 : 64|8@1+ (1,-125) [-125|125] "%" Vector__XXX
 SG_ EC1Engine_PercTorque_Point4 : 88|8@1+ (1,-125) [-125|125] "%" Vector__XXX
 SG_ EC1Engine_PercTorque_Point5 : 112|8@1+ (1,-125) [-125|125] "%" Vector__XXX
 SG_ EC1Engine_Speed_Idle_Point1 : 0|16@1+ (0.125,0) [0|8031.88] "rpm" Vector__XXX
 SG_ EC1Engine_Speed_Point2 : 24|16@1+ (0.125,0) [0|8031.88] "rpm" Vector__XXX
 SG_ EC1Engine_Speed_Point3 : 48|16@1+ (0.125,0) [0|8031.88] "rpm" Vector__XXX
 SG_ EC1Engine_Speed_Point4 : 72|16@1+ (0.125,0) [0|8031.88] "rpm" Vector__XXX
 SG_ EC1Engine_Speed_Point5 : 96|16@1+ (0.125,0) [0|8031.88] "rpm" Vector__XXX
 SG_ EC1Engine_Speed_Point6 : 120|16@1+ (1,0) [0|8031.88] "rpm" Vector__XXX
 SG_ EC1Engine_Reference_Torque : 152|16@1+ (1,0) [0|64255] "Nm" Vector__XXX

BO_ 2566840064 ECU_EEC3: 8 Vector__XXX
 SG_ EEC3ATS1ExhaustGasMassFlow : 40|16@1+ (0.2,0) [0|12851] "kg/h" Vector__XXX
 SG_ EEC3EnginesDesiredOpSpeed : 8|16@1+ (0.125,0) [0|8031.875] "rpm" Vector__XXX
 SG_ EEC3EstimEngParaLossesPercTorque : 32|8@1+ (1,-125) [-125|125] "%" Vector__XXX
 SG_ EEC3NominalFrictionPercentTorque : 0|8@1+ (1,-125) [-125|125] "%" Vector__XXX

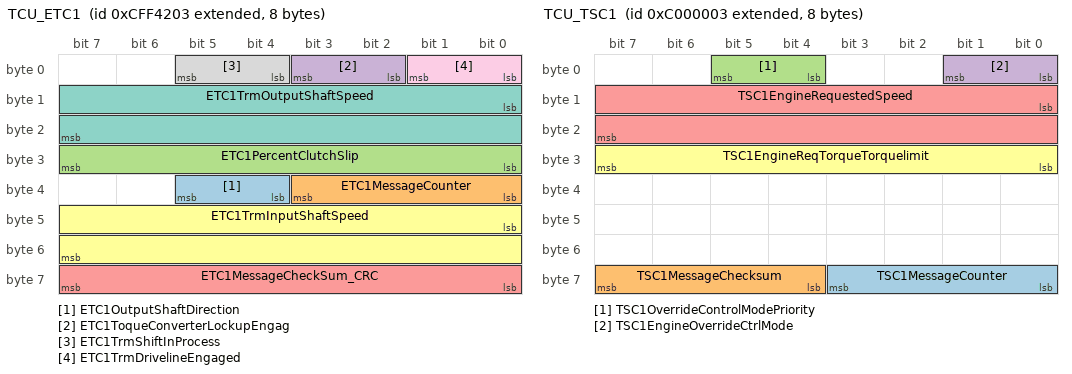
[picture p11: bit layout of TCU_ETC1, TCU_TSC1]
BO_ 2365538819 TCU_ETC1: 8 Vector__XXX
 SG_ ETC1OutputShaftDirection : 36|2@1+ (1,0) [0|3] "" Vector__XXX
 SG_ ETC1MessageCounter : 32|4@1+ (1,0) [0|15] "" Vector__XXX
 SG_ ETC1PercentClutchSlip : 24|8@1+ (1,0) [0|255] "" Vector__XXX
 SG_ ETC1ToqueConverterLockupEngag : 2|2@1+ (1,0) [0|3] "" Vector__XXX
 SG_ ETC1MessageCheckSum_CRC : 56|8@1+ (1,0) [0|255] "" Vector__XXX
 SG_ ETC1TrmInputShaftSpeed : 40|16@1+ (0.125,0) [0|8031.875] "rpm" Vector__XXX
 SG_ ETC1TrmOutputShaftSpeed : 8|16@1+ (0.125,0) [0|8031.875] "rpm" Vector__XXX
 SG_ ETC1TrmShiftInProcess : 4|2@1+ (1,0) [0|3] "" Vector__XXX
 SG_ ETC1TrmDrivelineEngaged : 0|2@1+ (1,0) [0|3] "" Vector__XXX

BO_ 2348810243 TCU_TSC1: 8 Vector__XXX
 SG_ TSC1MessageCounter : 56|4@1+ (1,0) [0|15] "" Vector__XXX
 SG_ TSC1MessageChecksum : 60|4@1+ (1,0) [0|15] "" Vector__XXX
 SG_ TSC1OverrideControlModePriority : 4|2@1+ (1,0) [0|3] "" Vector__XXX
 SG_ TSC1EngineOverrideCtrlMode : 0|2@1+ (1,0) [0|3] "" Vector__XXX
 SG_ TSC1EngineRequestedSpeed : 8|16@1+ (0.125,0) [0|8031.875] "rpm" Vector__XXX
 SG_ TSC1EngineReqTorqueTorquelimit : 24|8@1+ (1,-125) [-125|125] "%" Vector__XXX

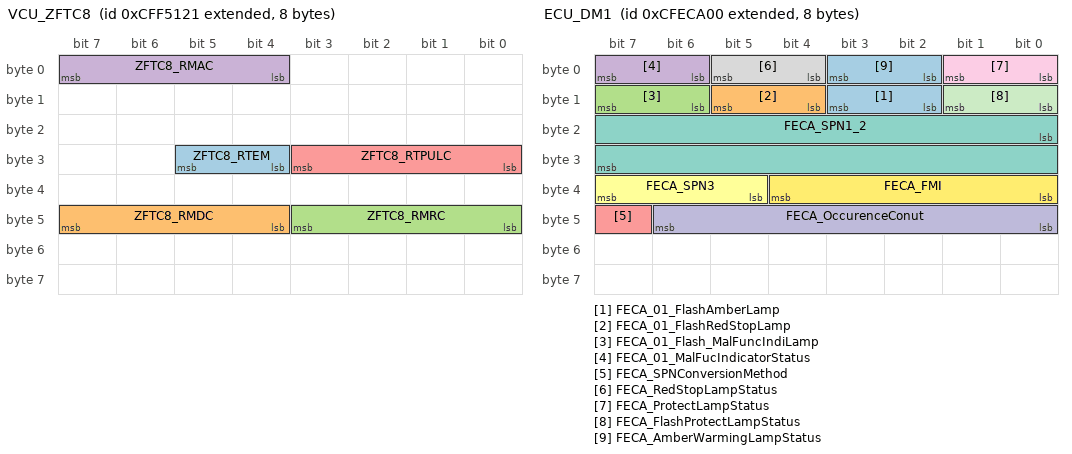
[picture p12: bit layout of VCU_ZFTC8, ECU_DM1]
BO_ 2365542689 VCU_ZFTC8: 8 Vector__XXX
 SG_ ZFTC8_RTEM : 28|2@1+ (1,0) [0|3] "" Vector__XXX
 SG_ ZFTC8_RMDC : 44|4@1+ (1,0) [0|15] "" Vector__XXX
 SG_ ZFTC8_RMRC : 40|4@1+ (1,0) [0|15] "" Vector__XXX
 SG_ ZFTC8_RMAC : 4|4@1+ (1,0) [0|15] "" Vector__XXX
 SG_ ZFTC8_RTPULC : 24|4@1+ (1,0) [0|15] "" Vector__XXX

BO_ 2566767875 TCU_ECUID: 97 Vector__XXX
 SG_ ECUType : 24|8@1+ (1,0) [0|255] "" Vector__XXX
 SG_ ECUSerialNumber : 8|8@1+ (1,0) [0|255] "" Vector__XXX
 SG_ ECULocation : 16|8@1+ (1,0) [0|255] "" Vector__XXX
 SG_ ECU_Manufacturer : 32|8@1+ (1,0) [0|255] "" Vector__XXX
 SG_ ECU_PartNumber : 0|8@1+ (1,0) [0|255] "" Vector__XXX

BO_ 2566838787 TCU_SOFT: 66 Vector__XXX
 SG_ FEDA_OptionalField_2 : 424|8@1+ (1,0) [0|255] "" Vector__XXX
 SG_ FEDA_OptionalField_1 : 320|8@1+ (1,0) [0|255] "" Vector__XXX
 SG_ FEDA_TransmissionPartNumber : 216|8@1+ (1,0) [0|255] "" Vector__XXX
 SG_ FEDA_SWVersion : 112|8@1+ (1,0) [0|255] "" Vector__XXX
 SG_ FEDA_SWPartNumber : 8|8@1+ (1,0) [0|255] "" Vector__XXX
 SG_ FEDA_NumberOfSWIdentification : 0|8@1+ (1,0) [0|250] "steps" Vector__XXX

BO_ 2565603072 TPDT: 8 Vector__XXX
 SG_ SequenceNumber : 0|8@1+ (1,0) [0|252] "" Vector__XXX

BO_ 2565668608 TPCM: 8 Vector__XXX
 SG_ TPCM_Mux M : 0|8@1+ (1,0) [0|0] "" Vector__XXX
 SG_ PGNumber : 40|24@1+ (1,0) [0|16777200] "" Vector__XXX
 SG_ TotalNumberOfPacketsEoMA m19 : 24|8@1+ (1,0) [0|255] "" Vector__XXX
 SG_ TotalMessageSizeEoMA m19 : 8|16@1+ (1,0) [0|64255] "counts" Vector__XXX
 SG_ TotalMessageSizeBAM m32 : 8|16@1+ (1,0) [0|64255] "counts" Vector__XXX
 SG_ TotalNumberOfPacketsBAM m32 : 24|8@1+ (1,0) [0|255] "" Vector__XXX
 SG_ ConnectionAbortReason m255 : 8|8@1+ (1,0) [0|255] "" Vector__XXX
 SG_ NextPacketNumberToBeSent m17 : 16|8@1+ (1,0) [0|255] "" Vector__XXX
 SG_ NumberOfPacketsThatCanBeSent m17 : 8|8@1+ (1,0) [0|255] "" Vector__XXX
 SG_ MaximumNumberOfPackets m16 : 32|8@1+ (1,0) [0|255] "" Vector__XXX
 SG_ TotalNumberOfPackets m16 : 24|8@1+ (1,0) [0|255] "" Vector__XXX
 SG_ TotalMessageSize m16 : 8|16@1+ (1,0) [0|64255] "counts" Vector__XXX

BO_ 2565482529 VCU_RQST: 3 Vector__XXX
 SG_ ParameterGroupNumber : 0|24@1+ (1,0) [0|16777215] "" Vector__XXX

BO_ 2565537536 ECU_RQST_SA00: 3 Vector__XXX
 SG_ ParameterGroupNumber : 0|24@1+ (1,0) [0|16777215] "" Vector__XXX

BO_ 2565472289 VCU_RQST_SA21: 3 Vector__XXX
 SG_ ParameterGroupNumber : 0|24@1+ (1,0) [0|16777215] "" Vector__XXX

BO_ 2565480744 GP_RQST_SA28: 3 Vector__XXX
 SG_ ParameterGroupNumber : 0|24@1+ (1,0) [0|16777215] "" Vector__XXX

BO_ 2566834944 DM02_for_Multi: 42 Vector__XXX
 SG_ FECA_10_SPNConversionMethod : 335|1@1+ (1,0) [0|1] "" Vector__XXX
 SG_ FECA_10_SPN3 : 325|3@1+ (1,0) [0|7] "" Vector__XXX
 SG_ FECA_10_SPN1_2 : 304|16@1+ (1,0) [0|65535] "" Vector__XXX
 SG_ FECA_10_OccurenceCount : 328|7@1+ (1,0) [0|127] "" Vector__XXX
 SG_ FECA_10_FMI : 320|5@1+ (1,0) [0|31] "" Vector__XXX
 SG_ FECA_09_SPNConversionMethod : 303|1@1+ (1,0) [0|1] "" Vector__XXX
 SG_ FECA_09_SPN3 : 293|3@1+ (1,0) [0|7] "" Vector__XXX
 SG_ FECA_09_SPN1_2 : 272|16@1+ (1,0) [0|65535] "" Vector__XXX
 SG_ FECA_09_OccurenceCount : 296|7@1+ (1,0) [0|127] "" Vector__XXX
 SG_ FECA_09_FMI : 288|5@1+ (1,0) [0|31] "" Vector__XXX
 SG_ FECA_08_SPNConversionMethod : 271|1@1+ (1,0) [0|1] "" Vector__XXX
 SG_ FECA_08_SPN3 : 261|3@1+ (1,0) [0|7] "" Vector__XXX
 SG_ FECA_08_SPN1_2 : 240|16@1+ (1,0) [0|65535] "" Vector__XXX
 SG_ FECA_08_OccurenceCount : 264|7@1+ (1,0) [0|127] "" Vector__XXX
 SG_ FECA_08_FMI : 256|5@1+ (1,0) [0|31] "" Vector__XXX
 SG_ FECA_07_SPNConversionMethod : 239|1@1+ (1,0) [0|1] "" Vector__XXX
 SG_ FECA_07_SPN3 : 229|3@1+ (1,0) [0|7] "" Vector__XXX
 SG_ FECA_07_SPN1_2 : 208|16@1+ (1,0) [0|65535] "" Vector__XXX
 SG_ FECA_07_OccurenceCount : 232|7@1+ (1,0) [0|127] "" Vector__XXX
 SG_ FECA_07_FMI : 224|5@1+ (1,0) [0|31] "" Vector__XXX
 SG_ FECA_06_SPNConversionMethod : 207|1@1+ (1,0) [0|1] "" Vector__XXX
 SG_ FECA_06_SPN3 : 197|3@1+ (1,0) [0|7] "" Vector__XXX
 SG_ FECA_06_SPN1_2 : 176|16@1+ (1,0) [0|65535] "" Vector__XXX
 SG_ FECA_06_OccurenceCount : 200|7@1+ (1,0) [0|127] "" Vector__XXX
 SG_ FECA_06_FMI : 192|5@1+ (1,0) [0|31] "" Vector__XXX
 SG_ FECA_05_SPNConversionMethod : 175|1@1+ (1,0) [0|1] "" Vector__XXX
 SG_ FECA_05_SPN3 : 165|3@1+ (1,0) [0|7] "" Vector__XXX
 SG_ FECA_05_SPN1_2 : 144|16@1+ (1,0) [0|65535] "" Vector__XXX
 SG_ FECA_05_OccurenceCount : 168|7@1+ (1,0) [0|127] "" Vector__XXX
 SG_ FECA_05_FMI : 160|5@1+ (1,0) [0|31] "" Vector__XXX
 SG_ FECA_04_SPNConversionMethod : 143|1@1+ (1,0) [0|1] "" Vector__XXX
 SG_ FECA_04_SPN3 : 133|3@1+ (1,0) [0|7] "" Vector__XXX
 SG_ FECA_04_SPN1_2 : 112|16@1+ (1,0) [0|65535] "" Vector__XXX
 SG_ FECA_04_OccurenceCount : 136|7@1+ (1,0) [0|127] "" Vector__XXX
 SG_ FECA_04_FMI : 128|5@1+ (1,0) [0|31] "" Vector__XXX
 SG_ FECA_03_SPNConversionMethod : 111|1@1+ (1,0) [0|1] "" Vector__XXX
 SG_ FECA_03_SPN3 : 101|3@1+ (1,0) [0|7] "" Vector__XXX
 SG_ FECA_03_SPN1_2 : 80|16@1+ (1,0) [0|65535] "" Vector__XXX
 SG_ FECA_03_OccurenceCount : 104|7@1+ (1,0) [0|127] "" Vector__XXX
 SG_ FECA_03_FMI : 96|5@1+ (1,0) [0|31] "" Vector__XXX
 SG_ FECA_02_SPNConversionMethod : 79|1@1+ (1,0) [0|1] "" Vector__XXX
 SG_ FECA_02_SPN3 : 69|3@1+ (1,0) [0|7] "" Vector__XXX
 SG_ FECA_02_SPN1_2 : 48|16@1+ (1,0) [0|65535] "" Vector__XXX
 SG_ FECA_02_OccurenceCount : 72|7@1+ (1,0) [0|127] "" Vector__XXX
 SG_ FECA_02_FMI : 64|5@1+ (1,0) [0|31] "" Vector__XXX
 SG_ FECA_01_SPNConversionMethod : 47|1@1+ (1,0) [0|1] "" Vector__XXX
 SG_ FECA_01_SPN3 : 37|3@1+ (1,0) [0|7] "" Vector__XXX
 SG_ FECA_01_SPN1_2 : 16|16@1+ (1,0) [0|65535] "" Vector__XXX
 SG_ FECA_01_RedStopLampStatus : 4|2@1+ (1,0) [0|3] "" Vector__XXX
 SG_ FECA_01_ProtectLampStatus : 0|2@1+ (1,0) [0|3] "" Vector__XXX
 SG_ FECA_01_OccurenceCount : 40|7@1+ (1,0) [0|127] "" Vector__XXX
 SG_ FECA_01_MalFucIndicatorStatus : 6|2@1+ (1,0) [0|3] "" Vector__XXX
 SG_ FECA_01_FMI : 32|5@1+ (1,0) [0|31] "" Vector__XXX
 SG_ FECA_01_FlashRedStopLamp : 12|2@1+ (1,0) [0|3] "" Vector__XXX
 SG_ FECA_01_FlashProtectLamp : 8|2@1+ (1,0) [0|3] "" Vector__XXX
 SG_ FECA_01_FlashAmberLamp : 10|2@1+ (1,0) [0|3] "" Vector__XXX
 SG_ FECA_01_Flash_MalFuncIndiLamp : 14|2@1+ (1,0) [0|3] "" Vector__XXX
 SG_ FECA_01_AmberWarmingLampStatus : 2|2@1+ (1,0) [0|3] "" Vector__XXX

BO_ 2566834688 DM01_for_Multi: 42 Vector__XXX
 SG_ FECA_10_SPNConversionMethod : 335|1@1+ (1,0) [0|1] "" Vector__XXX
 SG_ FECA_10_SPN3 : 325|3@1+ (1,0) [0|7] "" Vector__XXX
 SG_ FECA_10_SPN1_2 : 304|16@1+ (1,0) [0|65535] "" Vector__XXX
 SG_ FECA_10_OccurenceCount : 328|7@1+ (1,0) [0|127] "" Vector__XXX
 SG_ FECA_10_FMI : 320|5@1+ (1,0) [0|31] "" Vector__XXX
 SG_ FECA_09_SPNConversionMethod : 303|1@1+ (1,0) [0|1] "" Vector__XXX
 SG_ FECA_09_SPN3 : 293|3@1+ (1,0) [0|7] "" Vector__XXX
 SG_ FECA_09_SPN1_2 : 272|16@1+ (1,0) [0|65535] "" Vector__XXX
 SG_ FECA_09_OccurenceCount : 296|7@1+ (1,0) [0|127] "" Vector__XXX
 SG_ FECA_09_FMI : 288|5@1+ (1,0) [0|31] "" Vector__XXX
 SG_ FECA_08_SPNConversionMethod : 271|1@1+ (1,0) [0|1] "" Vector__XXX
 SG_ FECA_08_SPN3 : 261|3@1+ (1,0) [0|7] "" Vector__XXX
 SG_ FECA_08_SPN1_2 : 240|16@1+ (1,0) [0|65535] "" Vector__XXX
 SG_ FECA_08_OccurenceCount : 264|7@1+ (1,0) [0|127] "" Vector__XXX
 SG_ FECA_08_FMI : 256|5@1+ (1,0) [0|31] "" Vector__XXX
 SG_ FECA_07_SPNConversionMethod : 239|1@1+ (1,0) [0|1] "" Vector__XXX
 SG_ FECA_07_SPN3 : 229|3@1+ (1,0) [0|7] "" Vector__XXX
 SG_ FECA_07_SPN1_2 : 208|16@1+ (1,0) [0|65535] "" Vector__XXX
 SG_ FECA_07_OccurenceCount : 232|7@1+ (1,0) [0|127] "" Vector__XXX
 SG_ FECA_07_FMI : 224|5@1+ (1,0) [0|31] "" Vector__XXX
 SG_ FECA_06_SPNConversionMethod : 207|1@1+ (1,0) [0|1] "" Vector__XXX
 SG_ FECA_06_SPN3 : 197|3@1+ (1,0) [0|7] "" Vector__XXX
 SG_ FECA_06_SPN1_2 : 176|16@1+ (1,0) [0|65535] "" Vector__XXX
 SG_ FECA_06_OccurenceCount : 200|7@1+ (1,0) [0|127] "" Vector__XXX
 SG_ FECA_06_FMI : 192|5@1+ (1,0) [0|31] "" Vector__XXX
 SG_ FECA_05_SPNConversionMethod : 175|1@1+ (1,0) [0|1] "" Vector__XXX
 SG_ FECA_05_SPN3 : 165|3@1+ (1,0) [0|7] "" Vector__XXX
 SG_ FECA_05_SPN1_2 : 144|16@1+ (1,0) [0|65535] "" Vector__XXX
 SG_ FECA_05_OccurenceCount : 168|7@1+ (1,0) [0|127] "" Vector__XXX
 SG_ FECA_05_FMI : 160|5@1+ (1,0) [0|31] "" Vector__XXX
 SG_ FECA_04_SPNConversionMethod : 143|1@1+ (1,0) [0|1] "" Vector__XXX
 SG_ FECA_04_SPN3 : 133|3@1+ (1,0) [0|7] "" Vector__XXX
 SG_ FECA_04_SPN1_2 : 112|16@1+ (1,0) [0|65535] "" Vector__XXX
 SG_ FECA_04_OccurenceCount : 136|7@1+ (1,0) [0|127] "" Vector__XXX
 SG_ FECA_04_FMI : 128|5@1+ (1,0) [0|31] "" Vector__XXX
 SG_ FECA_03_SPNConversionMethod : 111|1@1+ (1,0) [0|1] "" Vector__XXX
 SG_ FECA_03_SPN3 : 101|3@1+ (1,0) [0|7] "" Vector__XXX
 SG_ FECA_03_SPN1_2 : 80|16@1+ (1,0) [0|65535] "" Vector__XXX
 SG_ FECA_03_OccurenceCount : 104|7@1+ (1,0) [0|127] "" Vector__XXX
 SG_ FECA_03_FMI : 96|5@1+ (1,0) [0|31] "" Vector__XXX
 SG_ FECA_02_SPNConversionMethod : 79|1@1+ (1,0) [0|1] "" Vector__XXX
 SG_ FECA_02_SPN3 : 69|3@1+ (1,0) [0|7] "" Vector__XXX
 SG_ FECA_02_SPN1_2 : 48|16@1+ (1,0) [0|65535] "" Vector__XXX
 SG_ FECA_02_OccurenceCount : 72|7@1+ (1,0) [0|127] "" Vector__XXX
 SG_ FECA_02_FMI : 64|5@1+ (1,0) [0|31] "" Vector__XXX
 SG_ FECA_01_SPNConversionMethod : 47|1@1+ (1,0) [0|1] "" Vector__XXX
 SG_ FECA_01_SPN3 : 37|3@1+ (1,0) [0|7] "" Vector__XXX
 SG_ FECA_01_SPN1_2 : 16|16@1+ (1,0) [0|65535] "" Vector__XXX
 SG_ FECA_01_RedStopLampStatus : 4|2@1+ (1,0) [0|3] "" Vector__XXX
 SG_ FECA_01_ProtectLampStatus : 0|2@1+ (1,0) [0|3] "" Vector__XXX
 SG_ FECA_01_OccurenceCount : 40|7@1+ (1,0) [0|127] "" Vector__XXX
 SG_ FECA_01_MalFucIndicatorStatus : 6|2@1+ (1,0) [0|3] "" Vector__XXX
 SG_ FECA_01_FMI : 32|5@1+ (1,0) [0|31] "" Vector__XXX
 SG_ FECA_01_FlashRedStopLamp : 12|2@1+ (1,0) [0|3] "" Vector__XXX
 SG_ FECA_01_FlashProtectLamp : 8|2@1+ (1,0) [0|3] "" Vector__XXX
 SG_ FECA_01_FlashAmberLamp : 10|2@1+ (1,0) [0|3] "" Vector__XXX
 SG_ FECA_01_Flash_MalFuncIndiLamp : 14|2@1+ (1,0) [0|3] "" Vector__XXX
 SG_ FECA_01_AmberWarmingLampStatus : 2|2@1+ (1,0) [0|3] "" Vector__XXX

BO_ 2365508096 ECU_DM1: 8 Vector__XXX
 SG_ FECA_01_FlashAmberLamp : 10|2@1+ (1,0) [0|3] "" Vector__XXX
 SG_ FECA_01_FlashRedStopLamp : 12|2@1+ (1,0) [0|3] "" Vector__XXX
 SG_ FECA_01_Flash_MalFuncIndiLamp : 14|2@1+ (1,0) [0|3] "" Vector__XXX
 SG_ FECA_01_MalFucIndicatorStatus : 6|2@1+ (1,0) [0|3] "" Vector__XXX
 SG_ FECA_SPNConversionMethod : 47|1@1+ (1,0) [0|1] "" Vector__XXX
 SG_ FECA_SPN3 : 37|3@1+ (1,0) [0|7] "" Vector__XXX
 SG_ FECA_SPN1_2 : 16|16@1+ (1,0) [0|65535] "" Vector__XXX
 SG_ FECA_RedStopLampStatus : 4|2@1+ (1,0) [0|3] "" Vector__XXX
 SG_ FECA_ProtectLampStatus : 0|2@1+ (1,0) [0|3] "" Vector__XXX
 SG_ FECA_OccurenceConut : 40|7@1+ (1,0) [0|127] "" Vector__XXX
 SG_ FECA_FlashProtectLampStatus : 8|2@1+ (1,0) [0|3] "" Vector__XXX
 SG_ FECA_FMI : 32|5@1+ (1,0) [0|31] "" Vector__XXX
 SG_ FECA_AmberWarmingLampStatus : 2|2@1+ (1,0) [0|3] "" Vector__XXX

BO_ 2566835456 DM04: 14 Vector__XXX
 SG_ FreezeFrameLength : 0|8@1+ (1,0) [0|255] "" Vector__XXX
 SG_ SuspectParameterNumber : 15|19@0+ (1,0) [0|524287] "" Vector__XXX
 SG_ FailureModeIdentifier : 24|5@1+ (1,0) [0|31] "" Vector__XXX
 SG_ OccurrenceCount : 32|7@1+ (1,0) [0|127] "" Vector__XXX
 SG_ SPNConversionMethod : 39|1@1+ (1,0) [0|1] "" Vector__XXX
 SG_ ManufacturerSpecifiedInformation : 104|8@1+ (1,0) [0|255] "" Vector__XXX

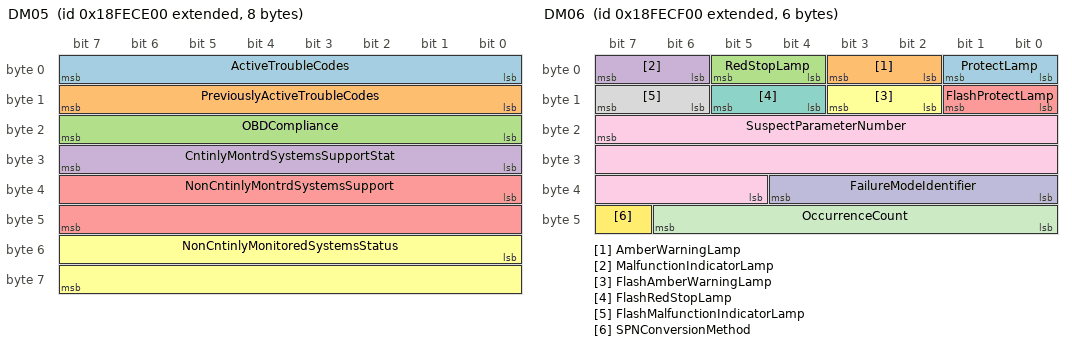
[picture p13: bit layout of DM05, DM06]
BO_ 2566835712 DM05: 8 Vector__XXX
 SG_ ActiveTroubleCodes : 0|8@1+ (1,0) [0|250] "" Vector__XXX
 SG_ PreviouslyActiveTroubleCodes : 8|8@1+ (1,0) [0|250] "" Vector__XXX
 SG_ OBDCompliance : 16|8@1+ (1,0) [0|250] "" Vector__XXX
 SG_ CntinlyMontrdSystemsSupportStat : 24|8@1+ (1,0) [0|255] "" Vector__XXX
 SG_ NonCntinlyMontrdSystemsSupport : 32|16@1+ (1,0) [0|65535] "" Vector__XXX
 SG_ NonCntinlyMonitoredSystemsStatus : 48|16@1+ (1,0) [0|65535] "" Vector__XXX

BO_ 2566835968 DM06: 6 Vector__XXX
 SG_ ProtectLamp : 0|2@1+ (1,0) [0|3] "" Vector__XXX
 SG_ AmberWarningLamp : 2|2@1+ (1,0) [0|3] "" Vector__XXX
 SG_ RedStopLamp : 4|2@1+ (1,0) [0|3] "" Vector__XXX
 SG_ MalfunctionIndicatorLamp : 6|2@1+ (1,0) [0|3] "" Vector__XXX
 SG_ FlashProtectLamp : 8|2@1+ (1,0) [0|3] "" Vector__XXX
 SG_ FlashAmberWarningLamp : 10|2@1+ (1,0) [0|3] "" Vector__XXX
 SG_ FlashRedStopLamp : 12|2@1+ (1,0) [0|3] "" Vector__XXX
 SG_ FlashMalfunctionIndicatorLamp : 14|2@1+ (1,0) [0|3] "" Vector__XXX
 SG_ SuspectParameterNumber : 23|19@0+ (1,0) [0|524287] "" Vector__XXX
 SG_ FailureModeIdentifier : 32|5@1+ (1,0) [0|31] "" Vector__XXX
 SG_ OccurrenceCount : 40|7@1+ (1,0) [0|127] "" Vector__XXX
 SG_ SPNConversionMethod : 47|1@1+ (1,0) [0|1] "" Vector__XXX

BO_ 2365460608 ElecSteer_EstimatedFlow: 8 Vector__XXX
 SG_ Av00ef_ValveState : 16|4@1+ (1,0) [0|15] "" Vector__XXX
 SG_ Av00ef_EstimatedFlowRetract : 8|8@1+ (1,-125) [-125|125] "%" Vector__XXX
 SG_ Av00ef_EstimatedFlowExtend : 0|8@1+ (1,-125) [-125|125] "%" Vector__XXX

BO_ 2365468705 VCU_AVC_ElecSteerCmd: 8 Vector__XXX
 SG_ Valve_State : 16|4@1+ (1,0) [0|15] "" Vector__XXX
 SG_ PortFlowControl : 0|8@1+ (0.4,0) [0|100] "" Vector__XXX

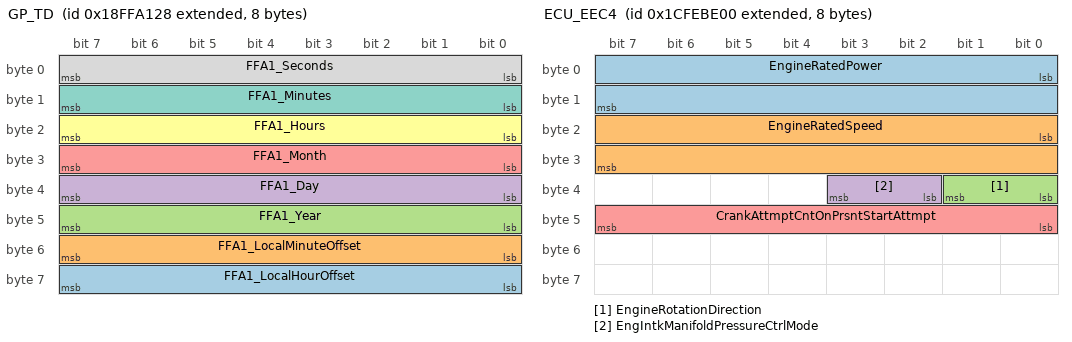
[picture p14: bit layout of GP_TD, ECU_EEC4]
BO_ 2566889768 GP_TD: 8 Vector__XXX
 SG_ FFA1_LocalHourOffset : 56|8@1+ (1,-125) [-125|130] "" Vector__XXX
 SG_ FFA1_LocalMinuteOffset : 48|8@1+ (1,-125) [-125|130] "" Vector__XXX
 SG_ FFA1_Year : 40|8@1+ (1,1985) [1985|2240] "" Vector__XXX
 SG_ FFA1_Day : 32|8@1+ (0.25,0) [0|62.5] "" Vector__XXX
 SG_ FFA1_Month : 24|8@1+ (1,0) [0|255] "" Vector__XXX
 SG_ FFA1_Hours : 16|8@1+ (1,0) [0|250] "" Vector__XXX
 SG_ FFA1_Minutes : 8|8@1+ (1,0) [0|250] "" Vector__XXX
 SG_ FFA1_Seconds : 0|8@1+ (0.25,0) [0|62.5] "" Vector__XXX

BO_ 2566857984 ECU_ENGCOND: 8 Vector__XXX
 SG_ FF25_PhaseDiffernceBecrankand : 32|32@1+ (1,0) [0|4294967295] "" Vector__XXX
 SG_ FF25_EngineOperatingCond : 16|16@1+ (1,0) [0|65535] "" Vector__XXX
 SG_ FF25_AirMass : 0|16@1+ (1,0) [0|65535] "" Vector__XXX

BO_ 2633940480 ECU_EEC4: 8 Vector__XXX
 SG_ EngineRatedPower : 0|16@1+ (0.5,0) [0|32127.5] "kW" Vector__XXX
 SG_ EngineRatedSpeed : 16|16@1+ (0.125,0) [0|8031.875] "rpm" Vector__XXX
 SG_ EngineRotationDirection : 32|2@1+ (1,0) [0|3] "" Vector__XXX
 SG_ EngIntkManifoldPressureCtrlMode : 34|2@1+ (1,0) [0|3] "" Vector__XXX
 SG_ CrankAttmptCntOnPrsntStartAttmpt : 40|8@1+ (1,0) [0|250] "" Vector__XXX

BO_ 2566892072 GP_DCAP: 8 Vector__XXX
 SG_ FFAA_TalkButton : 32|2@1+ (1,0) [0|3] "" Vector__XXX
 SG_ FFAA_RequestCallIndex : 48|4@1+ (1,0) [0|15] "" Vector__XXX
 SG_ FFAA_PairingRequest : 46|2@1+ (1,0) [0|3] "" Vector__XXX
 SG_ FFAA_ModeSelect : 40|2@1+ (1,0) [0|3] "" Vector__XXX
 SG_ FFAA_HangUpButton : 44|2@1+ (1,0) [0|3] "" Vector__XXX
 SG_ FFAA_DABSelect : 42|2@1+ (1,0) [0|3] "" Vector__XXX
 SG_ FFAA_BandSelect : 34|2@1+ (1,0) [0|3] "" Vector__XXX
 SG_ FFAA_AudioCallLostPopup : 28|2@1+ (1,0) [0|3] "" Vector__XXX
 SG_ FFAA_AudioVolumeUpSelect : 36|2@1+ (1,0) [0|3] "" Vector__XXX
 SG_ FFAA_AudioVolumeDownSelect : 38|2@1+ (1,0) [0|3] "" Vector__XXX
 SG_ FFAA_AudioUSBSelect : 2|2@1+ (1,0) [0|3] "" Vector__XXX
 SG_ FFAA_AudioTuneUpSelect : 16|2@1+ (1,0) [0|3] "" Vector__XXX
 SG_ FFAA_AudioTuneSelect : 18|2@1+ (1,0) [0|3] "" Vector__XXX
 SG_ FFAA_AudioTuneDownSelect : 30|2@1+ (1,0) [0|3] "" Vector__XXX
 SG_ FFAA_AudioPowerSelect : 24|2@1+ (1,0) [0|3] "" Vector__XXX
 SG_ FFAA_AudioP6Select : 20|2@1+ (1,0) [0|3] "" Vector__XXX
 SG_ FFAA_AudioP5Select : 22|2@1+ (1,0) [0|3] "" Vector__XXX
 SG_ FFAA_AudioP4Select : 8|2@1+ (1,0) [0|3] "" Vector__XXX
 SG_ FFAA_AudioP3Select : 10|2@1+ (1,0) [0|3] "" Vector__XXX
 SG_ FFAA_AudioP2Select : 12|2@1+ (1,0) [0|3] "" Vector__XXX
 SG_ FFAA_AudioP1Select : 14|2@1+ (1,0) [0|3] "" Vector__XXX
 SG_ FFAA_AudioMenuSelect : 26|2@1+ (1,0) [0|3] "" Vector__XXX
 SG_ FFAA_AudioFMSelect : 4|2@1+ (1,0) [0|3] "" Vector__XXX
 SG_ FFAA_AudioAUXSelect : 0|2@1+ (1,0) [0|3] "" Vector__XXX
 SG_ FFAA_AudioAMSelect : 6|2@1+ (1,0) [0|3] "" Vector__XXX

BO_ 2566890280 GP_ATTFC: 8 Vector__XXX
 SG_ FFA3_AttachmentType : 0|2@1+ (1,0) [0|3] "" Vector__XXX
 SG_ FFA3_AttachmentSettingSaveFlag : 6|1@1+ (1,0) [0|1] "" Vector__XXX
 SG_ FFA3_AttachmentSettingFlowValue : 8|16@1+ (1,0) [0|65535] "" Vector__XXX
 SG_ FFA3_AttachmentNumber : 2|4@1+ (1,0) [0|15] "" Vector__XXX

BO_ 2566890024 GP_SWVER: 21 Vector__XXX
 SG_ FFA2_GPOSSWVer_Year : 72|8@1- (1,0) [-128|127] "" Vector__XXX
 SG_ FFA2_GPOSSWVer_Month : 56|8@1- (1,0) [-128|127] "" Vector__XXX
 SG_ FFA2_GPOSSWVer_Day : 64|8@1- (1,0) [-128|127] "" Vector__XXX
 SG_ FFA2_GPOSSWVer : 80|32@1- (1,0) [-2147483648|2147483647] "" Vector__XXX
 SG_ FFA2_GPAPPSWVer_Year : 16|8@1- (1,0) [-128|127] "" Vector__XXX
 SG_ FFA2_GPAPPSWVer_Month : 0|8@1- (1,0) [-128|127] "" Vector__XXX
 SG_ FFA2_GPAPPSWVer_Day : 8|8@1- (1,0) [-128|127] "" Vector__XXX
 SG_ FFA2_GPAPPSWVer : 24|32@1- (1,0) [-2147483648|2147483647] "" Vector__XXX
 SG_ FFA2_AVMSWVer_Year : 128|8@1- (1,0) [-128|127] "" Vector__XXX
 SG_ FFA2_AVMSWVer_Month : 112|8@1- (1,0) [-128|127] "" Vector__XXX
 SG_ FFA2_AVMSWVer_Day : 120|8@1- (1,0) [-128|127] "" Vector__XXX
 SG_ FFA2_AVMSWVer : 136|32@1- (1,0) [-2147483648|2147483647] "" Vector__XXX

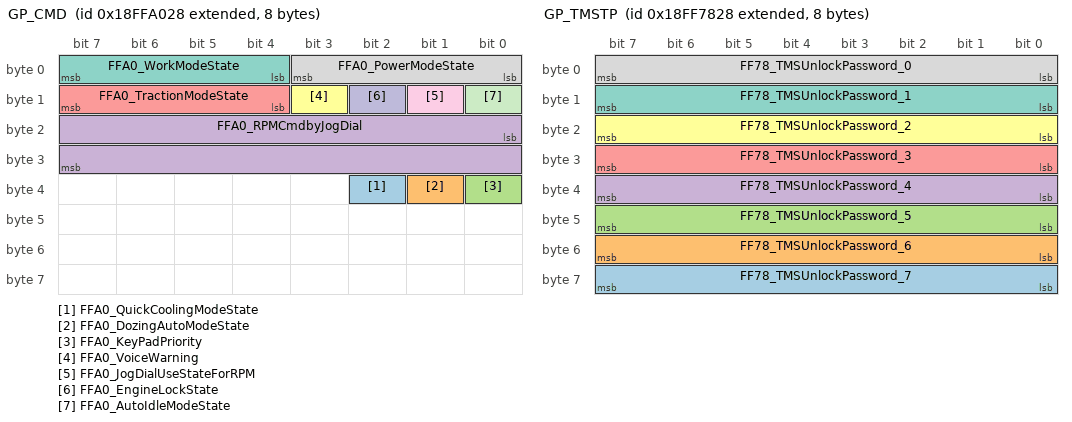
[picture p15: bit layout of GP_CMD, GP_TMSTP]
BO_ 2566889512 GP_CMD: 8 Vector__XXX
 SG_ FFA0_QuickCoolingModeState : 34|1@1+ (1,0) [0|1] "" Vector__XXX
 SG_ FFA0_DozingAutoModeState : 33|1@1+ (1,0) [0|1] "" Vector__XXX
 SG_ FFA0_KeyPadPriority : 32|1@1+ (1,0) [0|1] "" Vector__XXX
 SG_ FFA0_RPMCmdbyJogDial : 16|16@1+ (1,0) [0|65535] "" Vector__XXX
 SG_ FFA0_TractionModeState : 12|4@1+ (1,0) [0|15] "" Vector__XXX
 SG_ FFA0_VoiceWarning : 11|1@1+ (1,0) [0|1] "" Vector__XXX
 SG_ FFA0_WorkModeState : 4|4@1+ (1,0) [0|15] "" Vector__XXX
 SG_ FFA0_PowerModeState : 0|4@1+ (1,0) [0|15] "" Vector__XXX
 SG_ FFA0_JogDialUseStateForRPM : 9|1@1+ (1,0) [0|1] "" Vector__XXX
 SG_ FFA0_EngineLockState : 10|1@1+ (1,0) [0|1] "" Vector__XXX
 SG_ FFA0_AutoIdleModeState : 8|1@1+ (1,0) [0|1] "" Vector__XXX

BO_ 2566881064 GP_TMSPP: 8 Vector__XXX
 SG_ FF7F_TMSStateInfo_2 : 40|8@1+ (1,0) [0|255] "" Vector__XXX
 SG_ FF7F_TMSStateInfo_1 : 32|8@1+ (1,0) [0|255] "" Vector__XXX
 SG_ FF7F_TMSPernamentUnlockPassword : 0|32@1+ (1,0) [0|4294967295] "" Vector__XXX

BO_ 2566879272 GP_TMSTP: 8 Vector__XXX
 SG_ FF78_TMSUnlockPassword_7 : 56|8@1+ (1,0) [0|255] "" Vector__XXX
 SG_ FF78_TMSUnlockPassword_6 : 48|8@1+ (1,0) [0|255] "" Vector__XXX
 SG_ FF78_TMSUnlockPassword_5 : 40|8@1+ (1,0) [0|255] "" Vector__XXX
 SG_ FF78_TMSUnlockPassword_4 : 32|8@1+ (1,0) [0|255] "" Vector__XXX
 SG_ FF78_TMSUnlockPassword_3 : 24|8@1+ (1,0) [0|255] "" Vector__XXX
 SG_ FF78_TMSUnlockPassword_2 : 16|8@1+ (1,0) [0|255] "" Vector__XXX
 SG_ FF78_TMSUnlockPassword_1 : 8|8@1+ (1,0) [0|255] "" Vector__XXX
 SG_ FF78_TMSUnlockPassword_0 : 0|8@1+ (1,0) [0|255] "" Vector__XXX

BO_ 2632722506 TMS_MultiMessageData: 8 Vector__XXX

BO_ 2632656970 TMS_MultiMessage: 8 Vector__XXX

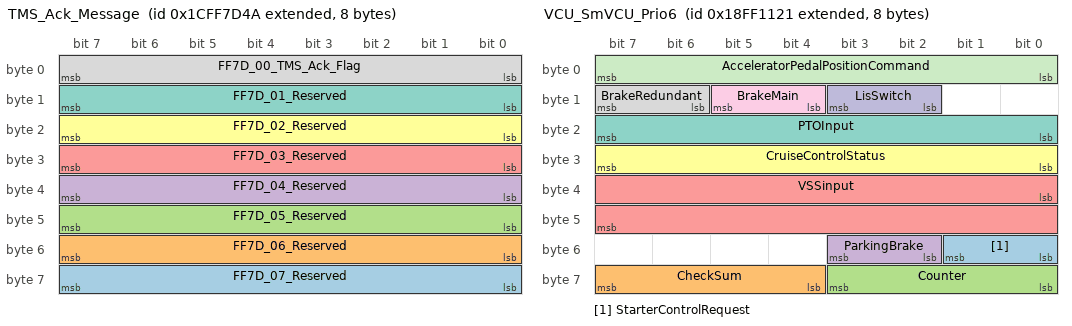
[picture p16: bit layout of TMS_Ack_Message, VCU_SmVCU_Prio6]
BO_ 2633989450 TMS_Ack_Message: 8 Vector__XXX
 SG_ FF7D_07_Reserved : 56|8@1+ (1,0) [0|255] "" Vector__XXX
 SG_ FF7D_06_Reserved : 48|8@1+ (1,0) [0|255] "" Vector__XXX
 SG_ FF7D_05_Reserved : 40|8@1+ (1,0) [0|255] "" Vector__XXX
 SG_ FF7D_04_Reserved : 32|8@1+ (1,0) [0|255] "" Vector__XXX
 SG_ FF7D_03_Reserved : 24|8@1+ (1,0) [0|255] "" Vector__XXX
 SG_ FF7D_02_Reserved : 16|8@1+ (1,0) [0|255] "" Vector__XXX
 SG_ FF7D_01_Reserved : 8|8@1+ (1,0) [0|255] "" Vector__XXX
 SG_ FF7D_00_TMS_Ack_Flag : 0|8@1+ (1,0) [0|255] "" Vector__XXX

BO_ 2566878282 TMS_Network_Info_Satellite: 8 Vector__XXX
 SG_ FF74_Satellite_Type : 0|8@1+ (1,0) [0|255] "" Vector__XXX
 SG_ FF74_Satellite_RSSI : 8|8@1+ (1,0) [0|255] "" Vector__XXX
 SG_ FF74_Satellite_IMEI : 16|8@1+ (1,0) [0|255] "" Vector__XXX

BO_ 2566878026 TMS_Network_Info_Cell: 9 Vector__XXX
 SG_ FF73_Terminal_IP_Address : 32|8@1+ (1,0) [0|255] "" Vector__XXX
 SG_ FF73_SIMStatus : 48|8@1+ (1,0) [0|255] "" Vector__XXX
 SG_ FF73_SIMICCID : 0|8@1+ (1,0) [0|255] "" Vector__XXX
 SG_ FF73_ServerAddress : 24|8@1+ (1,0) [0|255] "" Vector__XXX
 SG_ FF73_GSM_Type : 56|8@1+ (1,0) [0|255] "" Vector__XXX
 SG_ FF73_GSM_RSSI : 64|8@1+ (1,0) [0|255] "" Vector__XXX
 SG_ FF73_CurrentNetwork : 40|8@1+ (1,0) [0|255] "" Vector__XXX
 SG_ FF73_CellIMEI : 8|8@1+ (1,0) [0|255] "" Vector__XXX
 SG_ FF73_APN : 16|8@1+ (1,0) [0|255] "" Vector__XXX

BO_ 2566877770 TMS_GPS_Infomation: 21 Vector__XXX
 SG_ FF72_Altitude : 48|32@1+ (1,0) [0|167777215] "" Vector__XXX
 SG_ FF72_Time : 136|32@1+ (1,0) [0|4294967295] "" Vector__XXX
 SG_ FF72_Speed : 80|8@1+ (1,0) [0|255] "" Vector__XXX
 SG_ FF72_NumberofSatellites : 88|8@1+ (1,0) [0|255] "" Vector__XXX
 SG_ FF72_Longtitude : 24|24@1+ (1,0) [0|16777215] "" Vector__XXX
 SG_ FF72_Local_Time_Offset : 104|32@1+ (1,0) [0|4294967295] "" Vector__XXX
 SG_ FF72_Latitude : 0|24@1+ (1,0) [0|16777215] "" Vector__XXX
 SG_ FF72_GPS_State : 96|8@1+ (1,0) [0|255] "" Vector__XXX

BO_ 2566877514 TMS_Vehicle_Terminal_Info: 8 Vector__XXX
 SG_ FF71_Vehicle_Type : 0|8@1+ (1,0) [0|255] "" Vector__XXX
 SG_ FF71_SerialProtocolType : 8|8@1+ (1,0) [0|255] "" Vector__XXX
 SG_ FF71_BatteryCapacityRemaing : 16|8@1+ (1,0) [0|255] "" Vector__XXX

BO_ 2566877258 TMS_TerminalVersionInfo: 8 Vector__XXX
 SG_ FF70_Terminal_Type_Code : 0|8@1+ (1,0) [0|255] "" Vector__XXX
 SG_ FF70_Terminal_Serial_No : 8|8@1+ (1,0) [0|255] "" Vector__XXX
 SG_ FF70_Software_Version : 32|8@1+ (1,0) [0|255] "" Vector__XXX
 SG_ FF70_Production_Date : 16|8@1+ (1,0) [0|255] "" Vector__XXX
 SG_ FF70_Firmware_Version : 24|8@1+ (1,0) [0|255] "" Vector__XXX
 SG_ FF70_DCF_Version : 40|8@1+ (1,0) [0|255] "" Vector__XXX

BO_ 2566890536 GP_2DMGBC: 8 Vector__XXX
 SG_ FFA4_AlarmState : 0|3@1- (1,0) [0|3] "" Vector__XXX

BO_ 2566852897 VCU_SmVCU_Prio6: 8 Vector__XXX
 SG_ StarterControlRequest : 48|2@1+ (1,0) [0|3] "State" Vector__XXX
 SG_ CheckSum : 60|4@1+ (1,0) [0|15] "State" Vector__XXX
 SG_ Counter : 56|4@1+ (1,0) [0|15] "State" Vector__XXX
 SG_ ParkingBrake : 50|2@1+ (1,0) [0|3] "State" Vector__XXX
 SG_ VSSinput : 32|16@1+ (1,0) [0|65535] "State" Vector__XXX
 SG_ CruiseControlStatus : 24|8@1+ (1,0) [0|255] "State" Vector__XXX
 SG_ PTOInput : 16|8@1+ (1,0) [0|255] "State" Vector__XXX
 SG_ BrakeRedundant : 14|2@1+ (1,0) [0|3] "State" Vector__XXX
 SG_ BrakeMain : 12|2@1+ (1,0) [0|3] "State" Vector__XXX
 SG_ LisSwitch : 10|2@1+ (1,0) [0|3] "State" Vector__XXX
 SG_ AcceleratorPedalPositionCommand : 0|8@1+ (0.4,0) [0|102] "%" Vector__XXX

BO_ 2566748928 ECU_AT1S1: 8 Vector__XXX
 SG_ Aftrtrtmnt1DslPFSootLoadPercent : 0|8@1+ (1,0) [0|250] "%" Vector__XXX
 SG_ Aftrtrtmnt1DslPFAshLoadPercent : 8|8@1+ (1,0) [0|250] "%" Vector__XXX
 SG_ Aft1DslPFTmeSncLastActvRegen : 16|32@1+ (1,0) [0|4211081215] "s" Vector__XXX
 SG_ Aft1DslPFSootLoadRegenTrshld : 48|16@1+ (0.0025,0) [0|160.6375] "%" Vector__XXX

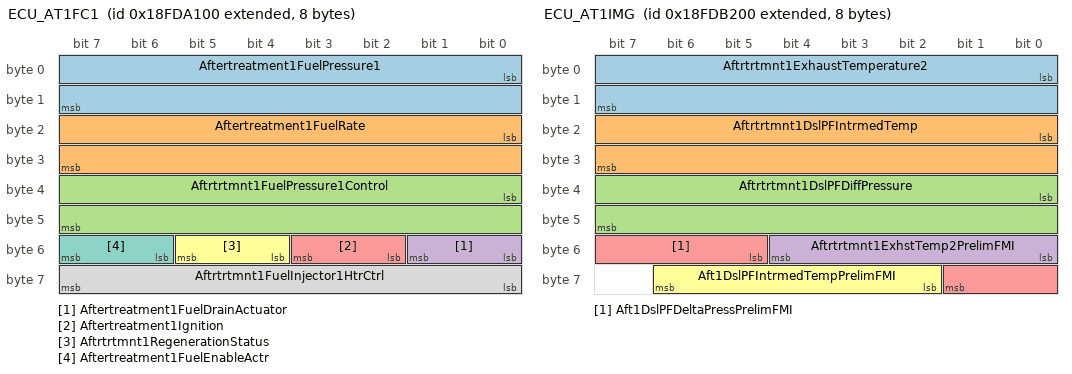
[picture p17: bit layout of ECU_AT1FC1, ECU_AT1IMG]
BO_ 2566758656 ECU_AT1FC1: 8 Vector__XXX
 SG_ Aftertreatment1FuelPressure1 : 0|16@1+ (0.1,0) [0|6425.5] "kPa" Vector__XXX
 SG_ Aftertreatment1FuelRate : 16|16@1+ (0.05,0) [0|3212.75] "l/h" Vector__XXX
 SG_ Aftrtrtmnt1FuelPressure1Control : 32|16@1+ (0.0025,0) [0|160.6375] "%" Vector__XXX
 SG_ Aftertreatment1FuelDrainActuator : 48|2@1+ (1,0) [0|3] "" Vector__XXX
 SG_ Aftertreatment1Ignition : 50|2@1+ (1,0) [0|3] "" Vector__XXX
 SG_ Aftrtrtmnt1RegenerationStatus : 52|2@1+ (1,0) [0|3] "" Vector__XXX
 SG_ Aftertreatment1FuelEnableActr : 54|2@1+ (1,0) [0|3] "" Vector__XXX
 SG_ Aftrtrtmnt1FuelInjector1HtrCtrl : 56|8@1+ (0.4,0) [0|100] "%" Vector__XXX

BO_ 2566763008 ECU_AT1IMG: 8 Vector__XXX
 SG_ Aftrtrtmnt1ExhaustTemperature2 : 0|16@1+ (0.03125,-273) [-273|1734.96875] "deg C" Vector__XXX
 SG_ Aftrtrtmnt1DslPFIntrmedTemp : 16|16@1+ (0.03125,-273) [-273|1734.96875] "deg C" Vector__XXX
 SG_ Aftrtrtmnt1DslPFDiffPressure : 32|16@1+ (0.1,0) [0|6425.5] "kPa" Vector__XXX
 SG_ Aftrtrtmnt1ExhstTemp2PrelimFMI : 48|5@1+ (1,0) [0|31] "" Vector__XXX
 SG_ Aft1DslPFDeltaPressPrelimFMI : 53|5@1+ (1,0) [0|31] "" Vector__XXX
 SG_ Aft1DslPFIntrmedTempPrelimFMI : 58|5@1+ (1,0) [0|31] "" Vector__XXX

BO_ 2566763264 ECU_AT1OG2: 8 Vector__XXX
 SG_ Aftrtrtmnt1ExhaustTemperature3 : 0|16@1+ (0.03125,-273) [-273|1734.96875] "deg C" Vector__XXX
 SG_ Aftrtrtmnt1DslPFOtltTemperature : 16|16@1+ (0.03125,-273) [-273|1734.96875] "deg C" Vector__XXX
 SG_ Aftrtrtmnt1ExhstTemp3PrelimFMI : 32|5@1+ (1,0) [0|31] "" Vector__XXX
 SG_ Aft1DslPFOtltExhstTempPrelimFMI : 40|5@1+ (1,0) [0|31] "" Vector__XXX

BO_ 2566763520 ECU_AT1IG2: 8 Vector__XXX
 SG_ Aftrtrtmnt1ExhaustTemperature1 : 0|16@1+ (0.03125,-273) [-273|1734.96875] "deg C" Vector__XXX
 SG_ Aftrtrtmnt1DslPFIntkTemperature : 16|16@1+ (0.03125,-273) [-273|1734.96875] "deg C" Vector__XXX
 SG_ Aftrtrtmnt1ExhstTemp1PrelimFMI : 32|5@1+ (1,0) [0|31] "" Vector__XXX
 SG_ Aft1DslPFIntkTempPrelimFMI : 40|5@1+ (1,0) [0|31] "" Vector__XXX

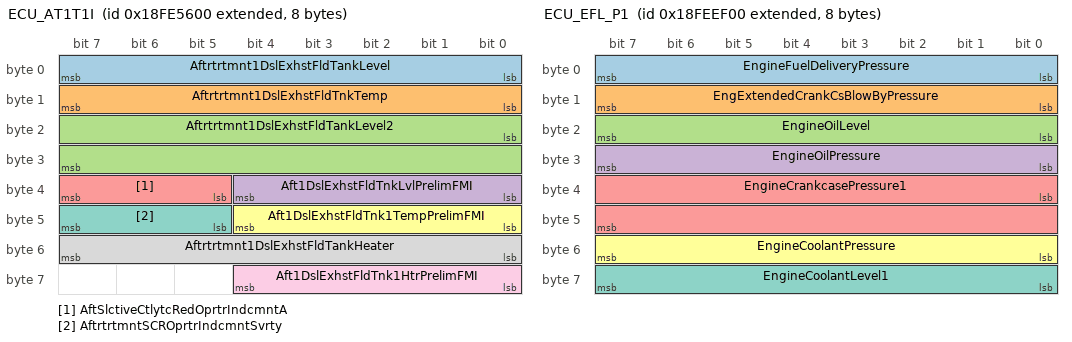
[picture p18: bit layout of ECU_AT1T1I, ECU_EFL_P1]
BO_ 2566804992 ECU_AT1T1I: 8 Vector__XXX
 SG_ Aftrtrtmnt1DslExhstFldTankLevel : 0|8@1+ (0.4,0) [0|100] "%" Vector__XXX
 SG_ Aftrtrtmnt1DslExhstFldTnkTemp : 8|8@1+ (1,-40) [-40|210] "deg C" Vector__XXX
 SG_ Aftrtrtmnt1DslExhstFldTankLevel2 : 16|16@1+ (0.1,0) [0|6425.5] "mm" Vector__XXX
 SG_ Aft1DslExhstFldTnkLvlPrelimFMI : 32|5@1+ (1,0) [0|31] "" Vector__XXX
 SG_ AftSlctiveCtlytcRedOprtrIndcmntA : 37|3@1+ (1,0) [0|7] "" Vector__XXX
 SG_ Aft1DslExhstFldTnk1TempPrelimFMI : 40|5@1+ (1,0) [0|31] "" Vector__XXX
 SG_ AftrtrtmntSCROprtrIndcmntSvrty : 45|3@1+ (1,0) [0|7] "" Vector__XXX
 SG_ Aftrtrtmnt1DslExhstFldTankHeater : 48|8@1+ (0.4,0) [0|100] "%" Vector__XXX
 SG_ Aft1DslExhstFldTnk1HtrPrelimFMI : 56|5@1+ (1,0) [0|31] "" Vector__XXX

BO_ 2566841344 ECU_SHUTDN: 8 Vector__XXX
 SG_ EngIdleShutdownHasShutdownEngine : 0|2@1+ (1,0) [0|3] "" Vector__XXX
 SG_ EngineIdleShutdownDrvrAlertMode : 2|2@1+ (1,0) [0|3] "" Vector__XXX
 SG_ EngineIdleShutdownTimerOverride : 4|2@1+ (1,0) [0|3] "" Vector__XXX
 SG_ EngineIdleShutdownTimerState : 6|2@1+ (1,0) [0|3] "" Vector__XXX
 SG_ EngineIdleShutdownTimerFunction : 14|2@1+ (1,0) [0|3] "" Vector__XXX
 SG_ ACHighPressureFanSwitch : 16|2@1+ (1,0) [0|3] "" Vector__XXX
 SG_ RefrigerantLowPressureSwitch : 18|2@1+ (1,0) [0|3] "" Vector__XXX
 SG_ RefrigerantHighPressureSwitch : 20|2@1+ (1,0) [0|3] "" Vector__XXX
 SG_ EngineWaitToStartLamp : 24|2@1+ (1,0) [0|3] "" Vector__XXX
 SG_ EngPrtctnSystemHasShutdownEng : 32|2@1+ (1,0) [0|3] "" Vector__XXX
 SG_ EngPrtctnSystemApproachingShtdwn : 34|2@1+ (1,0) [0|3] "" Vector__XXX
 SG_ EngProtectionSystemTimerOverride : 36|2@1+ (1,0) [0|3] "" Vector__XXX
 SG_ EngineProtectionSystemTimerState : 38|2@1+ (1,0) [0|3] "" Vector__XXX
 SG_ EngineProtectionSystemConf : 46|2@1+ (1,0) [0|3] "" Vector__XXX
 SG_ EngineAlarmAcknowledge : 48|2@1+ (1,0) [0|3] "" Vector__XXX
 SG_ EngineAlarmOutputCommandStatus : 50|2@1+ (1,0) [0|3] "" Vector__XXX
 SG_ EngineAirShutoffCommandStatus : 52|2@1+ (1,0) [0|3] "" Vector__XXX
 SG_ EngineOverspeedTest : 54|2@1+ (1,0) [0|3] "" Vector__XXX
 SG_ EngineAirShutoffStatus : 56|2@1+ (1,0) [0|3] "" Vector__XXX
 SG_ PTOShutdownHasShutdownEngine : 58|2@1+ (1,0) [0|3] "" Vector__XXX
 SG_ CoolntLvlEngPrtctnShutdownStatus : 60|2@1+ (1,0) [0|3] "" Vector__XXX

BO_ 2566842624 ECU_LFC: 8 Vector__XXX
 SG_ EngineTripFuel : 0|32@1+ (0.5,0) [0|2105540607.5] "l" Vector__XXX
 SG_ EngineTotalFuelUsed : 32|32@1+ (0.5,0) [0|2105540607.5] "l" Vector__XXX

BO_ 2566843904 ECU_ET1: 8 Vector__XXX
 SG_ EngineCoolantTemperature : 0|8@1+ (1,-40) [-40|210] "deg C" Vector__XXX
 SG_ EngineFuelTemperature1 : 8|8@1+ (1,-40) [-40|210] "deg C" Vector__XXX
 SG_ EngineOilTemperature1 : 16|16@1+ (0.03125,-273) [-273|1734.96875] "deg C" Vector__XXX
 SG_ EngineTurbochargerOilTemperature : 32|16@1+ (0.03125,-273) [-273|1734.96875] "deg C" Vector__XXX
 SG_ EngineIntercoolerTemperature : 48|8@1+ (1,-40) [-40|210] "deg C" Vector__XXX
 SG_ EngChargeAirCoolThrmsttOpening : 56|8@1+ (0.4,0) [0|100] "%" Vector__XXX

BO_ 2566844160 ECU_EFL_P1: 8 Vector__XXX
 SG_ EngineFuelDeliveryPressure : 0|8@1+ (4,0) [0|1000] "kPa" Vector__XXX
 SG_ EngExtendedCrankCsBlowByPressure : 8|8@1+ (0.05,0) [0|12.5] "kPa" Vector__XXX
 SG_ EngineOilLevel : 16|8@1+ (0.4,0) [0|100] "%" Vector__XXX
 SG_ EngineOilPressure : 24|8@1+ (4,0) [0|1000] "kPa" Vector__XXX
 SG_ EngineCrankcasePressure1 : 32|16@1+ (0.0078125,-250) [-250|261.9921875] "kPa" Vector__XXX
 SG_ EngineCoolantPressure : 48|8@1+ (2,0) [0|500] "kPa" Vector__XXX
 SG_ EngineCoolantLevel1 : 56|8@1+ (0.4,0) [0|100] "%" Vector__XXX

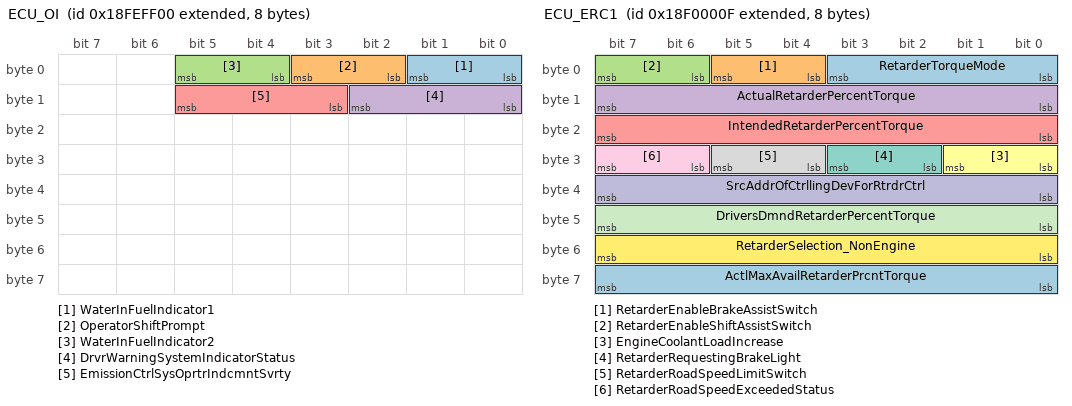
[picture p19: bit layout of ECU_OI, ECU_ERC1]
BO_ 2566848256 ECU_OI: 8 Vector__XXX
 SG_ WaterInFuelIndicator1 : 0|2@1+ (1,0) [0|3] "" Vector__XXX
 SG_ OperatorShiftPrompt : 2|2@1+ (1,0) [0|3] "" Vector__XXX
 SG_ WaterInFuelIndicator2 : 4|2@1+ (1,0) [0|3] "" Vector__XXX
 SG_ DrvrWarningSystemIndicatorStatus : 8|3@1+ (1,0) [0|7] "" Vector__XXX
 SG_ EmissionCtrlSysOprtrIndcmntSvrty : 11|3@1+ (1,0) [0|7] "" Vector__XXX

BO_ 2565865487 ECU_ERC1: 8 Vector__XXX
 SG_ RetarderTorqueMode : 0|4@1+ (1,0) [0|15] "" Vector__XXX
 SG_ RetarderEnableBrakeAssistSwitch : 4|2@1+ (1,0) [0|3] "" Vector__XXX
 SG_ RetarderEnableShiftAssistSwitch : 6|2@1+ (1,0) [0|3] "" Vector__XXX
 SG_ ActualRetarderPercentTorque : 8|8@1+ (1,-125) [-125|125] "%" Vector__XXX
 SG_ IntendedRetarderPercentTorque : 16|8@1+ (1,-125) [-125|125] "%" Vector__XXX
 SG_ EngineCoolantLoadIncrease : 24|2@1+ (1,0) [0|3] "" Vector__XXX
 SG_ RetarderRequestingBrakeLight : 26|2@1+ (1,0) [0|3] "" Vector__XXX
 SG_ RetarderRoadSpeedLimitSwitch : 28|2@1+ (1,0) [0|3] "" Vector__XXX
 SG_ RetarderRoadSpeedExceededStatus : 30|2@1+ (1,0) [0|3] "" Vector__XXX
 SG_ SrcAddrOfCtrllingDevForRtrdrCtrl : 32|8@1+ (1,0) [0|255] "" Vector__XXX
 SG_ DriversDmndRetarderPercentTorque : 40|8@1+ (1,-125) [-125|125] "%" Vector__XXX
 SG_ RetarderSelection_NonEngine : 48|8@1+ (0.4,0) [0|100] "%" Vector__XXX
 SG_ ActlMaxAvailRetarderPrcntTorque : 56|8@1+ (1,-125) [-125|125] "%" Vector__XXX

BO_ 2566844928 ECU_LFE1: 8 Vector__XXX
 SG_ EngineFuelRate : 0|16@1+ (0.05,0) [0|3212.75] "l/h" Vector__XXX
 SG_ EngineInstantaneousFuelEconomy : 16|16@1+ (0.001953125,0) [0|125.498046875] "km/l" Vector__XXX
 SG_ EngineAverageFuelEconomy : 32|16@1+ (0.001953125,0) [0|125.498046875] "km/l" Vector__XXX
 SG_ EngineThrottleValve1Position1 : 48|8@1+ (0.4,0) [0|100] "%" Vector__XXX
 SG_ EngineThrottleValve2Position : 56|8@1+ (0.4,0) [0|100] "%" Vector__XXX

BO_ 2566876320 AUDIO_DCAI: 8 Vector__XXX
 SG_ FF6C_DABDLSMessageState : 21|1@1+ (1,0) [0|1] "" Vector__XXX
 SG_ FF6C_BluetoothStateSignal : 24|4@1+ (1,0) [0|15] "" Vector__XXX
 SG_ FF6C_AudioServiceNameState : 17|1@1+ (1,0) [0|1] "" Vector__XXX
 SG_ FF6C_AudioServiceFollowState : 32|1@1+ (1,0) [0|1] "" Vector__XXX
 SG_ FF6C_AudioFMLinkingState : 33|1@1+ (1,0) [0|1] "" Vector__XXX
 SG_ FF6C_AudioEnsembleName : 18|1@1+ (1,0) [0|1] "" Vector__XXX
 SG_ FF6C_AudioDigitalSignalUn : 19|1@1+ (1,0) [0|1] "" Vector__XXX
 SG_ FF6C_AudioDABLinkingState : 16|1@1+ (1,0) [0|1] "" Vector__XXX
 SG_ FF6C_AudioBluetoothState : 20|1@1+ (1,0) [0|1] "" Vector__XXX
 SG_ FF6C_SearchMode : 9|1@1+ (1,0) [0|1] "" Vector__XXX
 SG_ FF6C_AudioWMAState : 12|1@1+ (1,0) [0|1] "" Vector__XXX
 SG_ FF6C_AudioVolumeState : 0|6@1+ (1,0) [0|63] "" Vector__XXX
 SG_ FF6C_AudioUSBState : 15|1@1+ (1,0) [0|1] "" Vector__XXX
 SG_ FF6C_AudioSTState : 11|1@1+ (1,0) [0|1] "" Vector__XXX
 SG_ FF6C_AudioRPTState : 8|1@1+ (1,0) [0|1] "" Vector__XXX
 SG_ FF6C_AudioRDMState : 23|1@1+ (1,0) [0|1] "" Vector__XXX
 SG_ FF6C_AudioPowerState : 6|1@1+ (1,0) [0|1] "" Vector__XXX
 SG_ FF6C_AudioMuteState : 7|1@1+ (1,0) [0|1] "" Vector__XXX
 SG_ FF6C_AudioMP3State : 13|1@1+ (1,0) [0|1] "" Vector__XXX
 SG_ FF6C_AudioLOUDState : 22|1@1+ (1,0) [0|1] "" Vector__XXX
 SG_ FF6C_AudioFLDState : 10|1@1+ (1,0) [0|1] "" Vector__XXX
 SG_ FF6C_AudioDisplaySmallIndex : 28|4@1+ (1,0) [0|15] "" Vector__XXX
 SG_ FF6C_AudioDisplayLargeSubData : 40|23@1+ (1,0) [0|8388607] "" Vector__XXX
 SG_ FF6C_AudioDisplayLargeIndex : 34|6@1+ (1,0) [0|63] "" Vector__XXX
 SG_ FF6C_AudioAUXState : 14|1@1+ (1,0) [0|1] "" Vector__XXX

CM_ BO_ 2565869457 "Aftertreatment 1 Outlet Gas 1";
CM_ BO_ 2565869201 "Aftertreatment 1 Intake Gas 1";
CM_ BO_ 2566766848 "Engine Fluid Level/Pressure 1";
CM_ BO_ 2566805137 "Aftertreatment 1 Diesel Exhaust Fluid Tank 1 Information";
CM_ BO_ 2566757265 "Aftertreatment 1 Diesel Exhaust Fluid Information";
CM_ BO_ 2566758801 "Aftertreatment 1 Fuel Control 1";
CM_ BO_ 2566763409 "Aftertreatment 1 Outlet Gas 2";
CM_ BO_ 2566763665 "Aftertreatment 1 Intake Gas 2";
CM_ BO_ 2348810273 "Torque/Speed Control 1";
CM_ SG_ 2348810273 TSC1MessageCounter "Parameter provided to the engine or retarder in the torque/speed control message for controlling or limiting the output torque.";
CM_ SG_ 2348810273 TSC1MessageChecksum "Parameter provided to the engine or retarder in the torque/speed control message for controlling or limiting the output torque.";
CM_ SG_ 2348810273 TSC1EngineRequestedSpeed "Parameter provided to the engine from external sources in the torque/speed control message.";
CM_ SG_ 2348810273 TSC1EngineReqTorqueTorquelimit "Parameter provided to the engine or retarder in the torque/speed control message for controlling or limiting the output torque.";
CM_ BO_ 2565472296 "Request";
CM_ BO_ 2364539648 "Electronic Engine Controller 2";
CM_ BO_ 2364539904 "Electronic Engine Controller 1";
CM_ BO_ 2565866755 "Electronic Transmission Controller 2";
CM_ BO_ 2566801923 "Electronic Transmission Controller 7";
CM_ BO_ 2566866179 "ZF Electronic Transmission Controller 9";
CM_ SG_ 2566866179 FF45_OverspeedWarnTransOutput "Trm_Out_Overspeed_State";
CM_ SG_ 2566866179 FF45_OverspeedWarningTransInput "Trm_In_Overspeed_State";
CM_ SG_ 2566866179 FF45_TrmSumpHeatState "0: mormal1: overtemperature2: critical overtemperature3: not available";
CM_ SG_ 2566866179 FF45_TrmTemperatureLimitMode "0: no limits 1: cold start mode 1 (limited dynamics or drive range)2: cold start mode 2 (no gear, heat up necessary) ";
CM_ BO_ 2566864899 "ZF Hydro Calibration";
CM_ SG_ 2566864899 FF40_BreakCondition "0: all cond. fulfilled1: aborted by user2: eng. speed too high3: eng. speed too low4: oil sump temp. too high5: oil sump temp. too low6: no neutral request7: trm output speed not zero8: operation mode not NORMAL9: park brake not applied";
CM_ SG_ 2566864899 FF40_GeneralStatus "0: hydro calibration running1: hydro calibration succesfully finished 2: hydro calibration not succesfully finished 3: hydro calibration not active";
CM_ BO_ 2566870787 "Hydrostat control";
CM_ BO_ 2565867011 "Electronic Axle Controller 1";
CM_ SG_ 2565867011 F006_DiffLockStateCentral "State used which indicates the condition of the central differential lock.";
CM_ BO_ 2566847009 "Brakes";
CM_ SG_ 2566847009 BParkingBrakeActuator "Signal which indicates the current state of the actuator(s) that control the parking brake (see also SPN 70).";
CM_ BO_ 2566846467 "Transmission Fluids 1";
CM_ SG_ 2566846467 TRF1TrmOilTemperature "Temperature of the transmission lubricant.";
CM_ BO_ 2566755587 "Transmission Fluids 2";
CM_ SG_ 2566755587 TRF2TrmOilFilterRestrictSwitch "This switch indicates whether the transmission oil filter is clogged.";
CM_ BO_ 2365542945 "Transmission Control 1";
CM_ SG_ 2365542945 ZFTC1TrmMode6 "Indicates whether transmission mode 5 is enabled.";
CM_ SG_ 2365542945 ZFTC1DisengageDifflockRequest "Command signal used to disengage the various differential locks, e.";
CM_ SG_ 2365542945 ZFTC1TrmMode7 "Indicates whether transmission mode 7 is enabled.";
CM_ SG_ 2365542945 ZFTC1TrmMode5 "Indicates whether transmission mode 5 is enabled.";
CM_ SG_ 2365542945 ZFTC1TrmMode4 "Indicates whether transmission mode 4 is enabled.";
CM_ SG_ 2365542945 ZFTC1TrmMode3 "Indicates whether transmission mode 3 is enabled.";
CM_ SG_ 2365542945 ZFTC1TrmMode2 "Indicates whether transmission mode 2 is enabled.";
CM_ SG_ 2365542945 ZFTC1TrmMode1 "Indicates whether transmission mode 1 is enabled.";
CM_ SG_ 2365542945 ZFTC1TrmRequestedGear "Gear requested by the operator, ABS, or engine.";
CM_ SG_ 2365542945 ZFTC1DisengageDrivelineRequest "Command signal used to simply disengage the driveline, e.";
CM_ BO_ 2566841088 "Engine Configuration";
CM_ SG_ 2566841088 EC1Engine_Reference_Torque "This parameter is the 100% reference value for all defined indicated engine torque parameters.";
CM_ BO_ 2566840064 "Electronic Engine Controller 3";
CM_ SG_ 2566840064 EEC3EnginesDesiredOpSpeed "Parameter provided to the engine from external sources in the torque/speed control message.";
CM_ BO_ 2365538819 "Electronic Transmission Controller 1";
CM_ SG_ 2365538819 ETC1MessageCheckSum_CRC "The source address of the SAE J1939 device currently controlling the transmission.";
CM_ SG_ 2365538819 ETC1TrmInputShaftSpeed "Rotational velocity of the primary shaft transferring power into the transmission.";
CM_ SG_ 2365538819 ETC1TrmOutputShaftSpeed "Calculated speed of the transmission output shaft.";
CM_ SG_ 2365538819 ETC1TrmShiftInProcess "Indicates that the transmission is in process of shifting from the current gear to the selected gear.";
CM_ BO_ 2348810243 "Torque/Speed Control 1";
CM_ SG_ 2348810243 TSC1MessageCounter "Parameter provided to the engine or retarder in the torque/speed control message for controlling or limiting the output torque.";
CM_ SG_ 2348810243 TSC1MessageChecksum "Parameter provided to the engine or retarder in the torque/speed control message for controlling or limiting the output torque.";
CM_ SG_ 2348810243 TSC1EngineRequestedSpeed "Parameter provided to the engine from external sources in the torque/speed control message.";
CM_ SG_ 2348810243 TSC1EngineReqTorqueTorquelimit "Parameter provided to the engine or retarder in the torque/speed control message for controlling or limiting the output torque.";
CM_ BO_ 2365542689 "Hydrostat control";
CM_ SG_ 2365542689 ZFTC8_RTEM "Requested Tractive Power Upper Limit00: LOW01: MEDIUM10: HIGH11: NOT REQUESTED";
CM_ SG_ 2365542689 ZFTC8_RMDC "Requested Maximum Acceleration Class";
CM_ SG_ 2365542689 ZFTC8_RMRC "Requested Maximum Acceleration Class";
CM_ SG_ 2365542689 ZFTC8_RMAC "Requested Maximum Acceleration Class";
CM_ SG_ 2365542689 ZFTC8_RTPULC "Requested Tractive Power Upper Limit00: LOW01: MEDIUM10: HIGH11: NOT REQUESTED";
CM_ SG_ 2566767875 ECUType "Software ID";
CM_ SG_ 2566767875 ECUSerialNumber "Software ID";
CM_ SG_ 2566767875 ECULocation "Software ID";
CM_ SG_ 2566767875 ECU_Manufacturer "Software ID";
CM_ SG_ 2566767875 ECU_PartNumber "Software ID";
CM_ BO_ 2566838787 "Software Identification";
CM_ SG_ 2566838787 FEDA_OptionalField_2 "Software ID";
CM_ SG_ 2566838787 FEDA_OptionalField_1 "Software ID";
CM_ SG_ 2566838787 FEDA_TransmissionPartNumber "Software ID";
CM_ SG_ 2566838787 FEDA_SWVersion "Software ID";
CM_ SG_ 2566838787 FEDA_SWPartNumber "Software ID";
CM_ SG_ 2566838787 FEDA_NumberOfSWIdentification "Number of software identification designators represented in the software identification parameter group.";
CM_ BO_ 2565603072 "Transport Protocol - Data Transfer";
CM_ BO_ 2565668608 "Transport Protocol - Connection Management";
CM_ SG_ 2565668608 TotalNumberOfPacketsEoMA "Total number of packets for BAM message.Total number of packets received for RTS/CTS message.Total number of packets for RTS/CTS message.";
CM_ SG_ 2565668608 TotalMessageSizeEoMA "Total message size (in bytes) for BAM message.Total message size (in bytes) for RTS/CTS message.Total message size (in bytes) for RTS/CTS message.";
CM_ SG_ 2565668608 TotalMessageSizeBAM "Total message size (in bytes) for BAM message.Total message size (in bytes) for RTS/CTS message.Total message size (in bytes) for RTS/CTS message.";
CM_ SG_ 2565668608 TotalNumberOfPacketsBAM "Total number of packets for BAM message.Total number of packets received for RTS/CTS message.Total number of packets for RTS/CTS message.";
CM_ SG_ 2565668608 ConnectionAbortReason "Reason for connection abort message.";
CM_ SG_ 2565668608 NextPacketNumberToBeSent "Next Packet Number to be sent (TP.CM_CTS)";
CM_ SG_ 2565668608 NumberOfPacketsThatCanBeSent "Number of Packets that can be sent (TP.CM_CTS)";
CM_ SG_ 2565668608 MaximumNumberOfPackets "Maximum number of packets for RTS/CTS message.";
CM_ SG_ 2565668608 TotalNumberOfPackets "Total number of packets for BAM message.Total number of packets received for RTS/CTS message.Total number of packets for RTS/CTS message.";
CM_ SG_ 2565668608 TotalMessageSize "Total message size (in bytes) for BAM message.Total message size (in bytes) for RTS/CTS message.Total message size (in bytes) for RTS/CTS message.";
CM_ BO_ 2565482529 "Request";
CM_ SG_ 2565482529 ParameterGroupNumber "PGN which is requested by Request2 message";
CM_ BO_ 2565537536 "Request";
CM_ BO_ 2565472289 "Request";
CM_ BO_ 2565480744 "Request";
CM_ BO_ 2566835456 "Freeze Frame Parameters";
CM_ BO_ 2566835712 "Diagnostic Readiness 1";
CM_ BO_ 2566835968 "Pending DTCs";
CM_ BO_ 2633940480 "Electronic Engine Controller 4";
CM_ BO_ 2566748928 "Aftertreatment 1 Service 1";
CM_ BO_ 2566758656 "Aftertreatment 1 Fuel Control 1";
CM_ BO_ 2566763008 "Aftertreatment 1 Intermediate Gas";
CM_ BO_ 2566763264 "Aftertreatment 1 Outlet Gas 2";
CM_ BO_ 2566763520 "Aftertreatment 1 Intake Gas 2";
CM_ BO_ 2566804992 "Aftertreatment 1 Diesel Exhaust Fluid Tank 1 Information";
CM_ BO_ 2566841344 "Shutdown";
CM_ BO_ 2566842624 "Fuel Consumption (Liquid)";
CM_ BO_ 2566843904 "Engine Temperature 1";
CM_ BO_ 2566844160 "Engine Fluid Level/Pressure 1";
CM_ BO_ 2566848256 "Operator indicators";
CM_ BO_ 2565865487 "Electronic Retarder Controller 1";
CM_ BO_ 2566844928 "Fuel Economy (Liquid)";
BA_DEF_ BO_  "VFrameFormat" ENUM  "StandardCAN","ExtendedCAN","reserved","J1939PG";
BA_DEF_ BO_  "GenMsgCycleTime" INT 0 65535;
BA_DEF_ SG_  "GenSigStartValue" FLOAT -3.4E+038 3.4E+038;
BA_DEF_ SG_  "SPN" INT -3.4E+038 3.4E+038;
BA_DEF_ SG_  "SigType" ENUM  "Default","Range","RangeSigned","ASCII","Discrete","Control","ReferencePGN","DTC","StringDelimiter","StringLength","StringLengthControl","MessageCounter","MessageChecksum";
BA_DEF_DEF_  "VFrameFormat" "J1939PG";
BA_DEF_DEF_  "GenMsgCycleTime" 0;
BA_DEF_DEF_  "GenSigStartValue" 0;
BA_DEF_DEF_  "SPN" 0;
BA_DEF_DEF_  "SigType" "Default";
BA_ "GenMsgCycleTime" BO_ 2565869457 50;
BA_ "GenMsgCycleTime" BO_ 2565869201 50;
BA_ "GenMsgCycleTime" BO_ 2566766848 500;
BA_ "GenMsgCycleTime" BO_ 2566805137 1000;
BA_ "GenMsgCycleTime" BO_ 2566757265 1000;
BA_ "GenMsgCycleTime" BO_ 2566758801 500;
BA_ "GenMsgCycleTime" BO_ 2566763409 500;
BA_ "GenMsgCycleTime" BO_ 2566763665 500;
BA_ "GenMsgCycleTime" BO_ 2348810273 10;
BA_ "GenMsgCycleTime" BO_ 2365543464 100;
BA_ "GenMsgCycleTime" BO_ 2566869765 10;
BA_ "GenMsgCycleTime" BO_ 2365542696 100;
BA_ "GenMsgCycleTime" BO_ 2365543201 100;
BA_ "GenMsgCycleTime" BO_ 2566865953 100;
BA_ "GenMsgCycleTime" BO_ 2566865441 100;
BA_ "GenMsgCycleTime" BO_ 2566865185 100;
BA_ "GenMsgCycleTime" BO_ 2566865697 100;
BA_ "GenMsgCycleTime" BO_ 2566864929 100;
BA_ "GenMsgCycleTime" BO_ 2364539648 50;
BA_ "GenMsgCycleTime" BO_ 2364539904 10;
BA_ "GenMsgCycleTime" BO_ 2565866755 100;
BA_ "GenMsgCycleTime" BO_ 2566801923 100;
BA_ "GenMsgCycleTime" BO_ 2566870275 100;
BA_ "GenMsgCycleTime" BO_ 2566866179 100;
BA_ "GenMsgCycleTime" BO_ 2566864899 100;
BA_ "GenMsgCycleTime" BO_ 2566870787 100;
BA_ "GenMsgCycleTime" BO_ 2565867011 500;
BA_ "GenMsgCycleTime" BO_ 2566847009 1000;
BA_ "GenMsgCycleTime" BO_ 2566846467 1000;
BA_ "GenMsgCycleTime" BO_ 2566755587 1000;
BA_ "GenMsgCycleTime" BO_ 2365542945 10;
BA_ "GenMsgCycleTime" BO_ 2566841088 5000;
BA_ "GenMsgCycleTime" BO_ 2566840064 250;
BA_ "GenMsgCycleTime" BO_ 2365538819 10;
BA_ "GenMsgCycleTime" BO_ 2348810243 10;
BA_ "GenMsgCycleTime" BO_ 2365542689 100;
BA_ "GenMsgCycleTime" BO_ 2365460608 100;
BA_ "GenMsgCycleTime" BO_ 2566889768 1000;
BA_ "GenMsgCycleTime" BO_ 2566889512 100;
BA_ "GenMsgCycleTime" BO_ 2566758656 500;
BA_ "GenMsgCycleTime" BO_ 2566763008 500;
BA_ "GenMsgCycleTime" BO_ 2566763264 500;
BA_ "GenMsgCycleTime" BO_ 2566763520 500;
BA_ "GenMsgCycleTime" BO_ 2566804992 1000;
BA_ "GenMsgCycleTime" BO_ 2566841344 1000;
BA_ "GenMsgCycleTime" BO_ 2566843904 1000;
BA_ "GenMsgCycleTime" BO_ 2566844160 500;
BA_ "GenMsgCycleTime" BO_ 2566848256 10000;
BA_ "GenMsgCycleTime" BO_ 2565865487 100;
BA_ "GenMsgCycleTime" BO_ 2566844928 100;
BA_ "GenSigStartValue" SG_ 2633927680 FE8C_AuxTemp2 40;
BA_ "GenSigStartValue" SG_ 2633927680 FE8C_AuxTemp1 40;
BA_ "GenSigStartValue" SG_ 2565869457 Aftertreatment1OutletNOx 4000;
BA_ "SPN" SG_ 2565869457 Aftertreatment1OutletNOx 3226;
BA_ "GenSigStartValue" SG_ 2565869457 Aftertreatment1OutletPercentO2 23346.3035019455;
BA_ "SPN" SG_ 2565869457 Aftertreatment1OutletPercentO2 3227;
BA_ "SPN" SG_ 2565869457 Aftrtrtmnt1OtltGasSensorPwrInRng 3228;
BA_ "SPN" SG_ 2565869457 Aftrtrtmnt1OtltGasSnsrAtTemp 3229;
BA_ "SPN" SG_ 2565869457 Aftrtrtmnt1OtltNOxReadingStable 3230;
BA_ "SPN" SG_ 2565869457 Aftrtrtmnt1OtltWdRngO2RdngStable 3231;
BA_ "SPN" SG_ 2565869457 Aft1OtltGasSnsrHtrPrelimFMI 3232;
BA_ "SPN" SG_ 2565869457 Aftrtrtmnt1OtltGasSensorHtrCtrl 3233;
BA_ "SPN" SG_ 2565869457 Aftrtrtmnt1OtltNOxSnsrPrelimFMI 3234;
BA_ "SPN" SG_ 2565869457 Aft1OtltNOxSnsrSelfDiagnssStat 5713;
BA_ "SPN" SG_ 2565869457 Aftrtrtmnt1OtltO2SensorPrelimFMI 3235;
BA_ "GenSigStartValue" SG_ 2565869201 Aft1SlctiveCtlytcRedIntkNOx 4000;
BA_ "SPN" SG_ 2565869201 Aft1SlctiveCtlytcRedIntkNOx 3216;
BA_ "GenSigStartValue" SG_ 2565869201 Aftertreatment1IntakePercentO2 23346.3035019455;
BA_ "SPN" SG_ 2565869201 Aftertreatment1IntakePercentO2 3217;
BA_ "SPN" SG_ 2565869201 Aftrtrtmnt1IntkGasSensorPwrInRng 3218;
BA_ "SPN" SG_ 2565869201 Aftrtrtmnt1IntkGasSnsrAtTemp 3219;
BA_ "SPN" SG_ 2565869201 Aft1SlctiveCtlytcRedIntkNOxRdngS 3220;
BA_ "SPN" SG_ 2565869201 Aft1IntkWdRngPrcntO2RdngStable 3221;
BA_ "SPN" SG_ 2565869201 Aft1IntkGasSnsrHtrPrelimFMI 3222;
BA_ "SPN" SG_ 2565869201 Aftrtrtmnt1IntkGasSensorHtrCtrl 3223;
BA_ "SPN" SG_ 2565869201 Aft1SlctiveCtlytcRedIntkNOxSnsrP 3224;
BA_ "SPN" SG_ 2565869201 Aft1IntkNOxSnsrSelfDiagnssStat 5714;
BA_ "SPN" SG_ 2565869201 Aftrtrtmnt1IntkO2SensorPrelimFMI 3225;
BA_ "SPN" SG_ 2566805137 Aftrtrtmnt1DslExhstFldTankLevel 1761;
BA_ "GenSigStartValue" SG_ 2566805137 Aftrtrtmnt1DslExhstFldTnkTemp 40;
BA_ "SPN" SG_ 2566805137 Aftrtrtmnt1DslExhstFldTnkTemp 3031;
BA_ "SPN" SG_ 2566805137 Aftrtrtmnt1DslExhstFldTankLevel2 3517;
BA_ "SPN" SG_ 2566805137 Aft1DslExhstFldTnkLvlPrelimFMI 3532;
BA_ "SPN" SG_ 2566805137 AftSlctiveCtlytcRedOprtrIndcmntA 5245;
BA_ "SPN" SG_ 2566805137 Aft1DslExhstFldTnk1TempPrelimFMI 4365;
BA_ "SPN" SG_ 2566805137 AftrtrtmntSCROprtrIndcmntSvrty 5246;
BA_ "SPN" SG_ 2566805137 Aftrtrtmnt1DslExhstFldTankHeater 3363;
BA_ "SPN" SG_ 2566805137 Aft1DslExhstFldTnk1HtrPrelimFMI 4366;
BA_ "GenSigStartValue" SG_ 2566757265 Aftrtrtmnt1DslExhstFldTemp2 40;
BA_ "SPN" SG_ 2566757265 Aftrtrtmnt1DslExhstFldTemp2 3515;
BA_ "SPN" SG_ 2566757265 Aft1DslExhstFldConcentration 3516;
BA_ "SPN" SG_ 2566757265 Aft1DslExhstFldConductivity 3518;
BA_ "SPN" SG_ 2566757265 Aft1DslExhstFldTemp2PrelimFMI 3519;
BA_ "SPN" SG_ 2566757265 Aft1DslExhstFldPropPrelimFMI 3520;
BA_ "SPN" SG_ 2566757265 Aftrtrtmnt1DslExhstFluidProperty 3521;
BA_ "GenSigStartValue" SG_ 2566733457 FD3E_ATS1SCRcataOurtakeGasTemp 8736;
BA_ "GenSigStartValue" SG_ 2566733457 FD3E_ATS1SCRcataIntakeGasTemp 8736;
BA_ "SPN" SG_ 2566758801 Aftertreatment1FuelPressure1 3480;
BA_ "SPN" SG_ 2566758801 Aftertreatment1FuelRate 3481;
BA_ "SPN" SG_ 2566758801 Aftrtrtmnt1FuelPressure1Control 3479;
BA_ "SPN" SG_ 2566758801 Aftertreatment1FuelDrainActuator 4097;
BA_ "SPN" SG_ 2566758801 Aftertreatment1Ignition 3484;
BA_ "SPN" SG_ 2566758801 Aftrtrtmnt1RegenerationStatus 3483;
BA_ "SPN" SG_ 2566758801 Aftertreatment1FuelEnableActr 3482;
BA_ "SPN" SG_ 2566758801 Aftrtrtmnt1FuelInjector1HtrCtrl 4301;
BA_ "GenSigStartValue" SG_ 2566763409 Aftrtrtmnt1ExhaustTemperature3 8736;
BA_ "SPN" SG_ 2566763409 Aftrtrtmnt1ExhaustTemperature3 3245;
BA_ "GenSigStartValue" SG_ 2566763409 Aftrtrtmnt1DslPFOtltTemperature 8736;
BA_ "SPN" SG_ 2566763409 Aftrtrtmnt1DslPFOtltTemperature 3246;
BA_ "SPN" SG_ 2566763409 Aftrtrtmnt1ExhstTemp3PrelimFMI 3247;
BA_ "SPN" SG_ 2566763409 Aft1DslPFOtltExhstTempPrelimFMI 3248;
BA_ "GenSigStartValue" SG_ 2566809856 FE69_EngCAC1OutTemp 8736;
BA_ "GenSigStartValue" SG_ 2566824960 FEA4_EGexhaust1Temp 8736;
BA_ "GenSigStartValue" SG_ 2566824960 FEA4_EGexhaustGR1DP 32000;
BA_ "GenSigStartValue" SG_ 2566763665 Aftrtrtmnt1ExhaustTemperature1 8736;
BA_ "SPN" SG_ 2566763665 Aftrtrtmnt1ExhaustTemperature1 3241;
BA_ "GenSigStartValue" SG_ 2566763665 Aftrtrtmnt1DslPFIntkTemperature 8736;
BA_ "SPN" SG_ 2566763665 Aftrtrtmnt1DslPFIntkTemperature 3242;
BA_ "SPN" SG_ 2566763665 Aftrtrtmnt1ExhstTemp1PrelimFMI 3243;
BA_ "SPN" SG_ 2566763665 Aft1DslPFIntkTempPrelimFMI 3244;
BA_ "SPN" SG_ 2565472296 ParameterGroupNumber 2540;
BA_ "SPN" SG_ 2364539648 AcceleratorPedal1LowIdleSwitch 558;
BA_ "SPN" SG_ 2364539648 AcceleratorPedalKickdownSwitch 559;
BA_ "SPN" SG_ 2364539648 RoadSpeedLimitStatus 1437;
BA_ "SPN" SG_ 2364539648 AcceleratorPedal2LowIdleSwitch 2970;
BA_ "SPN" SG_ 2364539648 AcceleratorPedalPosition1 91;
BA_ "SPN" SG_ 2364539648 EnginePercentLoadAtCurrentSpeed 92;
BA_ "SPN" SG_ 2364539648 RemoteAcceleratorPedalPosition 974;
BA_ "SPN" SG_ 2364539648 AcceleratorPedalPosition2 29;
BA_ "SPN" SG_ 2364539648 VehicleAccltnRateLimitStatus 2979;
BA_ "SPN" SG_ 2364539648 MomentaryEngMaxPowerEnblFdbck 5021;
BA_ "SPN" SG_ 2364539648 DPFThermalManagementActive 5399;
BA_ "SPN" SG_ 2364539648 SCRThermalManagementActive 5400;
BA_ "SPN" SG_ 2364539648 ActlMaximumAvailEngPercentTorque 3357;
BA_ "GenSigStartValue" SG_ 2364539648 EstimatedPumpingPercentTorque 125;
BA_ "SPN" SG_ 2364539648 EstimatedPumpingPercentTorque 5398;
BA_ "SPN" SG_ 2364539904 EngineTorqueMode 899;
BA_ "SPN" SG_ 2364539904 ActualEnginePercentTorqueFract 4154;
BA_ "GenSigStartValue" SG_ 2364539904 DriversDemandEnginePercentTorque 125;
BA_ "SPN" SG_ 2364539904 DriversDemandEnginePercentTorque 512;
BA_ "GenSigStartValue" SG_ 2364539904 ActualEnginePercentTorque 125;
BA_ "SPN" SG_ 2364539904 ActualEnginePercentTorque 513;
BA_ "SPN" SG_ 2364539904 EngineSpeed 190;
BA_ "SPN" SG_ 2364539904 SrcAddrOfCtrllingDevForEngCtrl 1483;
BA_ "SPN" SG_ 2364539904 EngineStarterMode 1675;
BA_ "GenSigStartValue" SG_ 2364539904 EngineDemandPercentTorque 125;
BA_ "SPN" SG_ 2364539904 EngineDemandPercentTorque 2432;
BA_ "GenSigStartValue" SG_ 2565866755 TransmissionSelectedGear 125;
BA_ "SPN" SG_ 2565866755 TransmissionSelectedGear 524;
BA_ "SPN" SG_ 2565866755 TransmissionActualGearRatio 526;
BA_ "GenSigStartValue" SG_ 2565866755 TransmissionCurrentGear 125;
BA_ "SPN" SG_ 2565866755 TransmissionCurrentGear 523;
BA_ "SPN" SG_ 2565866755 TransmissionRequestedRange_L 162;
BA_ "SPN" SG_ 2565866755 TransmissionCurrentRange 163;
BA_ "SPN" SG_ 2566801923 TrnsmCurrentRngDisplayBlankStat 4176;
BA_ "SPN" SG_ 2566801923 TransmissionServiceIndicator 4178;
BA_ "SPN" SG_ 2566801923 TrnsmRqedRngDisplayBlankStat 1850;
BA_ "SPN" SG_ 2566801923 TrnsmRqedRngDisplayFlashStat 1849;
BA_ "SPN" SG_ 2566801923 TransmissionReadyForBrakeRelease 3086;
BA_ "SPN" SG_ 2566801923 ActiveShiftConsoleIndicator 2945;
BA_ "SPN" SG_ 2566801923 TransmissionEngineCrankEnable 2900;
BA_ "SPN" SG_ 2566801923 TransmissionShiftInhibitIndictr 1851;
BA_ "SPN" SG_ 2566801923 TransmissionMode4Indicator 2539;
BA_ "SPN" SG_ 2566801923 TransmissionMode3Indicator 2538;
BA_ "SPN" SG_ 2566801923 TransmissionMode2Indicator 2537;
BA_ "SPN" SG_ 2566801923 TransmissionMode1Indicator 2536;
BA_ "GenSigStartValue" SG_ 2566801923 TransmissionRequestedGearFdbck 125;
BA_ "SPN" SG_ 2566801923 TransmissionRequestedGearFdbck 3289;
BA_ "SPN" SG_ 2566801923 TransmissionMode5Indicator 4250;
BA_ "SPN" SG_ 2566801923 TransmissionMode6Indicator 4251;
BA_ "SPN" SG_ 2566801923 TransmissionMode7Indicator 4252;
BA_ "SPN" SG_ 2566801923 TransmissionMode8Indicator 4253;
BA_ "SPN" SG_ 2566801923 TrnsmReverseGearShftInhbtStat 4261;
BA_ "SPN" SG_ 2566801923 TransmissionWarningIndicator 5344;
BA_ "SPN" SG_ 2566801923 TransmissionMode9Indicator 6567;
BA_ "SPN" SG_ 2566801923 TransmissionMode10Indicator 6568;
BA_ "SPN" SG_ 2566801923 TrnsmAirSupplyPressIndictr 6566;
BA_ "GenSigStartValue" SG_ 2566902817 FFD4_Coolant_Temp_Mech 40;
BA_ "GenSigStartValue" SG_ 2566902817 FFD4_Hydraulic_Oil_Temp 40;
BA_ "GenSigStartValue" SG_ 2566904097 FFD9_CondensorFanControl 32127;
BA_ "GenSigStartValue" SG_ 2566904097 FFD9_CACFanControl 32127;
BA_ "GenSigStartValue" SG_ 2566903841 FFD8_CoolantTemp 40;
BA_ "GenSigStartValue" SG_ 2566903841 FFD8_WL_AxleOilTemp 40;
BA_ "GenSigStartValue" SG_ 2566903841 FFD8_HydraulicTemp 40;
BA_ "GenSigStartValue" SG_ 2566755587 TRF2TrqConOilOutletTemp 8736;
BA_ "SPN" SG_ 2365542945 ZFTC1TrmMode7 4248;
BA_ "SPN" SG_ 2566841088 EC1Engine_Max_Overr_Speed_Point7 1331;
BA_ "SPN" SG_ 2566841088 EC1Engine_PercTorque_Idle_Point1 1337;
BA_ "SPN" SG_ 2566841088 EC1Engine_PercTorque_Point2 1344;
BA_ "SPN" SG_ 2566841088 EC1Engine_PercTorque_Point3 1345;
BA_ "SPN" SG_ 2566841088 EC1Engine_PercTorque_Point4 1346;
BA_ "SPN" SG_ 2566841088 EC1Engine_PercTorque_Point5 1347;
BA_ "SPN" SG_ 2566841088 EC1Engine_Speed_Idle_Point1 392;
BA_ "SPN" SG_ 2566841088 EC1Engine_Speed_Point2 1320;
BA_ "SPN" SG_ 2566841088 EC1Engine_Speed_Point3 1321;
BA_ "SPN" SG_ 2566841088 EC1Engine_Speed_Point4 1328;
BA_ "SPN" SG_ 2566841088 EC1Engine_Speed_Point5 1329;
BA_ "SPN" SG_ 2566841088 EC1Engine_Speed_Point6 1330;
BA_ "SPN" SG_ 2566841088 EC1Engine_Reference_Torque 1348;
BA_ "SPN" SG_ 2566767875 ECUType 234;
BA_ "SPN" SG_ 2566767875 ECUSerialNumber 234;
BA_ "SPN" SG_ 2566767875 ECULocation 234;
BA_ "SPN" SG_ 2566767875 ECU_Manufacturer 234;
BA_ "SPN" SG_ 2566767875 ECU_PartNumber 234;
BA_ "SPN" SG_ 2566838787 FEDA_OptionalField_2 234;
BA_ "SPN" SG_ 2566838787 FEDA_OptionalField_1 234;
BA_ "SPN" SG_ 2566838787 FEDA_TransmissionPartNumber 234;
BA_ "SPN" SG_ 2566838787 FEDA_SWVersion 234;
BA_ "SPN" SG_ 2566838787 FEDA_SWPartNumber 234;
BA_ "SPN" SG_ 2566838787 FEDA_NumberOfSWIdentification 965;
BA_ "SPN" SG_ 2565603072 SequenceNumber 2572;
BA_ "SPN" SG_ 2565668608 PGNumber 2560;
BA_ "SPN" SG_ 2565668608 TotalNumberOfPacketsEoMA 2558;
BA_ "SPN" SG_ 2565668608 TotalMessageSizeEoMA 2557;
BA_ "SPN" SG_ 2565668608 TotalMessageSizeBAM 2557;
BA_ "SPN" SG_ 2565668608 TotalNumberOfPacketsBAM 2558;
BA_ "SPN" SG_ 2565668608 ConnectionAbortReason 2570;
BA_ "SPN" SG_ 2565668608 NextPacketNumberToBeSent 2562;
BA_ "SPN" SG_ 2565668608 NumberOfPacketsThatCanBeSent 2561;
BA_ "SPN" SG_ 2565668608 MaximumNumberOfPackets 2559;
BA_ "SPN" SG_ 2565668608 TotalNumberOfPackets 2558;
BA_ "SPN" SG_ 2565668608 TotalMessageSize 2557;
BA_ "SPN" SG_ 2565482529 ParameterGroupNumber 2574;
BA_ "SPN" SG_ 2565537536 ParameterGroupNumber 2540;
BA_ "SPN" SG_ 2565472289 ParameterGroupNumber 2540;
BA_ "SPN" SG_ 2565480744 ParameterGroupNumber 2540;
BA_ "SPN" SG_ 2566835456 FreezeFrameLength 1217;
BA_ "SPN" SG_ 2566835456 SuspectParameterNumber 1214;
BA_ "SPN" SG_ 2566835456 FailureModeIdentifier 1215;
BA_ "SPN" SG_ 2566835456 OccurrenceCount 1216;
BA_ "SPN" SG_ 2566835456 SPNConversionMethod 1706;
BA_ "SPN" SG_ 2566835456 ManufacturerSpecifiedInformation 4263;
BA_ "SPN" SG_ 2566835712 ActiveTroubleCodes 1218;
BA_ "SPN" SG_ 2566835712 PreviouslyActiveTroubleCodes 1219;
BA_ "SPN" SG_ 2566835712 OBDCompliance 1220;
BA_ "SPN" SG_ 2566835712 CntinlyMontrdSystemsSupportStat 1221;
BA_ "SPN" SG_ 2566835712 NonCntinlyMontrdSystemsSupport 1222;
BA_ "SPN" SG_ 2566835712 NonCntinlyMonitoredSystemsStatus 1223;
BA_ "SPN" SG_ 2566835968 ProtectLamp 987;
BA_ "SPN" SG_ 2566835968 AmberWarningLamp 624;
BA_ "SPN" SG_ 2566835968 RedStopLamp 623;
BA_ "SPN" SG_ 2566835968 MalfunctionIndicatorLamp 1213;
BA_ "SPN" SG_ 2566835968 FlashProtectLamp 3041;
BA_ "SPN" SG_ 2566835968 FlashAmberWarningLamp 3040;
BA_ "SPN" SG_ 2566835968 FlashRedStopLamp 3039;
BA_ "SPN" SG_ 2566835968 FlashMalfunctionIndicatorLamp 3038;
BA_ "SPN" SG_ 2566835968 SuspectParameterNumber 1214;
BA_ "SPN" SG_ 2566835968 FailureModeIdentifier 1215;
BA_ "SPN" SG_ 2566835968 OccurrenceCount 1216;
BA_ "SPN" SG_ 2566835968 SPNConversionMethod 1706;
BA_ "GenSigStartValue" SG_ 2566889768 FFA1_LocalHourOffset 125;
BA_ "GenSigStartValue" SG_ 2566889768 FFA1_LocalMinuteOffset 125;
BA_ "GenSigStartValue" SG_ 2566889768 FFA1_Year -1985;
BA_ "SPN" SG_ 2633940480 EngineRatedPower 166;
BA_ "SPN" SG_ 2633940480 EngineRatedSpeed 189;
BA_ "SPN" SG_ 2633940480 EngineRotationDirection 3669;
BA_ "SPN" SG_ 2633940480 EngIntkManifoldPressureCtrlMode 5465;
BA_ "SPN" SG_ 2633940480 CrankAttmptCntOnPrsntStartAttmpt 3671;
BA_ "SPN" SG_ 2566748928 Aftrtrtmnt1DslPFSootLoadPercent 3719;
BA_ "SPN" SG_ 2566748928 Aftrtrtmnt1DslPFAshLoadPercent 3720;
BA_ "SPN" SG_ 2566748928 Aft1DslPFTmeSncLastActvRegen 3721;
BA_ "SPN" SG_ 2566748928 Aft1DslPFSootLoadRegenTrshld 5466;
BA_ "SPN" SG_ 2566758656 Aftertreatment1FuelPressure1 3480;
BA_ "SPN" SG_ 2566758656 Aftertreatment1FuelRate 3481;
BA_ "SPN" SG_ 2566758656 Aftrtrtmnt1FuelPressure1Control 3479;
BA_ "SPN" SG_ 2566758656 Aftertreatment1FuelDrainActuator 4097;
BA_ "SPN" SG_ 2566758656 Aftertreatment1Ignition 3484;
BA_ "SPN" SG_ 2566758656 Aftrtrtmnt1RegenerationStatus 3483;
BA_ "SPN" SG_ 2566758656 Aftertreatment1FuelEnableActr 3482;
BA_ "SPN" SG_ 2566758656 Aftrtrtmnt1FuelInjector1HtrCtrl 4301;
BA_ "GenSigStartValue" SG_ 2566763008 Aftrtrtmnt1ExhaustTemperature2 8736;
BA_ "SPN" SG_ 2566763008 Aftrtrtmnt1ExhaustTemperature2 3249;
BA_ "GenSigStartValue" SG_ 2566763008 Aftrtrtmnt1DslPFIntrmedTemp 8736;
BA_ "SPN" SG_ 2566763008 Aftrtrtmnt1DslPFIntrmedTemp 3250;
BA_ "SPN" SG_ 2566763008 Aftrtrtmnt1DslPFDiffPressure 3251;
BA_ "SPN" SG_ 2566763008 Aftrtrtmnt1ExhstTemp2PrelimFMI 3252;
BA_ "SPN" SG_ 2566763008 Aft1DslPFDeltaPressPrelimFMI 3253;
BA_ "SPN" SG_ 2566763008 Aft1DslPFIntrmedTempPrelimFMI 3254;
BA_ "GenSigStartValue" SG_ 2566763264 Aftrtrtmnt1ExhaustTemperature3 8736;
BA_ "SPN" SG_ 2566763264 Aftrtrtmnt1ExhaustTemperature3 3245;
BA_ "GenSigStartValue" SG_ 2566763264 Aftrtrtmnt1DslPFOtltTemperature 8736;
BA_ "SPN" SG_ 2566763264 Aftrtrtmnt1DslPFOtltTemperature 3246;
BA_ "SPN" SG_ 2566763264 Aftrtrtmnt1ExhstTemp3PrelimFMI 3247;
BA_ "SPN" SG_ 2566763264 Aft1DslPFOtltExhstTempPrelimFMI 3248;
BA_ "GenSigStartValue" SG_ 2566763520 Aftrtrtmnt1ExhaustTemperature1 8736;
BA_ "SPN" SG_ 2566763520 Aftrtrtmnt1ExhaustTemperature1 3241;
BA_ "GenSigStartValue" SG_ 2566763520 Aftrtrtmnt1DslPFIntkTemperature 8736;
BA_ "SPN" SG_ 2566763520 Aftrtrtmnt1DslPFIntkTemperature 3242;
BA_ "SPN" SG_ 2566763520 Aftrtrtmnt1ExhstTemp1PrelimFMI 3243;
BA_ "SPN" SG_ 2566763520 Aft1DslPFIntkTempPrelimFMI 3244;
BA_ "SPN" SG_ 2566804992 Aftrtrtmnt1DslExhstFldTankLevel 1761;
BA_ "GenSigStartValue" SG_ 2566804992 Aftrtrtmnt1DslExhstFldTnkTemp 40;
BA_ "SPN" SG_ 2566804992 Aftrtrtmnt1DslExhstFldTnkTemp 3031;
BA_ "SPN" SG_ 2566804992 Aftrtrtmnt1DslExhstFldTankLevel2 3517;
BA_ "SPN" SG_ 2566804992 Aft1DslExhstFldTnkLvlPrelimFMI 3532;
BA_ "SPN" SG_ 2566804992 AftSlctiveCtlytcRedOprtrIndcmntA 5245;
BA_ "SPN" SG_ 2566804992 Aft1DslExhstFldTnk1TempPrelimFMI 4365;
BA_ "SPN" SG_ 2566804992 AftrtrtmntSCROprtrIndcmntSvrty 5246;
BA_ "SPN" SG_ 2566804992 Aftrtrtmnt1DslExhstFldTankHeater 3363;
BA_ "SPN" SG_ 2566804992 Aft1DslExhstFldTnk1HtrPrelimFMI 4366;
BA_ "SPN" SG_ 2566841344 EngIdleShutdownHasShutdownEngine 593;
BA_ "SPN" SG_ 2566841344 EngineIdleShutdownDrvrAlertMode 594;
BA_ "SPN" SG_ 2566841344 EngineIdleShutdownTimerOverride 592;
BA_ "SPN" SG_ 2566841344 EngineIdleShutdownTimerState 590;
BA_ "SPN" SG_ 2566841344 EngineIdleShutdownTimerFunction 591;
BA_ "SPN" SG_ 2566841344 ACHighPressureFanSwitch 985;
BA_ "SPN" SG_ 2566841344 RefrigerantLowPressureSwitch 875;
BA_ "SPN" SG_ 2566841344 RefrigerantHighPressureSwitch 605;
BA_ "SPN" SG_ 2566841344 EngineWaitToStartLamp 1081;
BA_ "SPN" SG_ 2566841344 EngPrtctnSystemHasShutdownEng 1110;
BA_ "SPN" SG_ 2566841344 EngPrtctnSystemApproachingShtdwn 1109;
BA_ "SPN" SG_ 2566841344 EngProtectionSystemTimerOverride 1108;
BA_ "SPN" SG_ 2566841344 EngineProtectionSystemTimerState 1107;
BA_ "SPN" SG_ 2566841344 EngineProtectionSystemConf 1111;
BA_ "SPN" SG_ 2566841344 EngineAlarmAcknowledge 2815;
BA_ "SPN" SG_ 2566841344 EngineAlarmOutputCommandStatus 2814;
BA_ "SPN" SG_ 2566841344 EngineAirShutoffCommandStatus 2813;
BA_ "SPN" SG_ 2566841344 EngineOverspeedTest 2812;
BA_ "SPN" SG_ 2566841344 EngineAirShutoffStatus 3667;
BA_ "SPN" SG_ 2566841344 PTOShutdownHasShutdownEngine 5404;
BA_ "SPN" SG_ 2566841344 CoolntLvlEngPrtctnShutdownStatus 5566;
BA_ "SPN" SG_ 2566842624 EngineTripFuel 182;
BA_ "SPN" SG_ 2566842624 EngineTotalFuelUsed 250;
BA_ "GenSigStartValue" SG_ 2566843904 EngineCoolantTemperature 40;
BA_ "SPN" SG_ 2566843904 EngineCoolantTemperature 110;
BA_ "GenSigStartValue" SG_ 2566843904 EngineFuelTemperature1 40;
BA_ "SPN" SG_ 2566843904 EngineFuelTemperature1 174;
BA_ "GenSigStartValue" SG_ 2566843904 EngineOilTemperature1 8736;
BA_ "SPN" SG_ 2566843904 EngineOilTemperature1 175;
BA_ "GenSigStartValue" SG_ 2566843904 EngineTurbochargerOilTemperature 8736;
BA_ "SPN" SG_ 2566843904 EngineTurbochargerOilTemperature 176;
BA_ "GenSigStartValue" SG_ 2566843904 EngineIntercoolerTemperature 40;
BA_ "SPN" SG_ 2566843904 EngineIntercoolerTemperature 52;
BA_ "SPN" SG_ 2566843904 EngChargeAirCoolThrmsttOpening 1134;
BA_ "SPN" SG_ 2566844160 EngineFuelDeliveryPressure 94;
BA_ "SPN" SG_ 2566844160 EngExtendedCrankCsBlowByPressure 22;
BA_ "SPN" SG_ 2566844160 EngineOilLevel 98;
BA_ "SPN" SG_ 2566844160 EngineOilPressure 100;
BA_ "GenSigStartValue" SG_ 2566844160 EngineCrankcasePressure1 32000;
BA_ "SPN" SG_ 2566844160 EngineCrankcasePressure1 101;
BA_ "SPN" SG_ 2566844160 EngineCoolantPressure 109;
BA_ "SPN" SG_ 2566844160 EngineCoolantLevel1 111;
BA_ "SPN" SG_ 2566848256 WaterInFuelIndicator1 97;
BA_ "SPN" SG_ 2566848256 OperatorShiftPrompt 5675;
BA_ "SPN" SG_ 2566848256 WaterInFuelIndicator2 6301;
BA_ "SPN" SG_ 2566848256 DrvrWarningSystemIndicatorStatus 5825;
BA_ "SPN" SG_ 2566848256 EmissionCtrlSysOprtrIndcmntSvrty 5826;
BA_ "SPN" SG_ 2565865487 RetarderTorqueMode 900;
BA_ "SPN" SG_ 2565865487 RetarderEnableBrakeAssistSwitch 571;
BA_ "SPN" SG_ 2565865487 RetarderEnableShiftAssistSwitch 572;
BA_ "GenSigStartValue" SG_ 2565865487 ActualRetarderPercentTorque 125;
BA_ "SPN" SG_ 2565865487 ActualRetarderPercentTorque 520;
BA_ "GenSigStartValue" SG_ 2565865487 IntendedRetarderPercentTorque 125;
BA_ "SPN" SG_ 2565865487 IntendedRetarderPercentTorque 1085;
BA_ "SPN" SG_ 2565865487 EngineCoolantLoadIncrease 1082;
BA_ "SPN" SG_ 2565865487 RetarderRequestingBrakeLight 1667;
BA_ "SPN" SG_ 2565865487 RetarderRoadSpeedLimitSwitch 4233;
BA_ "SPN" SG_ 2565865487 RetarderRoadSpeedExceededStatus 4234;
BA_ "SPN" SG_ 2565865487 SrcAddrOfCtrllingDevForRtrdrCtrl 1480;
BA_ "GenSigStartValue" SG_ 2565865487 DriversDmndRetarderPercentTorque 125;
BA_ "SPN" SG_ 2565865487 DriversDmndRetarderPercentTorque 1715;
BA_ "SPN" SG_ 2565865487 RetarderSelection_NonEngine 1716;
BA_ "GenSigStartValue" SG_ 2565865487 ActlMaxAvailRetarderPrcntTorque 125;
BA_ "SPN" SG_ 2565865487 ActlMaxAvailRetarderPrcntTorque 1717;
BA_ "SPN" SG_ 2566844928 EngineFuelRate 183;
BA_ "SPN" SG_ 2566844928 EngineInstantaneousFuelEconomy 184;
BA_ "SPN" SG_ 2566844928 EngineAverageFuelEconomy 185;
BA_ "SPN" SG_ 2566844928 EngineThrottleValve1Position1 51;
BA_ "SPN" SG_ 2566844928 EngineThrottleValve2Position 3673;
VAL_ 2564816896 E000_AtRegenForceSW 3 "Description for the value '0x3'" 2 "Error" 1 "active" 0 "not active " ;
VAL_ 2564816896 E000_AtRegenInhibitSW 3 "Description for the value '0x3'" 2 "Error" 1 "active" 0 "not active " ;
VAL_ 2566754816 FD92_EngOperState 15 "Not available" 14 "Reserved>" 13 "available for SAE assignment" 12 "available for SAE assignment" 11 "available for SAE assignment" 10 "available for SAE assignment" 9 "available for SAE assignment" 8 "available for SAE assignment" 7 "Post-Run" 6 "Engine Stopping" 5 "Cool-down" 4 "Running" 3 "Warm-Up" 2 "Starting" 1 "Pre-Start" 0 "Engine Stopped" ;
VAL_ 2565874577 F023_AT1SCRSysState 15 "Not available" 14 "Error" 13 "Reserved for future assignment" 12 "Reserved for future assignment" 11 "Reserved for future assignment" 10 "Service test mode,  not allowed" 9 "Service test mode,  allowed" 8 "Diagnosis (afterrun)" 7 "Shutoff (wait for afterrun)" 6 "Protect mode against cold " 5 "Protect mode against heat " 4 "Reserved for future assignment " 3 "System error pending" 2 "Normal dosing operation" 1 "Preparing dosing readiness " 0 "Dormant (sleep mode)" ;
VAL_ 2566699921 FCBB_AT1DEFCM1PowerSupply1 3 "Not available" 2 "Error" 1 "On" 0 "Off" ;
VAL_ 2566699921 FCBB_AT1DEFCM1RelayCTRL 3 "Not available" 2 "Error" 1 "On" 0 "Off" ;
VAL_ 2566810112 FE6A_FuelPumpPriStatus 3 "Not available" 2 "Error" 1 "On" 0 "Off" ;
VAL_ 2565869457 Aftrtrtmnt1OtltGasSensorPwrInRng 0 "Not in range" 1 "In range" 2 "Error" 3 "Not available" ;
VAL_ 2565869457 Aftrtrtmnt1OtltGasSnsrAtTemp 0 "Not in range" 1 "In range" 2 "Error" 3 "Not available" ;
VAL_ 2565869457 Aftrtrtmnt1OtltNOxReadingStable 0 "Not stable" 1 "Stable" 2 "Error" 3 "Not available" ;
VAL_ 2565869457 Aftrtrtmnt1OtltWdRngO2RdngStable 0 "Not stable" 1 "Stable" 2 "Error" 3 "Not available" ;
VAL_ 2565869457 Aftrtrtmnt1OtltGasSensorHtrCtrl 0 "Automatic" 1 "Preheat 2" 2 "Preheat 1" 3 "Heater off" ;
VAL_ 2565869457 Aft1OtltNOxSnsrSelfDiagnssStat 0 "Diagnosis not active" 1 "NOx Sensor ATO1 Self Diagnosis active flag" 2 "NOx Sensor ATO1 Self Diagnosis Result Complete" 3 "NOx Sensor ATO1 Self Diagnosis aborted" 4 "NOx Sensor ATO1 Self Diagnosis not possible" 7 "Not Supported" ;
VAL_ 2565869201 Aftrtrtmnt1IntkGasSensorPwrInRng 0 "Not in range" 1 "In range" 2 "Error" 3 "Not available" ;
VAL_ 2565869201 Aftrtrtmnt1IntkGasSnsrAtTemp 0 "Not in range" 1 "In range" 2 "Error" 3 "Not available" ;
VAL_ 2565869201 Aft1SlctiveCtlytcRedIntkNOxRdngS 0 "Not stable" 1 "Stable" 2 "Error" 3 "Not available" ;
VAL_ 2565869201 Aft1IntkWdRngPrcntO2RdngStable 0 "Not stable" 1 "Stable" 2 "Error" 3 "Not available" ;
VAL_ 2565869201 Aftrtrtmnt1IntkGasSensorHtrCtrl 0 "Automatic" 1 "Preheat 2" 2 "Preheat 1" 3 "Heater off" ;
VAL_ 2565869201 Aft1IntkNOxSnsrSelfDiagnssStat 0 "Diagnosis not active" 1 "NOx Sensor ATI1 Self Diagnosis active flag" 2 "NOx Sensor ATI1 Self Diagnosis Result Complete" 3 "NOx Sensor ATI1 Self Diagnosis aborted" 4 "NOx Sensor ATI1 Self Diagnosis not possible" 7 "Not Supported" ;
VAL_ 2566805137 AftSlctiveCtlytcRedOprtrIndcmntA 0 "Off" 1 "On solid" 2 "reserved for SAE assignment" 3 "reserved for SAE assignment" 4 "On fast blink (1 Hz)" 5 "reserved for SAE assignment" 6 "reserved for SAE assignment" 7 "not available" ;
VAL_ 2566805137 AftrtrtmntSCROprtrIndcmntSvrty 0 "Driver Warning" 1 "Inducement Level 1" 2 "Inducement Level 2" 3 "Inducement Level 3" 4 "Inducement Level 4" 5 "Inducement Level 5" 6 "Temporary Override of Inducement" 7 "Not Available / Not Supported" ;
VAL_ 2566757265 Aftrtrtmnt1DslExhstFluidProperty 0 "Urea concentration too high" 1 "Urea concentration too low" 2 "Fluid is diesel" 3 "Diesel exhaust fluid is proper mixture" 13 "Fluid type unknown" 14 "Fluid property detection error" 15 "Not available" ;
VAL_ 2566844416 FEF0_EGPTOGoverAccelSW 3 "Not available" 2 "Error" 1 "On" 0 "Off" ;
VAL_ 2566844416 FEF0_EGPTOGoverResumeSW 3 "Not available" 2 "Error" 1 "On" 0 "Off" ;
VAL_ 2566844416 FEF0_EGPTOGoverCoastDecelSW 3 "Not available" 2 "Error" 1 "On" 0 "Off" ;
VAL_ 2566844416 FEF0_EGPTOGoverSetSW 3 "Not available" 2 "Error" 1 "On" 0 "Off" ;
VAL_ 2566844416 FEF0_EGPTOGoverEnableSW 3 "Not available" 2 "Error" 1 "On" 0 "Off" ;
VAL_ 2348810273 TSC1OverrideControlModePriority 0 "Highest priority" 1 "High priority" 2 "Medium priority" 3 "Low priority" ;
VAL_ 2348810273 TSC1EngineOverrideCtrlMode 0 "Override disabled" 1 "Speed control" 2 "Torque control" 3 "Speed/torque limit control" ;
VAL_ 2364539648 AcceleratorPedal1LowIdleSwitch 0 "Accelerator pedal 1 not in low idle condition" 1 "Accelerator pedal 1 in low idle condition" 2 "Error" 3 "Not available" ;
VAL_ 2364539648 AcceleratorPedalKickdownSwitch 0 "Kickdown passive" 1 "Kickdown active" 2 "Error" 3 "Not available" ;
VAL_ 2364539648 RoadSpeedLimitStatus 0 "Active" 1 "Not Active" 2 "Error" 3 "Not available" ;
VAL_ 2364539648 AcceleratorPedal2LowIdleSwitch 0 "Accelerator pedal 2 not in low idle condition" 1 "Accelerator pedal 2 in low idle condition" 2 "Error" 3 "Not available" ;
VAL_ 2364539648 VehicleAccltnRateLimitStatus 0 "Limit not active" 1 "Limit active" 2 "Reserved" 3 "Not available" ;
VAL_ 2364539648 MomentaryEngMaxPowerEnblFdbck 0 "disabled" 1 "supported " 2 "reserved" 3 "don't care" ;
VAL_ 2364539648 DPFThermalManagementActive 0 "DPF Thermal Management is not active" 1 "DPF Thermal Management is active" 2 "Reserved" 3 "Don't care" ;
VAL_ 2364539648 SCRThermalManagementActive 0 "SCR Thermal Management is not active" 1 "SCR Thermal Management is active" 2 "Reserved" 3 "Don't care" ;
VAL_ 2364539904 ActualEnginePercentTorqueFract 0 "+0.000%" 1 "+0.125%" 2 "+0.250%" 3 "+0.375%" 4 "+0.500%" 5 "+0.625%" 6 "+0.750%" 7 "+0.875%" 8 "not available" ;
VAL_ 2364539904 EngineStarterMode 0 "start not requested" 1 "starter active: gear not engaged" 2 "starter active: gear engaged" 3 "start finished: starter not active" 4 "starter inhibited: engine running" 5 "starter inhibited: engine not ready for start" 6 "starter inhibited: driveline engaged" 7 "starter inhibited: active immobilizer" 8 "starter inhibited: starter over-temp" 9 "starter inhibited: intake air shutoff valve" 10 "starter inhibited: active SCR" 11 "Reserved" 12 "starter inhibited: reason unknown" 13 "error (legacy implementation only, use 1110)" 14 "error" 15 "not available" ;
VAL_ 2566801923 TrnsmCurrentRngDisplayBlankStat 0 "Not Blanked" 1 "Blanked" 2 "Error" 3 "Supported" ;
VAL_ 2566801923 TransmissionServiceIndicator 0 "Transmission Service Indicator is off" 1 "Transmission Service Indicator is on continuously" 2 "Transmission Service Indicator is flashing" 3 "Not available" ;
VAL_ 2566801923 TrnsmRqedRngDisplayBlankStat 0 "Inactive" 1 "Active" 2 "Reserved" 3 "Take no action" ;
VAL_ 2566801923 TrnsmRqedRngDisplayFlashStat 0 "Inactive" 1 "Active" 2 "Reserved" 3 "Take no action" ;
VAL_ 2566801923 TransmissionReadyForBrakeRelease 0 "Transmission Not Ready for Brake Release" 1 "Transmission Ready for Brake Release" 2 "Error" 3 "Not available" ;
VAL_ 2566801923 ActiveShiftConsoleIndicator 0 "Primary shift console is active" 1 "Secondary shift console is active" 2 "Reserved" 3 "Not available" ;
VAL_ 2566801923 TransmissionEngineCrankEnable 0 "Cranking disabled" 1 "Cranking enabled" 2 "Error" 3 "Not available" ;
VAL_ 2566801923 TransmissionShiftInhibitIndictr 0 "Inactive; shift is not inhibited" 1 "Active (on continuously); shift is inhibited" 2 "Active (flashing)" 3 "Take no action" ;
VAL_ 2566801923 TransmissionMode4Indicator 0 "Transmission Mode 4 not active" 1 "Transmission Mode 4 Active" 2 "Error" 3 "Not available" ;
VAL_ 2566801923 TransmissionMode3Indicator 0 "Transmission Mode 3 not active" 1 "Transmission Mode 3 Active" 2 "Error" 3 "Not available" ;
VAL_ 2566801923 TransmissionMode2Indicator 0 "Transmission Mode 2 not active" 1 "Transmission Mode 2 Active" 2 "Error" 3 "Not available" ;
VAL_ 2566801923 TransmissionMode1Indicator 0 "Transmission Mode 1 not active" 1 "Transmission Mode 1 Active" 2 "Error" 3 "Not available" ;
VAL_ 2566801923 TransmissionMode5Indicator 0 "Transmission Mode 5 not active" 1 "Transmission Mode 5 active" 2 "Error" 3 "Not available" ;
VAL_ 2566801923 TransmissionMode6Indicator 0 "Transmission Mode 6 not active" 1 "Transmission Mode 6 active" 2 "Error" 3 "Not available" ;
VAL_ 2566801923 TransmissionMode7Indicator 0 "Transmission Mode 7 not active" 1 "Transmission Mode 7 active" 2 "Error" 3 "Not available" ;
VAL_ 2566801923 TransmissionMode8Indicator 0 "Transmission Mode 8 not active" 1 "Transmission Mode 8 active" 2 "Error" 3 "Not available" ;
VAL_ 2566801923 TrnsmReverseGearShftInhbtStat 0 "Reverse gear shifts are currently allowed" 1 "Reverse gear shifts are currently inhibited" 2 "Error" 3 "Not Available" ;
VAL_ 2566801923 TransmissionWarningIndicator 0 "Transmission Warning Indicator is off" 1 "Transmission Warning Indicator is on continuously" 2 "Transmission Warning Indicator is flashing" 3 "Not available" ;
VAL_ 2566801923 TransmissionMode9Indicator 0 "Transmission Mode 9 not active" 1 "Transmission Mode 9 active" 2 "Error indicator" 3 "Not available" ;
VAL_ 2566801923 TransmissionMode10Indicator 0 "Transmission Mode 10 not active" 1 "Transmission Mode 10 active" 2 "Error indicator" 3 "Not available" ;
VAL_ 2566801923 TrnsmAirSupplyPressIndictr 0 "Normal Pressure Range" 1 "Low pressure" 2 "Very low pressure" 3 "No pressure" 4 "Over pressure" 5 "Not defined" 6 "Error indicator" 7 "Not available" ;
VAL_ 2566903585 FFD7_073_MCV_EPPR_cutoff_SV 1 "ON" 0 "OFF" ;
VAL_ 2566903585 FFD7_071_Bs_Spool_SV 1 "ON" 0 "OFF" ;
VAL_ 2566903585 FFD7_067_QuickCoupler_SV 1 "ON" 0 "OFF" ;
VAL_ 2566903585 FFD7_065_FreeBoom_Dw_SV 1 "ON" 0 "OFF" ;
VAL_ 2566903585 FFD7_063_FreeBoom_Up_SV 1 "ON" 0 "OFF" ;
VAL_ 2566903585 FFD7_061_TravelStraight_SV 1 "ON" 0 "OFF" ;
VAL_ 2566903585 FFD7_057_Rotating_CCW_SV 1 "ON" 0 "OFF" ;
VAL_ 2566903585 FFD7_055_Rotating_CW_SV 1 "ON" 0 "OFF" ;
VAL_ 2566870275 FF55_Extend_ColdstartPhase 15 "Coldstart not necessary" 14 "Coldstart Successfully Finished" 13 "Limited Driving" 12 "Wait for Limited Drive Request " 11 "Preperation for Limited Drive" 9 "Pulsing Range Clutches" 7 "Heating up of clutch n valve" 5 "Puls of Hydrostat Control Valve" 3 "Check System Pressrue Ongoing" 1 "Engine Warm Up Phase" 0 "Cold Start init" ;
VAL_ 2566870275 FF55_BreakCondition 15 "Not available" 14 "Error " 12 "Temp. Sensor Timeout" 11 "Internal Failure" 10 "Operation mode not normal" 9 "Requested Gear not Neutral" 8 "High Pressure Too Low" 7 "High Pressure Too High" 6 "Speed nKC Too Low" 5 "Speed nKR Too High" 4 "Trans Output Turning" 3 "Parkbrake not Engaged" 2 "Engine Speed Too Low" 1 "Engine Speed Too High" 0 "All Condition fulfilled" ;
VAL_ 2566870275 FF55_GeneralStatus 3 "Unlimited Driveing Pissible" 2 "Limited Driving Possible" 1 "Coldstart Low Temp" 0 "Coldstart Very Low Temp" ;
VAL_ 2566866179 FF45_GearHuntingProtectionState 3 "Not Available" 2 "Pre Active" 1 "Active" 0 "Not Active" ;
VAL_ 2566866179 FF45_OverspeedWarnTransOutput 3 "Not availabe" 2 "Error" 1 "Overspeed" 0 "No overspeed" ;
VAL_ 2566866179 FF45_OverspeedWarningTransInput 3 "Not availabe" 2 "Error" 1 "Overspeed" 0 "No overspeed" ;
VAL_ 2566866179 FF45_TrmSumpHeatState 4 "signal not available" 3 "heat class3" 2 "heat class2" 1 "heat class1" 0 "normal mode" ;
VAL_ 2566866179 FF45_TrmTemperatureLimitMode 4 "signal not available" 3 "deactivate" 2 "warm up phase" 1 "limited hydro dynamics" 0 "normal mode" ;
VAL_ 2566864899 FF40_BreakCondition 17 "Direction cluthc not closed" 16 "current too high" 15 "negative hydangle not reached" 14 "value hydpump start too low" 13 "value hydpump start too high" 12 "HYKtimeout Cal. time exceed " 11 "maxvalue hydro.angle not reched " 10 "avorted by internal failure" 9 "park brake not applied" 8 "Driver condition not fulfilled" 7 "Trans output speed not zero" 6 "no neutral request" 5 "trm oil sump temp. too low" 4 "trm oil sump temp. too high" 3 "eng. speed too low" 2 "eng. speed too high" 1 "aborted by user" 0 "All conditions fulfilled" ;
VAL_ 2566864899 FF40_GeneralStatus 3 "hydro cal. not active" 2 "hydro cal. not successful" 1 "hydro cal. successful" 0 "hydro calibration running" ;
VAL_ 2365542945 ZFTC1TrmRequestedGear 20 "SpeedRangeFourByForwardMode" 16 "SpeedRangeThreeByForwardMode" 7 "SpeedRangeTwoByForwardMode" 1 "SpeedRangeOneByForwardMode" -1 "SpeedRangeOneByReverseMode" -7 "SpeedRangeTwoByReverseMode" -16 "SpeedRangeThreeByReverseMode" -20 "SpeedRangeFourByReverseMode" ;
VAL_ 2365538819 ETC1TrmShiftInProcess 1 "Shift in process" 0 "Shift is not in process" ;
VAL_ 2365538819 ETC1TrmDrivelineEngaged 3 "Not available" 2 "Error" 1 "Driveline engaged" 0 "Driveline disengaged" ;
VAL_ 2348810243 TSC1OverrideControlModePriority 0 "Highest priority" 1 "High priority" 2 "Medium priority" 3 "Low priority" ;
VAL_ 2348810243 TSC1EngineOverrideCtrlMode 0 "Override disabled" 1 "Speed control" 2 "Torque control" 3 "Speed/torque limit control" ;
VAL_ 2565668608 TPCM_Mux 19 "EoMA" 32 "BAM" 255 "Abort" 17 "CTS" 16 "RTS" 24 "EAbort" 23 "EEoMACK" 22 "EDPO" 21 "ECTS" 20 "ERTS" ;
VAL_ 2565668608 PGNumber 255 "NotAvailable" ;
VAL_ 2633940480 EngineRotationDirection 0 "CounterClockWise (CCW)" 1 "ClockWise (CW)" 2 "Unknown (Rotation Direction Unknown)" 3 "Not Available" ;
VAL_ 2633940480 EngIntkManifoldPressureCtrlMode 0 "Open loop " 1 "Closed loop " 2 "SAE reserved" 3 "Not available" ;
VAL_ 2566804992 AftSlctiveCtlytcRedOprtrIndcmntA 0 "Off" 1 "On solid" 2 "reserved for SAE assignment" 3 "reserved for SAE assignment" 4 "On fast blink (1 Hz)" 5 "reserved for SAE assignment" 6 "reserved for SAE assignment" 7 "not available" ;
VAL_ 2566804992 AftrtrtmntSCROprtrIndcmntSvrty 0 "Driver Warning" 1 "Inducement Level 1" 2 "Inducement Level 2" 3 "Inducement Level 3" 4 "Inducement Level 4" 5 "Inducement Level 5" 6 "Temporary Override of Inducement" 7 "Not Available / Not Supported" ;
VAL_ 2566841344 EngIdleShutdownHasShutdownEngine 0 "No" 1 "Yes" 2 "Error" 3 "Not available" ;
VAL_ 2566841344 EngineIdleShutdownDrvrAlertMode 0 "Inactive" 1 "Active" 2 "Error" 3 "Not available" ;
VAL_ 2566841344 EngineIdleShutdownTimerOverride 0 "Inactive" 1 "Active" 2 "Error" 3 "Not available" ;
VAL_ 2566841344 EngineIdleShutdownTimerState 0 "Inactive" 1 "Active" 2 "Error" 3 "Not available" ;
VAL_ 2566841344 EngineIdleShutdownTimerFunction 0 "Disabled in calibration" 1 "Enabled in calibration" 2 "Error" 3 "Not available" ;
VAL_ 2566841344 ACHighPressureFanSwitch 0 "Pressure normal" 1 "Pressure high" 2 "Error" 3 "Not available" ;
VAL_ 2566841344 RefrigerantLowPressureSwitch 0 "Pressure normal" 1 "Pressure too low" 2 "Error" 3 "Not available" ;
VAL_ 2566841344 RefrigerantHighPressureSwitch 0 "Pressure normal" 1 "Pressure too high" 2 "Error" 3 "Not available" ;
VAL_ 2566841344 EngineWaitToStartLamp 0 "Off" 1 "On" 2 "Error" 3 "Not available" ;
VAL_ 2566841344 EngPrtctnSystemHasShutdownEng 0 "No" 1 "Yes" 2 "Error" 3 "Not available" ;
VAL_ 2566841344 EngPrtctnSystemApproachingShtdwn 0 "Not approaching" 1 "Approaching" 2 "Error" 3 "Not available" ;
VAL_ 2566841344 EngProtectionSystemTimerOverride 0 "Inactive" 1 "Active" 2 "Error" 3 "Not available" ;
VAL_ 2566841344 EngineProtectionSystemTimerState 0 "Inactive" 1 "Active" 2 "Error" 3 "Not available" ;
VAL_ 2566841344 EngineProtectionSystemConf 0 "Disabled in calibration" 1 "Enabled in calibration" 2 "Error" 3 "Not available" ;
VAL_ 2566841344 EngineAlarmAcknowledge 0 "Engine Alarm Acknowledge  Not Active " 1 "Engine Alarm Acknowledge Active" 2 "Error" 3 "Not Available" ;
VAL_ 2566841344 EngineAlarmOutputCommandStatus 0 "Engine Alarm Output Command Not Active" 1 "Engine Alarm Output Command Active" 2 "Reserved" 3 "Not Available" ;
VAL_ 2566841344 EngineAirShutoffCommandStatus 0 "Air Shutoff Disabled" 1 "Air Shutoff Enabled" 2 "Reserved" 3 "Not Available" ;
VAL_ 2566841344 EngineOverspeedTest 0 "Engine Overspeed Test Not Active" 1 "Engine Overspeed Test Active" 2 "Reserved" 3 "Not Available" ;
VAL_ 2566841344 EngineAirShutoffStatus 0 "Air flow allowed to engine" 1 "Air flow restricted" 2 "Error" 3 "Not Available" ;
VAL_ 2566841344 PTOShutdownHasShutdownEngine 0 "No" 1 "Yes" 2 "Error" 3 "Not available" ;
VAL_ 2566841344 CoolntLvlEngPrtctnShutdownStatus 0 "Disabled" 1 "Enabled" 2 "Reserved" 3 "Not Available" ;
VAL_ 2566848256 WaterInFuelIndicator1 0 "No" 1 "Yes" 2 "Error" 3 "Not available" ;
VAL_ 2566848256 OperatorShiftPrompt 0 "indicator(s) inactive" 1 "upshift indicator active" 2 "downshift indicator active" 3 "don't care/take no action" ;
VAL_ 2566848256 WaterInFuelIndicator2 0 "No" 1 "Yes" 2 "Error" 3 "Not available" ;
VAL_ 2566848256 DrvrWarningSystemIndicatorStatus 0 "Off" 1 "On - solid" 2 "reserved for SAE assignment" 3 "reserved for SAE assignment" 4 "On - fast blink (1 Hz)" 5 "reserved for SAE assignment" 6 "reserved for SAE assignment" 7 "not available" ;
VAL_ 2566848256 EmissionCtrlSysOprtrIndcmntSvrty 0 "Driver Warning" 1 "Inducement Level 1" 2 "Inducement Level 2" 3 "Inducement Level 3" 4 "Inducement Level 4" 5 "Inducement Level 5" 6 "Temporary Override of Inducement" 7 "Not Available / Not Supported" ;
VAL_ 2565865487 RetarderTorqueMode 0 "No request" ;
VAL_ 2565865487 RetarderEnableBrakeAssistSwitch 0 "Retarder - brake assist disabled" 1 "Retarder - brake assist enabled" 2 "Error" 3 "Not available" ;
VAL_ 2565865487 RetarderEnableShiftAssistSwitch 0 "Retarder - shift assist disabled" 1 "Retarder - shift assist enabled" 2 "Error" 3 "Not available" ;
VAL_ 2565865487 EngineCoolantLoadIncrease 0 "No coolant load increase" 1 "Coolant load increase possible" 2 "Error" 3 "Not available" ;
VAL_ 2565865487 RetarderRequestingBrakeLight 0 "Retarder is not requesting" 1 "Retarder is requesting" 2 "Reserved" 3 "Not available" ;
